VERSION ""

NS_ :

BS_:

BU_: L_DHRR_FD L_UWB_BLE_MST_FD L_UWB_RR_FD L_UWB_BLE_SLV_FD L_UWB_FR_FD L_ROA_FR_FD L_ROA_FD L_DHRL_FD L_UWB_TRNK_FD L_UWB_FRNK_FD L_EDT_FD L_UWB_FL_FD GW_BDC_FD L_UWB_RL_FD L_SAL_FD L_WPC_FD L_TPMS_FD L_DHL_FD L_DHR_FD

BO_ 849 IAU_FD_04_200ms: 32 GW_BDC_FD
 SG_ IAU_FD_Crc4Val : 0|16@1+ (1,0) [0|0] "0" Vector__XXX
 SG_ IAU_DISPWrng_Copy_0 : 104|4@1+ (1,0) [0|0] "" Vector__XXX
 SG_ IAU_DigitalKey2Opt_Copy_0 : 120|3@1+ (1,0) [0|0] "" Vector__XXX
 SG_ IAUwFRULearnState_Copy_0 : 124|2@1+ (1,0) [0|0] "" Vector__XXX
 SG_ IAUwFPMLearnState_Copy_0 : 126|2@1+ (1,0) [0|0] "" Vector__XXX
 SG_ IAU_ValetDigitalkey_Copy_0 : 128|2@1+ (1,0) [0|0] "" Vector__XXX
 SG_ IAU_DigitalKeyNumberOpt_Copy_0 : 130|3@1+ (1,0) [0|0] "" Vector__XXX
 SG_ IAU_eSEReprogramSta_Copy_0 : 133|2@1+ (1,0) [0|0] "" Vector__XXX
 SG_ IAU_DKOwnerSwapOption_Copy_0 : 136|2@1+ (1,0) [0|0] ""  L_UWB_BLE_MST_FD,L_UWB_BLE_SLV_FD,L_UWB_FL_FD,L_UWB_FRNK_FD,L_UWB_FR_FD,L_UWB_RL_FD,L_UWB_RR_FD,L_UWB_TRNK_FD,L_WPC_FD
 SG_ IAU_DgtKeyGrpPrflRval2_Copy_0 : 139|5@1+ (1,0) [0|0] "" Vector__XXX
 SG_ IAU_StartIdentifiedProfile_Copy_ : 144|3@1+ (1,0) [0|0] "" Vector__XXX
 SG_ IAU_DigitalKeyProfileRval2_Copy_ : 147|5@1+ (1,0) [0|0] "" Vector__XXX
 SG_ IAU_NFCCard1SN_Copy_0 : 152|32@1+ (1,0) [0|0] "" Vector__XXX
 SG_ IAU_FD_AlvCnt4Val : 16|8@1+ (1,0) [0|0] "0" Vector__XXX
 SG_ IAU_StartIdentifiedProfile_Ext : 24|4@1+ (1,0) [0|0] "" Vector__XXX
 SG_ RSPA_UWBRspaExtRngSta_Copy_0 : 246|2@1+ (1,0) [0|0] "" Vector__XXX
 SG_ RSPA_CanFltSta_Copy_0 : 250|2@1+ (1,0) [0|0] "" Vector__XXX
 SG_ RSPA_BLESigErrSta_Copy_0 : 252|2@1+ (1,0) [0|0] "" Vector__XXX
 SG_ RSPA_ConStat_Copy_0 : 254|2@1+ (1,0) [0|0] "" Vector__XXX
 SG_ IAU_ProfileIDRVal_Copy_0 : 74|4@1+ (1,0) [0|0] "" Vector__XXX
 SG_ IAU_DigitalKeyProcessingSta_Copy : 80|4@1+ (1,0) [0|0] "" Vector__XXX
 SG_ IAU_DigitalKeyExit_Copy_0 : 84|4@1+ (1,0) [0|0] "" Vector__XXX
 SG_ IAU_DigitalKeyEnblRVal_Copy_0 : 88|2@1+ (1,0) [0|0] ""  L_DHL_FD,L_DHRL_FD,L_DHRR_FD,L_DHR_FD,L_UWB_BLE_MST_FD,L_UWB_BLE_SLV_FD,L_UWB_FL_FD,L_UWB_FRNK_FD,L_UWB_FR_FD,L_UWB_RL_FD,L_UWB_RR_FD,L_UWB_TRNK_FD
 SG_ IAU_OwnerPhnRegRVal_Copy_0 : 90|2@1+ (1,0) [0|0] ""  L_DHL_FD,L_DHRL_FD,L_DHRR_FD,L_DHR_FD,L_UWB_BLE_MST_FD,L_UWB_BLE_SLV_FD,L_UWB_FL_FD,L_UWB_FRNK_FD,L_UWB_FR_FD,L_UWB_RL_FD,L_UWB_RR_FD,L_UWB_TRNK_FD,L_WPC_FD
 SG_ IAU_NFCCard1RegRVal_Copy_0 : 92|2@1+ (1,0) [0|0] "" Vector__XXX
 SG_ IAU_NFCCard2RegRVal_Copy_0 : 94|2@1+ (1,0) [0|0] "" Vector__XXX

BO_ 1338 UWB_TRNK_FD_30_500ms: 16 L_UWB_TRNK_FD
 SG_ UWB_TRNK_FD_Crc30Val : 0|16@1+ (1,0) [0|0] "" Vector__XXX
 SG_ UWB_TRNK_FD_AlvCnt30Val : 16|8@1+ (1,0) [0|0] "" Vector__XXX
 SG_ UWB_TRNK_ResetOpsta : 24|2@1+ (1,0) [0|0] ""  GW_BDC_FD

BO_ 2214592800 L_ROA_FD_02_00ms: 32 L_ROA_FD
 SG_ L_ROA_FD_Crc2Val : 0|16@1+ (1,0) [0|0] "0" Vector__XXX
 SG_ L_ROA_FD_AlvCnt2Val : 16|8@1+ (1,0) [0|0] "0" Vector__XXX
 SG_ ROABDC_DataByte0 : 24|8@1+ (1,0) [0|0] ""  GW_BDC_FD
 SG_ ROABDC_DataByte1 : 32|8@1+ (1,0) [0|0] ""  GW_BDC_FD
 SG_ ROABDC_DataByte2 : 40|8@1+ (1,0) [0|0] ""  GW_BDC_FD
 SG_ ROABDC_DataByte3 : 48|8@1+ (1,0) [0|0] ""  GW_BDC_FD
 SG_ ROABDC_DataByte4 : 56|8@1+ (1,0) [0|0] ""  GW_BDC_FD
 SG_ ROABDC_DataByte5 : 64|8@1+ (1,0) [0|0] ""  GW_BDC_FD
 SG_ ROABDC_DataByte6 : 72|8@1+ (1,0) [0|0] ""  GW_BDC_FD
 SG_ ROABDC_DataByte7 : 80|8@1+ (1,0) [0|0] ""  GW_BDC_FD

BO_ 1340 SAL_FD_01_500ms: 16 L_SAL_FD
 SG_ SAL_ResetOpsta : 24|2@1+ (1,0) [0|0] ""  GW_BDC_FD

BO_ 2214592802 L_ROA_FR_FD_02_00ms: 32 L_ROA_FR_FD
 SG_ L_ROA_FR_FD_Crc2Val : 0|16@1+ (1,0) [0|0] "0" Vector__XXX
 SG_ L_ROA_FR_FD_AlvCnt2Val : 16|8@1+ (1,0) [0|0] "0" Vector__XXX
 SG_ ROA_FRBDC_DataByte0 : 24|8@1+ (1,0) [0|0] ""  L_ROA_FD
 SG_ ROA_FRBDC_DataByte1 : 32|8@1+ (1,0) [0|0] ""  L_ROA_FD
 SG_ ROA_FRBDC_DataByte2 : 40|8@1+ (1,0) [0|0] ""  L_ROA_FD
 SG_ ROA_FRBDC_DataByte3 : 48|8@1+ (1,0) [0|0] ""  L_ROA_FD
 SG_ ROA_FRBDC_DataByte4 : 56|8@1+ (1,0) [0|0] ""  L_ROA_FD
 SG_ ROA_FRBDC_DataByte5 : 64|8@1+ (1,0) [0|0] ""  L_ROA_FD
 SG_ ROA_FRBDC_DataByte6 : 72|8@1+ (1,0) [0|0] ""  L_ROA_FD
 SG_ ROA_FRBDC_DataByte7 : 80|8@1+ (1,0) [0|0] ""  L_ROA_FD

BO_ 1329 ROA_FR_FD_03_500ms: 16 L_ROA_FR_FD
 SG_ ROA_FR_ResetOpSta_Copy_0 : 24|2@1+ (1,0) [0|0] ""  GW_BDC_FD

BO_ 1328 ROA_FD_03_500ms: 16 L_ROA_FD
 SG_ ROA_ResetOpSta_Copy_0 : 24|2@1+ (1,0) [0|0] ""  GW_BDC_FD

BO_ 1331 UWB_BLE_MST_FD_30_500ms: 16 L_UWB_BLE_MST_FD
 SG_ UWB_BLE_MST_FD_Crc30Val : 0|16@1+ (1,0) [0|0] "" Vector__XXX
 SG_ UWB_BLE_MST_FD_AlvCnt30Val : 16|8@1+ (1,0) [0|0] "" Vector__XXX
 SG_ UWB_BLE_MST_ResetOpsta : 24|2@1+ (1,0) [0|0] ""  GW_BDC_FD
 SG_ UWB_BLE_MST_DeviceConnectionChec : 26|2@1+ (1,0) [0|0] ""  GW_BDC_FD

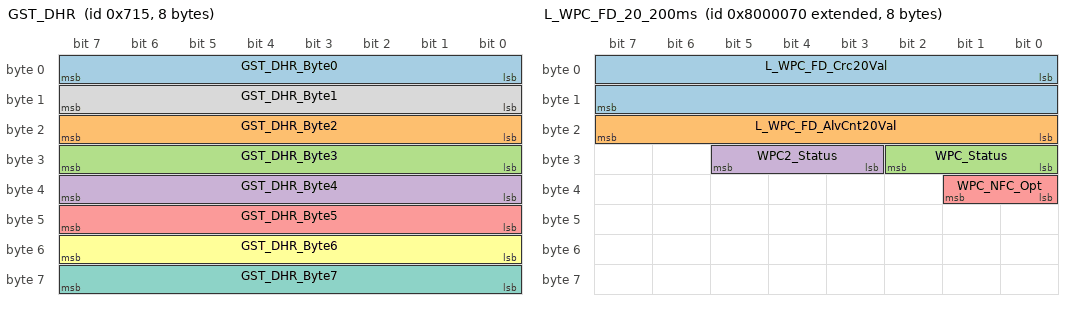
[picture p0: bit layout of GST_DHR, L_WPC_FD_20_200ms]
BO_ 1813 GST_DHR: 8 GW_BDC_FD
 SG_ GST_DHR_Byte0 : 0|8@1+ (1,0) [0|0] ""  L_DHR_FD
 SG_ GST_DHR_Byte2 : 16|8@1+ (1,0) [0|0] ""  L_DHR_FD
 SG_ GST_DHR_Byte3 : 24|8@1+ (1,0) [0|0] ""  L_DHR_FD
 SG_ GST_DHR_Byte4 : 32|8@1+ (1,0) [0|0] ""  L_DHR_FD
 SG_ GST_DHR_Byte5 : 40|8@1+ (1,0) [0|0] ""  L_DHR_FD
 SG_ GST_DHR_Byte6 : 48|8@1+ (1,0) [0|0] ""  L_DHR_FD
 SG_ GST_DHR_Byte7 : 56|8@1+ (1,0) [0|0] ""  L_DHR_FD
 SG_ GST_DHR_Byte1 : 8|8@1+ (1,0) [0|0] ""  L_DHR_FD

BO_ 1330 TPMS_FD_03_500ms: 16 L_TPMS_FD
 SG_ TPMS_FD_Crc3Val : 0|16@1+ (1,0) [0|0] "" Vector__XXX
 SG_ TPMS_FD_AlvCnt3Val : 16|8@1+ (1,0) [0|0] "" Vector__XXX
 SG_ TPMS_ResetOpsta : 24|2@1+ (1,0) [0|0] ""  GW_BDC_FD

BO_ 1333 UWB_FL_FD_30_500ms: 16 L_UWB_FL_FD
 SG_ UWB_FL_FD_Crc30Val : 0|16@1+ (1,0) [0|0] "" Vector__XXX
 SG_ UWB_FL_FD_AlvCnt30Val : 16|8@1+ (1,0) [0|0] "" Vector__XXX
 SG_ UWB_FL_ResetOpsta : 24|2@1+ (1,0) [0|0] ""  GW_BDC_FD

BO_ 1332 UWB_BLE_SLV_FD_30_500ms: 16 L_UWB_BLE_SLV_FD
 SG_ UWB_BLE_SLV_FD_Crc30Val : 0|16@1+ (1,0) [0|0] "" Vector__XXX
 SG_ UWB_BLE_SLV_FD_AlvCnt30Val : 16|8@1+ (1,0) [0|0] "" Vector__XXX
 SG_ UWB_BLE_SLV_ResetOpsta : 24|2@1+ (1,0) [0|0] ""  GW_BDC_FD
 SG_ UWB_BLE_SLV_DeviceConnectionChec : 26|2@1+ (1,0) [0|0] ""  GW_BDC_FD

BO_ 1335 UWB_FRNK_FD_30_500ms: 16 L_UWB_FRNK_FD
 SG_ UWB_FRNK_FD_Crc30Val : 0|16@1+ (1,0) [0|0] "" Vector__XXX
 SG_ UWB_FRNK_FD_AlvCnt30Val : 16|8@1+ (1,0) [0|0] "" Vector__XXX
 SG_ UWB_FRNK_ResetOpsta : 24|2@1+ (1,0) [0|0] ""  GW_BDC_FD

BO_ 2281701488 L_WPC_FD_20_200ms: 8 L_WPC_FD
 SG_ L_WPC_FD_Crc20Val : 0|16@1+ (1,0) [0|0] "0" Vector__XXX
 SG_ L_WPC_FD_AlvCnt20Val : 16|8@1+ (1,0) [0|0] "0" Vector__XXX
 SG_ WPC_Status : 24|3@1+ (1,0) [0|0] ""  GW_BDC_FD
 SG_ WPC2_Status : 27|3@1+ (1,0) [0|0] ""  GW_BDC_FD
 SG_ WPC_NFC_Opt : 32|2@1+ (1,0) [0|0] ""  GW_BDC_FD

BO_ 1334 UWB_FR_FD_30_500ms: 16 L_UWB_FR_FD
 SG_ UWB_FR_FD_Crc30Val : 0|16@1+ (1,0) [0|0] "" Vector__XXX
 SG_ UWB_FR_FD_AlvCnt30Val : 16|8@1+ (1,0) [0|0] "" Vector__XXX
 SG_ UWB_FR_ResetOpsta : 24|2@1+ (1,0) [0|0] ""  GW_BDC_FD

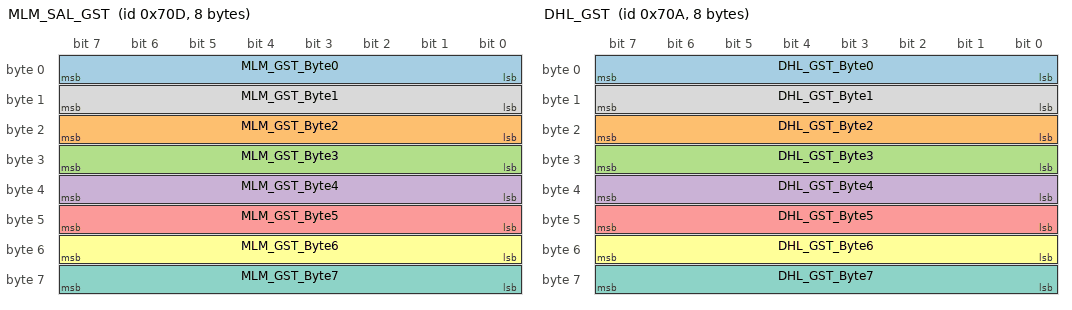
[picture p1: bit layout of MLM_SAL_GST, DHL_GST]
BO_ 1805 MLM_SAL_GST: 8 L_SAL_FD
 SG_ MLM_GST_Byte0 : 0|8@1+ (1,0) [0|0] ""  GW_BDC_FD
 SG_ MLM_GST_Byte2 : 16|8@1+ (1,0) [0|0] ""  GW_BDC_FD
 SG_ MLM_GST_Byte3 : 24|8@1+ (1,0) [0|0] ""  GW_BDC_FD
 SG_ MLM_GST_Byte4 : 32|8@1+ (1,0) [0|0] ""  GW_BDC_FD
 SG_ MLM_GST_Byte5 : 40|8@1+ (1,0) [0|0] ""  GW_BDC_FD
 SG_ MLM_GST_Byte6 : 48|8@1+ (1,0) [0|0] ""  GW_BDC_FD
 SG_ MLM_GST_Byte7 : 56|8@1+ (1,0) [0|0] ""  GW_BDC_FD
 SG_ MLM_GST_Byte1 : 8|8@1+ (1,0) [0|0] ""  GW_BDC_FD

BO_ 1802 DHL_GST: 8 L_DHL_FD
 SG_ DHL_GST_Byte0 : 0|8@1+ (1,0) [0|0] ""  GW_BDC_FD
 SG_ DHL_GST_Byte2 : 16|8@1+ (1,0) [0|0] ""  GW_BDC_FD
 SG_ DHL_GST_Byte3 : 24|8@1+ (1,0) [0|0] ""  GW_BDC_FD
 SG_ DHL_GST_Byte4 : 32|8@1+ (1,0) [0|0] ""  GW_BDC_FD
 SG_ DHL_GST_Byte5 : 40|8@1+ (1,0) [0|0] ""  GW_BDC_FD
 SG_ DHL_GST_Byte6 : 48|8@1+ (1,0) [0|0] ""  GW_BDC_FD
 SG_ DHL_GST_Byte7 : 56|8@1+ (1,0) [0|0] ""  GW_BDC_FD
 SG_ DHL_GST_Byte1 : 8|8@1+ (1,0) [0|0] ""  GW_BDC_FD

BO_ 2521142785 L_UWB_BLE_SLV_FD_10_00ms: 32 L_UWB_BLE_SLV_FD
 SG_ L_UWB_BLE_SLV_FD_Crc10Val : 0|16@1+ (1,0) [0|0] "" Vector__XXX
 SG_ L_UWB_BLE_SLV_FD_AlvCnt10Val : 16|8@1+ (1,0) [0|0] "" Vector__XXX
 SG_ SLV_SWID_2_IVD_2 : 24|24@1+ (1,0) [0|0] ""  L_UWB_BLE_MST_FD

BO_ 2533739009 L_UWB_FRNK_FD_06_00ms: 32 L_UWB_FRNK_FD
 SG_ L_UWB_FRNK_FD_Crc6Val : 0|16@1+ (1,0) [0|0] "" Vector__XXX
 SG_ L_UWB_FRNK_FD_AlvCnt6Val : 16|8@1+ (1,0) [0|0] "" Vector__XXX
 SG_ FRNK_SWID_4_IVD_1 : 24|232@1+ (1,0) [0|0] ""  L_UWB_BLE_MST_FD

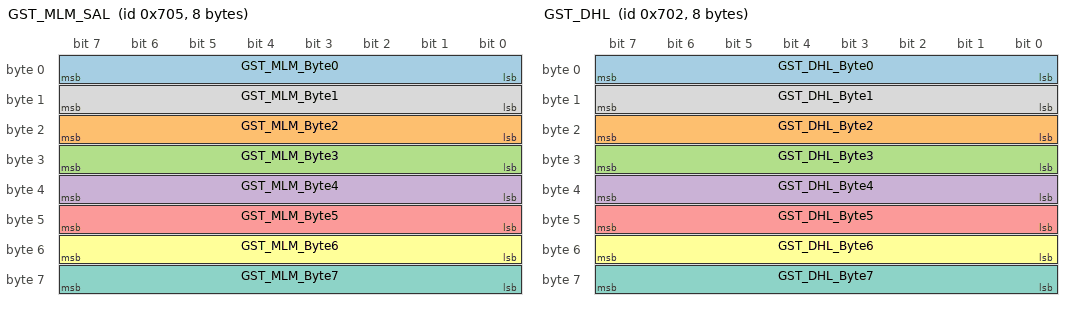
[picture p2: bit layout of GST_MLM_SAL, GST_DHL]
BO_ 1797 GST_MLM_SAL: 8 GW_BDC_FD
 SG_ GST_MLM_Byte0 : 0|8@1+ (1,0) [0|0] ""  L_SAL_FD
 SG_ GST_MLM_Byte2 : 16|8@1+ (1,0) [0|0] ""  L_SAL_FD
 SG_ GST_MLM_Byte3 : 24|8@1+ (1,0) [0|0] ""  L_SAL_FD
 SG_ GST_MLM_Byte4 : 32|8@1+ (1,0) [0|0] ""  L_SAL_FD
 SG_ GST_MLM_Byte5 : 40|8@1+ (1,0) [0|0] ""  L_SAL_FD
 SG_ GST_MLM_Byte6 : 48|8@1+ (1,0) [0|0] ""  L_SAL_FD
 SG_ GST_MLM_Byte7 : 56|8@1+ (1,0) [0|0] ""  L_SAL_FD
 SG_ GST_MLM_Byte1 : 8|8@1+ (1,0) [0|0] ""  L_SAL_FD

BO_ 2529540609 L_UWB_RR_FD_06_00ms: 32 L_UWB_RR_FD
 SG_ L_UWB_RR_FD_Crc6Val : 0|16@1+ (1,0) [0|0] "" Vector__XXX
 SG_ L_UWB_RR_FD_AlvCnt6Val : 16|8@1+ (1,0) [0|0] "" Vector__XXX
 SG_ RR_SWID_4_IVD_1 : 24|232@1+ (1,0) [0|0] ""  L_UWB_BLE_MST_FD

BO_ 1794 GST_DHL: 8 GW_BDC_FD
 SG_ GST_DHL_Byte0 : 0|8@1+ (1,0) [0|0] ""  L_DHL_FD
 SG_ GST_DHL_Byte2 : 16|8@1+ (1,0) [0|0] ""  L_DHL_FD
 SG_ GST_DHL_Byte3 : 24|8@1+ (1,0) [0|0] ""  L_DHL_FD
 SG_ GST_DHL_Byte4 : 32|8@1+ (1,0) [0|0] ""  L_DHL_FD
 SG_ GST_DHL_Byte5 : 40|8@1+ (1,0) [0|0] ""  L_DHL_FD
 SG_ GST_DHL_Byte6 : 48|8@1+ (1,0) [0|0] ""  L_DHL_FD
 SG_ GST_DHL_Byte7 : 56|8@1+ (1,0) [0|0] ""  L_DHL_FD
 SG_ GST_DHL_Byte1 : 8|8@1+ (1,0) [0|0] ""  L_DHL_FD

BO_ 362 ADAS_PRK_21_20ms: 32 GW_BDC_FD
 SG_ ADAS_PRK_Crc3Val : 0|16@1+ (1,0) [0|0] "" Vector__XXX
 SG_ RSPA_Var : 112|4@1+ (1,0) [0|0] "" Vector__XXX
 SG_ MRA_FuncEquipSta : 116|4@1+ (1,0) [0|0] "" Vector__XXX
 SG_ RSPA_Sta : 120|4@1+ (1,0) [0|0] "" Vector__XXX
 SG_ RSPA_Actv : 124|2@1+ (1,0) [0|0] "" Vector__XXX
 SG_ RSPA_EntryFuncBtnDispSta : 126|2@1+ (1,0) [0|0] "" Vector__XXX
 SG_ RSPA_TrgtGearSta : 128|3@1+ (1,0) [0|0] "" Vector__XXX
 SG_ RSPA_EpbReq : 131|2@1+ (1,0) [0|0] "" Vector__XXX
 SG_ RSPA_ExtLampReq : 133|3@1+ (1,0) [0|0] "" Vector__XXX
 SG_ RSPA_CrankingReq : 136|2@1+ (1,0) [0|0] "" Vector__XXX
 SG_ RSPA_IdOutWarnReq : 138|2@1+ (1,0) [0|0] "" Vector__XXX
 SG_ RSPA_IndBlnkReq : 140|3@1+ (1,0) [0|0] "" Vector__XXX
 SG_ RSPA_SysOff : 143|1@1+ (1,0) [0|0] "" Vector__XXX
 SG_ RSPA_DccCmd : 144|2@1+ (1,0) [0|0] "" Vector__XXX
 SG_ RSPA_StopReq : 146|2@1+ (1,0) [0|0] "" Vector__XXX
 SG_ RSPA_SelDevInfo : 148|2@1+ (1,0) [0|0] "" Vector__XXX
 SG_ RSPA_SelFuncSta : 150|2@1+ (1,0) [0|0] "" Vector__XXX
 SG_ RSPA_TrgtVehSpdVal : 152|10@1+ (0.01,0) [0|0] "km/h" Vector__XXX
 SG_ ADAS_PRK_AlvCnt3Val : 16|8@1+ (1,0) [0|0] "" Vector__XXX
 SG_ RSPA_AddtnlAccelActv : 162|2@1+ (1,0) [0|0] "" Vector__XXX
 SG_ RSPA_Opt : 164|2@1+ (1,0) [0|0] ""  L_UWB_BLE_MST_FD
 SG_ RSPA_TrgtTqVal : 168|12@1- (1,0) [0|0] "Nm" Vector__XXX
 SG_ RSPA_UppLtTypDis : 180|3@1+ (1,0) [0|0] "" Vector__XXX
 SG_ RSPA_LwrLtTypDis : 183|3@1+ (1,0) [0|0] "" Vector__XXX
 SG_ RSPA_UppRtTypDis : 186|3@1+ (1,0) [0|0] "" Vector__XXX
 SG_ RSPA_LwrRtTypDis : 189|3@1+ (1,0) [0|0] "" Vector__XXX
 SG_ RSPA_DCTTrgtTqVal : 192|12@1- (1,0) [0|0] "Nm" Vector__XXX
 SG_ MRA_BtnDispSta : 204|4@1+ (1,0) [0|0] "" Vector__XXX
 SG_ RSPA_AvnDis : 24|2@1+ (1,0) [0|0] "" Vector__XXX
 SG_ RSPA_HdLmpReq : 240|2@1+ (1,0) [0|0] "" Vector__XXX
 SG_ MRA_CamDispSta : 242|3@1+ (1,0) [0|0] "" Vector__XXX
 SG_ RSPA_BtnDispSta : 245|3@1+ (1,0) [0|0] "" Vector__XXX
 SG_ RSPA_OSMirFoldReq : 248|2@1+ (1,0) [0|0] "" Vector__XXX
 SG_ RSPA_AvnModDis : 26|2@1+ (1,0) [0|0] "" Vector__XXX
 SG_ RSPA_AvnSubViewDis : 32|2@1+ (1,0) [0|0] "" Vector__XXX
 SG_ MRA_AVNDispSta : 48|2@1+ (1,0) [0|0] "" Vector__XXX
 SG_ RSPA_DgtKeyVer : 53|3@1+ (1,0) [0|0] "" Vector__XXX
 SG_ RSPA_AvnHmiDis : 56|8@1+ (1,0) [0|0] "" Vector__XXX
 SG_ MRA_AVNHMIDispSta : 64|8@1+ (1,0) [0|0] "" Vector__XXX
 SG_ RSPA_RWS_AnglReq : 72|8@1+ (0.1,-12.7) [0|0] "Degree" Vector__XXX

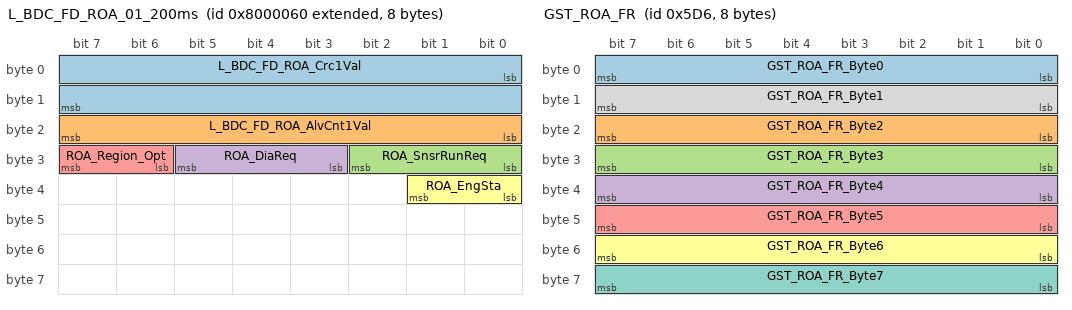
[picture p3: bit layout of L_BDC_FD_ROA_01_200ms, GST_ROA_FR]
BO_ 2281701472 L_BDC_FD_ROA_01_200ms: 8 GW_BDC_FD
 SG_ L_BDC_FD_ROA_Crc1Val : 0|16@1+ (1,0) [0|0] "0" Vector__XXX
 SG_ L_BDC_FD_ROA_AlvCnt1Val : 16|8@1+ (1,0) [0|0] "0" Vector__XXX
 SG_ ROA_SnsrRunReq : 24|3@1+ (1,0) [0|0] ""  L_ROA_FD,L_ROA_FR_FD
 SG_ ROA_DiaReq : 27|3@1+ (1,0) [0|0] ""  L_ROA_FD,L_ROA_FR_FD
 SG_ ROA_Region_Opt : 30|2@1+ (1,0) [0|0] ""  L_ROA_FD,L_ROA_FR_FD
 SG_ ROA_EngSta : 32|2@1+ (1,0) [0|0] ""  L_ROA_FD,L_ROA_FR_FD,L_UWB_BLE_MST_FD,L_UWB_BLE_SLV_FD

BO_ 2683310288 L_ROA_FR_FD_Debug_01: 32 L_ROA_FR_FD
 SG_ ROA_FR_Debug_00 : 0|64@1+ (1,0) [0|0] "" Vector__XXX
 SG_ ROA_FR_Debug_02 : 128|64@1+ (1,0) [0|0] "" Vector__XXX
 SG_ ROA_FR_Debug_03 : 192|64@1+ (1,0) [0|0] "" Vector__XXX
 SG_ ROA_FR_Debug_01 : 64|64@1+ (1,0) [0|0] "" Vector__XXX

BO_ 1494 GST_ROA_FR: 8 GW_BDC_FD
 SG_ GST_ROA_FR_Byte0 : 0|8@1+ (1,0) [0|0] ""  L_ROA_FR_FD
 SG_ GST_ROA_FR_Byte2 : 16|8@1+ (1,0) [0|0] ""  L_ROA_FR_FD
 SG_ GST_ROA_FR_Byte3 : 24|8@1+ (1,0) [0|0] ""  L_ROA_FR_FD
 SG_ GST_ROA_FR_Byte4 : 32|8@1+ (1,0) [0|0] ""  L_ROA_FR_FD
 SG_ GST_ROA_FR_Byte5 : 40|8@1+ (1,0) [0|0] ""  L_ROA_FR_FD
 SG_ GST_ROA_FR_Byte6 : 48|8@1+ (1,0) [0|0] ""  L_ROA_FR_FD
 SG_ GST_ROA_FR_Byte7 : 56|8@1+ (1,0) [0|0] ""  L_ROA_FR_FD
 SG_ GST_ROA_FR_Byte1 : 8|8@1+ (1,0) [0|0] ""  L_ROA_FR_FD

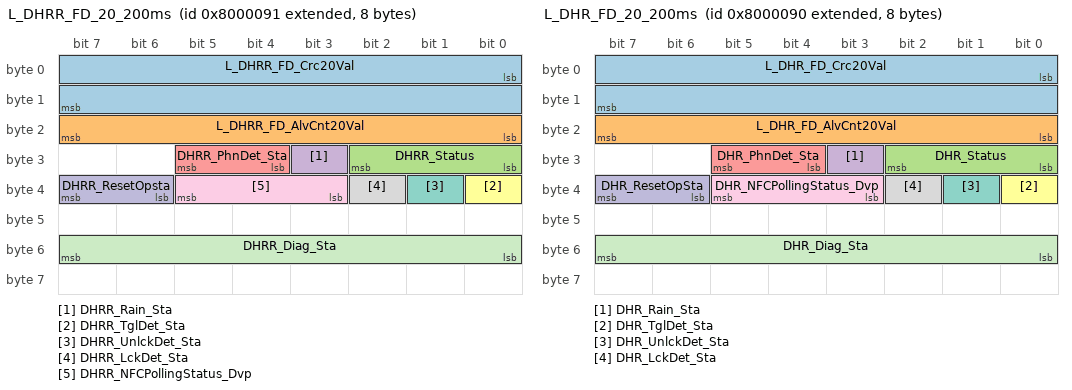
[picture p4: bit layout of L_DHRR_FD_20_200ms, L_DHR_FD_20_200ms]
BO_ 2281701521 L_DHRR_FD_20_200ms: 8 L_DHRR_FD
 SG_ L_DHRR_FD_Crc20Val : 0|16@1+ (1,0) [0|0] "0" Vector__XXX
 SG_ L_DHRR_FD_AlvCnt20Val : 16|8@1+ (1,0) [0|0] "0" Vector__XXX
 SG_ DHRR_Status : 24|3@1+ (1,0) [0|0] ""  GW_BDC_FD
 SG_ DHRR_Rain_Sta : 27|1@1+ (1,0) [0|0] ""  GW_BDC_FD
 SG_ DHRR_PhnDet_Sta : 28|2@1+ (1,0) [0|0] ""  GW_BDC_FD
 SG_ DHRR_TglDet_Sta : 32|1@1+ (1,0) [0|0] ""  GW_BDC_FD,L_UWB_BLE_MST_FD
 SG_ DHRR_UnlckDet_Sta : 33|1@1+ (1,0) [0|0] ""  GW_BDC_FD,L_UWB_BLE_MST_FD
 SG_ DHRR_LckDet_Sta : 34|1@1+ (1,0) [0|0] ""  GW_BDC_FD,L_UWB_BLE_MST_FD
 SG_ DHRR_NFCPollingStatus_Dvp : 35|3@1+ (1,0) [0|0] ""  GW_BDC_FD
 SG_ DHRR_ResetOpsta : 38|2@1+ (1,0) [0|0] ""  GW_BDC_FD
 SG_ DHRR_Diag_Sta : 48|8@1+ (1,0) [0|0] ""  GW_BDC_FD

BO_ 2683310289 L_ROA_FR_FD_Debug_02: 32 L_ROA_FR_FD
 SG_ ROA_FR_Debug_04 : 0|64@1+ (1,0) [0|0] "" Vector__XXX
 SG_ ROA_FR_Debug_06 : 128|64@1+ (1,0) [0|0] "" Vector__XXX
 SG_ ROA_FR_Debug_07 : 192|64@1+ (1,0) [0|0] "" Vector__XXX
 SG_ ROA_FR_Debug_05 : 64|64@1+ (1,0) [0|0] "" Vector__XXX

BO_ 2281701520 L_DHR_FD_20_200ms: 8 L_DHR_FD
 SG_ L_DHR_FD_Crc20Val : 0|16@1+ (1,0) [0|0] "0" Vector__XXX
 SG_ L_DHR_FD_AlvCnt20Val : 16|8@1+ (1,0) [0|0] "0" Vector__XXX
 SG_ DHR_Status : 24|3@1+ (1,0) [0|0] ""  GW_BDC_FD
 SG_ DHR_Rain_Sta : 27|1@1+ (1,0) [0|0] ""  GW_BDC_FD
 SG_ DHR_PhnDet_Sta : 28|2@1+ (1,0) [0|0] ""  GW_BDC_FD
 SG_ DHR_TglDet_Sta : 32|1@1+ (1,0) [0|0] ""  GW_BDC_FD,L_UWB_BLE_MST_FD
 SG_ DHR_UnlckDet_Sta : 33|1@1+ (1,0) [0|0] ""  GW_BDC_FD,L_UWB_BLE_MST_FD
 SG_ DHR_LckDet_Sta : 34|1@1+ (1,0) [0|0] ""  GW_BDC_FD,L_UWB_BLE_MST_FD
 SG_ DHR_NFCPollingStatus_Dvp : 35|3@1+ (1,0) [0|0] ""  GW_BDC_FD
 SG_ DHR_ResetOpSta : 38|2@1+ (1,0) [0|0] ""  GW_BDC_FD
 SG_ DHR_Diag_Sta : 48|8@1+ (1,0) [0|0] ""  GW_BDC_FD

BO_ 2683310290 L_ROA_FR_FD_Debug_03: 8 L_ROA_FR_FD
 SG_ ROA_FR_Debug_08 : 0|64@1+ (1,0) [0|0] "" Vector__XXX

BO_ 2521143297 L_UWB_BLE_SLV_FD_12_00ms: 32 L_UWB_BLE_SLV_FD
 SG_ L_UWB_BLE_SLV_FD_Crc12Val : 0|16@1+ (1,0) [0|0] "" Vector__XXX
 SG_ L_UWB_BLE_SLV_FD_AlvCnt12Val : 16|8@1+ (1,0) [0|0] "" Vector__XXX
 SG_ SLV_SWID_3_IVD_2 : 24|24@1+ (1,0) [0|0] ""  L_UWB_BLE_MST_FD

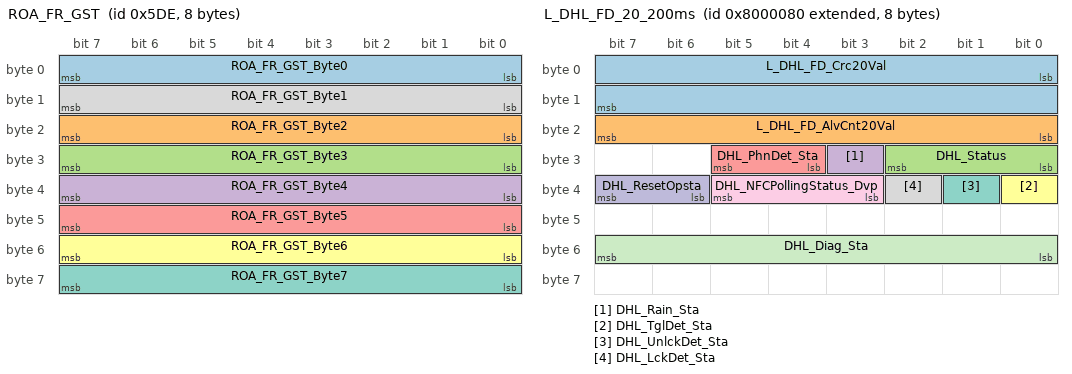
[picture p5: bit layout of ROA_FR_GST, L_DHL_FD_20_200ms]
BO_ 1502 ROA_FR_GST: 8 L_ROA_FR_FD
 SG_ ROA_FR_GST_Byte0 : 0|8@1+ (1,0) [0|0] ""  GW_BDC_FD
 SG_ ROA_FR_GST_Byte2 : 16|8@1+ (1,0) [0|0] ""  GW_BDC_FD
 SG_ ROA_FR_GST_Byte3 : 24|8@1+ (1,0) [0|0] ""  GW_BDC_FD
 SG_ ROA_FR_GST_Byte4 : 32|8@1+ (1,0) [0|0] ""  GW_BDC_FD
 SG_ ROA_FR_GST_Byte5 : 40|8@1+ (1,0) [0|0] ""  GW_BDC_FD
 SG_ ROA_FR_GST_Byte6 : 48|8@1+ (1,0) [0|0] ""  GW_BDC_FD
 SG_ ROA_FR_GST_Byte7 : 56|8@1+ (1,0) [0|0] ""  GW_BDC_FD
 SG_ ROA_FR_GST_Byte1 : 8|8@1+ (1,0) [0|0] ""  GW_BDC_FD

BO_ 2683310273 L_ROA_FR_FD_Dev_01: 8 L_ROA_FR_FD
 SG_ ROA_FR_Dev_01 : 0|64@1+ (1,0) [0|0] "" Vector__XXX

BO_ 2281701504 L_DHL_FD_20_200ms: 8 L_DHL_FD
 SG_ L_DHL_FD_Crc20Val : 0|16@1+ (1,0) [0|0] "0" Vector__XXX
 SG_ L_DHL_FD_AlvCnt20Val : 16|8@1+ (1,0) [0|0] "0" Vector__XXX
 SG_ DHL_Status : 24|3@1+ (1,0) [0|0] ""  GW_BDC_FD
 SG_ DHL_Rain_Sta : 27|1@1+ (1,0) [0|0] ""  GW_BDC_FD
 SG_ DHL_PhnDet_Sta : 28|2@1+ (1,0) [0|0] ""  GW_BDC_FD
 SG_ DHL_TglDet_Sta : 32|1@1+ (1,0) [0|0] ""  GW_BDC_FD,L_UWB_BLE_MST_FD
 SG_ DHL_UnlckDet_Sta : 33|1@1+ (1,0) [0|0] ""  GW_BDC_FD,L_UWB_BLE_MST_FD
 SG_ DHL_LckDet_Sta : 34|1@1+ (1,0) [0|0] ""  GW_BDC_FD,L_UWB_BLE_MST_FD
 SG_ DHL_NFCPollingStatus_Dvp : 35|3@1+ (1,0) [0|0] ""  GW_BDC_FD
 SG_ DHL_ResetOpsta : 38|2@1+ (1,0) [0|0] ""  GW_BDC_FD
 SG_ DHL_Diag_Sta : 48|8@1+ (1,0) [0|0] ""  GW_BDC_FD

BO_ 2683310272 L_ROA_FR_FD_Dev_00: 8 L_ROA_FR_FD
 SG_ ROA_FR_Dev_00 : 0|64@1+ (1,0) [0|0] "" Vector__XXX

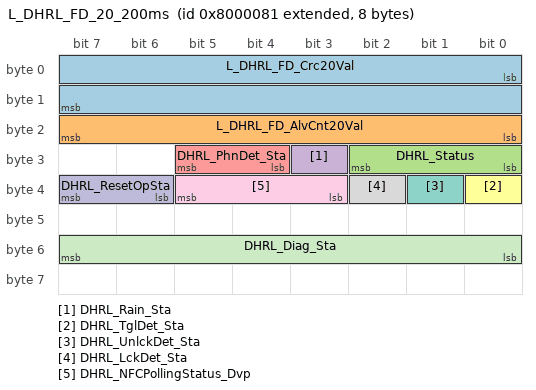
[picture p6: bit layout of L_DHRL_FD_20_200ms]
BO_ 2281701505 L_DHRL_FD_20_200ms: 8 L_DHRL_FD
 SG_ L_DHRL_FD_Crc20Val : 0|16@1+ (1,0) [0|0] "0" Vector__XXX
 SG_ L_DHRL_FD_AlvCnt20Val : 16|8@1+ (1,0) [0|0] "0" Vector__XXX
 SG_ DHRL_Status : 24|3@1+ (1,0) [0|0] ""  GW_BDC_FD
 SG_ DHRL_Rain_Sta : 27|1@1+ (1,0) [0|0] ""  GW_BDC_FD
 SG_ DHRL_PhnDet_Sta : 28|2@1+ (1,0) [0|0] ""  GW_BDC_FD
 SG_ DHRL_TglDet_Sta : 32|1@1+ (1,0) [0|0] ""  GW_BDC_FD,L_UWB_BLE_MST_FD
 SG_ DHRL_UnlckDet_Sta : 33|1@1+ (1,0) [0|0] ""  GW_BDC_FD,L_UWB_BLE_MST_FD
 SG_ DHRL_LckDet_Sta : 34|1@1+ (1,0) [0|0] ""  GW_BDC_FD,L_UWB_BLE_MST_FD
 SG_ DHRL_NFCPollingStatus_Dvp : 35|3@1+ (1,0) [0|0] ""  GW_BDC_FD
 SG_ DHRL_ResetOpSta : 38|2@1+ (1,0) [0|0] ""  GW_BDC_FD
 SG_ DHRL_Diag_Sta : 48|8@1+ (1,0) [0|0] ""  GW_BDC_FD

BO_ 2683310275 L_ROA_FR_FD_Dev_03: 8 L_ROA_FR_FD
 SG_ ROA_FR_Dev_03 : 0|64@1+ (1,0) [0|0] "" Vector__XXX

BO_ 2683310274 L_ROA_FR_FD_Dev_02: 8 L_ROA_FR_FD
 SG_ ROA_FR_Dev_02 : 0|64@1+ (1,0) [0|0] "" Vector__XXX

BO_ 2683310277 L_ROA_FR_FD_Dev_05: 8 L_ROA_FR_FD
 SG_ ROA_FR_Dev_05 : 0|64@1+ (1,0) [0|0] "" Vector__XXX

BO_ 2525340417 L_UWB_FL_FD_07_00ms: 32 L_UWB_FL_FD
 SG_ L_UWB_FL_FD_Crc7Val : 0|16@1+ (1,0) [0|0] "" Vector__XXX
 SG_ L_UWB_FL_FD_AlvCnt7Val : 16|8@1+ (1,0) [0|0] "" Vector__XXX
 SG_ FL_SWID_4_IVD_2 : 24|24@1+ (1,0) [0|0] ""  L_UWB_BLE_MST_FD

BO_ 2683310276 L_ROA_FR_FD_Dev_04: 8 L_ROA_FR_FD
 SG_ ROA_FR_Dev_04 : 0|64@1+ (1,0) [0|0] "" Vector__XXX

BO_ 2683310279 L_ROA_FR_FD_Dev_07: 8 L_ROA_FR_FD
 SG_ ROA_FR_Dev_07 : 0|64@1+ (1,0) [0|0] "" Vector__XXX

BO_ 2683310278 L_ROA_FR_FD_Dev_06: 8 L_ROA_FR_FD
 SG_ ROA_FR_Dev_06 : 0|64@1+ (1,0) [0|0] "" Vector__XXX

BO_ 2683310281 L_ROA_FR_FD_Dev_09: 8 L_ROA_FR_FD
 SG_ ROA_FR_Dev_09 : 0|64@1+ (1,0) [0|0] "" Vector__XXX

BO_ 2683310280 L_ROA_FR_FD_Dev_08: 8 L_ROA_FR_FD
 SG_ ROA_FR_Dev_08 : 0|64@1+ (1,0) [0|0] "" Vector__XXX

BO_ 2683310282 L_ROA_FR_FD_Dev_10: 8 L_ROA_FR_FD
 SG_ ROA_FR_Dev_10 : 0|64@1+ (1,0) [0|0] "" Vector__XXX

BO_ 2521143809 L_UWB_BLE_SLV_FD_14_00ms: 32 L_UWB_BLE_SLV_FD
 SG_ L_UWB_BLE_SLV_FD_Crc14Val : 0|16@1+ (1,0) [0|0] "" Vector__XXX
 SG_ L_UWB_BLE_SLV_FD_AlvCnt14Val : 16|8@1+ (1,0) [0|0] "" Vector__XXX
 SG_ SLV_SWID_4_IVD_2 : 24|24@1+ (1,0) [0|0] ""  L_UWB_BLE_MST_FD

BO_ 2281701553 L_UWB_BLE_SLV_FD_21_200ms: 24 L_UWB_BLE_SLV_FD
 SG_ L_UWB_BLE_SLV_FD_Crc21Val : 0|16@1+ (1,0) [0|0] "0" Vector__XXX
 SG_ SLV_SW_MCU_Ver_Major : 104|8@1+ (1,0) [0|0] ""  L_UWB_BLE_MST_FD
 SG_ SLV_SW_MCU_Ver_Minor : 112|8@1+ (1,0) [0|0] ""  L_UWB_BLE_MST_FD
 SG_ SLV_SW_UWB_Ver_Major : 120|8@1+ (1,0) [0|0] ""  L_UWB_BLE_MST_FD
 SG_ SLV_SW_UWB_Ver_Minor : 128|8@1+ (1,0) [0|0] ""  L_UWB_BLE_MST_FD
 SG_ SLV_SW_BLE_Ver_Major : 136|8@1+ (1,0) [0|0] ""  L_UWB_BLE_MST_FD
 SG_ SLV_SW_BLE_Ver_Minor : 144|8@1+ (1,0) [0|0] ""  L_UWB_BLE_MST_FD
 SG_ SLV_DTC : 152|8@1+ (1,0) [0|0] ""  L_UWB_BLE_MST_FD
 SG_ L_UWB_BLE_SLV_FD_AlvCnt21Val : 16|8@1+ (1,0) [0|0] "0" Vector__XXX
 SG_ SLV_DTC_BLE : 160|8@1+ (1,0) [0|0] ""  L_UWB_BLE_MST_FD
 SG_ SLV_UWB_Status1 : 24|4@1+ (1,0) [0|7] ""  GW_BDC_FD,L_UWB_BLE_MST_FD
 SG_ SLV_UWB_Status2 : 28|4@1+ (1,0) [0|0] ""  GW_BDC_FD,L_UWB_BLE_MST_FD
 SG_ SLV_UWB_Status3 : 32|4@1+ (1,0) [0|0] ""  GW_BDC_FD,L_UWB_BLE_MST_FD
 SG_ SLV_UWB_Status4 : 36|4@1+ (1,0) [0|0] ""  GW_BDC_FD,L_UWB_BLE_MST_FD
 SG_ SLV_UWB_Status5 : 40|4@1+ (1,0) [0|0] ""  GW_BDC_FD,L_UWB_BLE_MST_FD
 SG_ SLV_UWB_Status6 : 44|4@1+ (1,0) [0|0] ""  GW_BDC_FD,L_UWB_BLE_MST_FD
 SG_ SLV_UWB_Status7 : 48|4@1+ (1,0) [0|0] ""  GW_BDC_FD,L_UWB_BLE_MST_FD
 SG_ SLV_UWB_Status8 : 52|4@1+ (1,0) [0|0] ""  GW_BDC_FD,L_UWB_BLE_MST_FD
 SG_ SLV_UWB_Status9 : 56|4@1+ (1,0) [0|0] ""  GW_BDC_FD,L_UWB_BLE_MST_FD
 SG_ SLV_UWB_Status10 : 60|4@1+ (1,0) [0|0] ""  GW_BDC_FD,L_UWB_BLE_MST_FD
 SG_ SLV_UWB_Status11 : 64|4@1+ (1,0) [0|0] ""  GW_BDC_FD,L_UWB_BLE_MST_FD
 SG_ SLV_UWB_Status12 : 68|4@1+ (1,0) [0|0] ""  GW_BDC_FD,L_UWB_BLE_MST_FD
 SG_ SLV_UWB_Status13 : 72|4@1+ (1,0) [0|0] ""  GW_BDC_FD,L_UWB_BLE_MST_FD
 SG_ SLV_UWB_Status14 : 76|4@1+ (1,0) [0|0] ""  GW_BDC_FD,L_UWB_BLE_MST_FD
 SG_ SLV_UWB_Status15 : 80|4@1+ (1,0) [0|0] ""  GW_BDC_FD,L_UWB_BLE_MST_FD
 SG_ SLV_UWB_Status16 : 84|4@1+ (1,0) [0|0] ""  GW_BDC_FD,L_UWB_BLE_MST_FD
 SG_ SLV_HW_Ver_Major : 88|8@1+ (1,0) [0|0] ""  L_UWB_BLE_MST_FD
 SG_ SLV_HW_Ver_Minor : 96|8@1+ (1,0) [0|0] ""  L_UWB_BLE_MST_FD

CM_ BO_ 849 "[PE] Periodic and On Event";
CM_ SG_ 849 IAU_FD_Crc4Val "IAU_FD_CyclicRedundancyCheck4Value";
CM_ SG_ 849 IAU_DigitalKey2Opt_Copy_0 "Digital Key2 Option Signal";
CM_ SG_ 849 IAU_ValetDigitalkey_Copy_0 "Digital Key Valet Mode";
CM_ SG_ 849 IAU_DigitalKeyNumberOpt_Copy_0 "This signal is for the digital key number type.";
CM_ SG_ 849 IAU_eSEReprogramSta_Copy_0 "this signal is to mornitor the state of eSE reprograming.";
CM_ SG_ 849 IAU_DgtKeyGrpPrflRval2_Copy_0 "This signal indiactes digital key group number paired with selected profile";
CM_ SG_ 849 IAU_StartIdentifiedProfile_Copy_ "This signal Indicate Profile of vehicle start Identified";
CM_ SG_ 849 IAU_DigitalKeyProfileRval2_Copy_ "This signal indiactes digital key number paired with selected profile";
CM_ SG_ 849 IAU_FD_AlvCnt4Val "IAU_FD_AliveCounter4Value";
CM_ SG_ 849 IAU_StartIdentifiedProfile_Ext "This signal indicate Profile of vehicle start Identified";
CM_ SG_ 849 RSPA_UWBRspaExtRngSta_Copy_0 "RSPA remote control range of UWB";
CM_ SG_ 849 RSPA_CanFltSta_Copy_0 "RSPA_CANErrorState";
CM_ SG_ 849 RSPA_BLESigErrSta_Copy_0 "RSPA_RFSignalErrorState";
CM_ SG_ 849 IAU_ProfileIDRVal_Copy_0 "This signal Indicate the Current detected Profile ID by IAU.";
CM_ SG_ 849 IAU_DigitalKeyProcessingSta_Copy "Digital Key USM settitng Process State";
CM_ SG_ 849 IAU_DigitalKeyExit_Copy_0 "Digital Key USM setting Exit Condition";
CM_ SG_ 849 IAU_DigitalKeyEnblRVal_Copy_0 "Digital Key Function Enable / Disable flag (Fob is required for changing flag)";
CM_ SG_ 849 IAU_OwnerPhnRegRVal_Copy_0 "Vehicle Owner's Phone is Registered for Digital Key function";
CM_ SG_ 849 IAU_NFCCard1RegRVal_Copy_0 "NFC Card 1 is Registered for Digital Key function";
CM_ SG_ 849 IAU_NFCCard2RegRVal_Copy_0 "NFC Card 2 is Registered for Digital Key function";
CM_ BO_ 1338 "[PE] Periodic and On Event";
CM_ SG_ 1338 UWB_TRNK_FD_Crc30Val "UWB_TRNK_FD_CyclicRedundancyCheck30Value";
CM_ SG_ 1338 UWB_TRNK_FD_AlvCnt30Val "UWB_TRNK_FD_AliveCounter30Value";
CM_ SG_ 1338 UWB_TRNK_ResetOpsta "This signal indicates whether the reset operation has been completed or not";
CM_ BO_ 2214592800 "[EW] On Event and On Write";
CM_ SG_ 2214592800 L_ROA_FD_Crc2Val "L_ROA_FD_CyclicRedundancyCheck2Value";
CM_ SG_ 2214592800 L_ROA_FD_AlvCnt2Val "L_ROA_FD_AliveCounter2Value";
CM_ SG_ 2214592800 ROABDC_DataByte0 "Response of Parameter Update";
CM_ SG_ 2214592800 ROABDC_DataByte1 "Response of Parameter Update";
CM_ SG_ 2214592800 ROABDC_DataByte2 "Response of Parameter Update";
CM_ SG_ 2214592800 ROABDC_DataByte3 "Response of Parameter Update";
CM_ SG_ 2214592800 ROABDC_DataByte4 "Response of Parameter Update";
CM_ SG_ 2214592800 ROABDC_DataByte5 "Response of Parameter Update";
CM_ SG_ 2214592800 ROABDC_DataByte6 "Response of Parameter Update";
CM_ SG_ 2214592800 ROABDC_DataByte7 "Response of Parameter Update";
CM_ BO_ 1340 "[PE] Periodic and On Event";
CM_ SG_ 1340 SAL_ResetOpsta "This signal indicates whether the reset operation has been completed or not";
CM_ BO_ 2214592802 "[EW] On Event and On Write";
CM_ SG_ 2214592802 L_ROA_FR_FD_Crc2Val "L_ROA_FR_FD_CyclicRedundancyCheck2Value";
CM_ SG_ 2214592802 L_ROA_FR_FD_AlvCnt2Val "L_ROA_FR_FD_AliveCounter2Value";
CM_ SG_ 2214592802 ROA_FRBDC_DataByte0 "Response of Parameter Update";
CM_ SG_ 2214592802 ROA_FRBDC_DataByte1 "Response of Parameter Update";
CM_ SG_ 2214592802 ROA_FRBDC_DataByte2 "Response of Parameter Update";
CM_ SG_ 2214592802 ROA_FRBDC_DataByte3 "Response of Parameter Update";
CM_ SG_ 2214592802 ROA_FRBDC_DataByte4 "Response of Parameter Update";
CM_ SG_ 2214592802 ROA_FRBDC_DataByte5 "Response of Parameter Update";
CM_ SG_ 2214592802 ROA_FRBDC_DataByte6 "Response of Parameter Update";
CM_ SG_ 2214592802 ROA_FRBDC_DataByte7 "Response of Parameter Update";
CM_ BO_ 1329 "[PE] Periodic and On Event";
CM_ SG_ 1329 ROA_FR_ResetOpSta_Copy_0 "This signal indicates whether the reset operation has been completed or not";
CM_ BO_ 1328 "[PE] Periodic and On Event";
CM_ SG_ 1328 ROA_ResetOpSta_Copy_0 "This signal indicates whether the reset operation has been completed or not";
CM_ BO_ 1331 "[PE] Periodic and On Event";
CM_ SG_ 1331 UWB_BLE_MST_FD_Crc30Val "UWB_BLE_MST_FD_CyclicRedundancyCheck30Value";
CM_ SG_ 1331 UWB_BLE_MST_FD_AlvCnt30Val "UWB_BLE_MST_FD_AliveCounter30Value";
CM_ SG_ 1331 UWB_BLE_MST_ResetOpsta "This signal indicates whether the reset operation has been completed or not";
CM_ SG_ 1331 UWB_BLE_MST_DeviceConnectionChec "BLE connection status with mobile phone";
CM_ BO_ 1813 "[TP] Transport Protocol";
CM_ BO_ 1330 "[PE] Periodic and On Event";
CM_ SG_ 1330 TPMS_FD_Crc3Val "TPMS_FD_CyclicRedundancyCheck3Value";
CM_ SG_ 1330 TPMS_FD_AlvCnt3Val "TPMS_FD_AliveCounter3Value";
CM_ SG_ 1330 TPMS_ResetOpsta "This signal indicates whether the reset operation has been completed or not";
CM_ BO_ 1333 "[PE] Periodic and On Event";
CM_ SG_ 1333 UWB_FL_FD_Crc30Val "UWB_FL_FD_CyclicRedundancyCheck30Value";
CM_ SG_ 1333 UWB_FL_FD_AlvCnt30Val "UWB_FL_FD_AliveCounter30Value";
CM_ SG_ 1333 UWB_FL_ResetOpsta "This signal indicates whether the reset operation has been completed or not";
CM_ BO_ 1332 "[PE] Periodic and On Event";
CM_ SG_ 1332 UWB_BLE_SLV_FD_Crc30Val "UWB_BLE_SLV_FD_CyclicRedundancyCheck30Value";
CM_ SG_ 1332 UWB_BLE_SLV_FD_AlvCnt30Val "UWB_BLE_SLV_FD_AliveCounter30Value";
CM_ SG_ 1332 UWB_BLE_SLV_ResetOpsta "This signal indicates whether the reset operation has been completed or not";
CM_ SG_ 1332 UWB_BLE_SLV_DeviceConnectionChec "BLE connection status with mobile phone";
CM_ BO_ 1335 "[PE] Periodic and On Event";
CM_ SG_ 1335 UWB_FRNK_FD_Crc30Val "UWB_FRNK_FD_CyclicRedundancyCheck30Value";
CM_ SG_ 1335 UWB_FRNK_FD_AlvCnt30Val "UWB_FRNK_FD_AliveCounter30Value";
CM_ SG_ 1335 UWB_FRNK_ResetOpsta "This signal indicates whether the reset operation has been completed or not";
CM_ BO_ 2281701488 "[PE] Periodic and On Event";
CM_ SG_ 2281701488 L_WPC_FD_Crc20Val "L_WPC_FD_CyclicRedundancyCheck20Value";
CM_ SG_ 2281701488 L_WPC_FD_AlvCnt20Val "L_WPC_FD_AliveCounter20Value";
CM_ SG_ 2281701488 WPC_Status "WPC Processing Status";
CM_ SG_ 2281701488 WPC2_Status "WPC2 Processing Status";
CM_ SG_ 2281701488 WPC_NFC_Opt "WPC NFC Option Applied Signal";
CM_ BO_ 1334 "[PE] Periodic and On Event";
CM_ SG_ 1334 UWB_FR_FD_Crc30Val "UWB_FR_FD_CyclicRedundancyCheck30Value";
CM_ SG_ 1334 UWB_FR_FD_AlvCnt30Val "UWB_FR_FD_AliveCounter30Value";
CM_ SG_ 1334 UWB_FR_ResetOpsta "This signal indicates whether the reset operation has been completed or not";
CM_ BO_ 1805 "[TP] Transport Protocol";
CM_ BO_ 1802 "[TP] Transport Protocol";
CM_ BO_ 2521142785 "[EW] On Event and On Write";
CM_ SG_ 2521142785 L_UWB_BLE_SLV_FD_Crc10Val "L_UWB_BLE_SLV_FD_CyclicRedundancyCheck10Value";
CM_ SG_ 2521142785 L_UWB_BLE_SLV_FD_AlvCnt10Val "L_UWB_BLE_SLV_FD_AliveCounter10Value";
CM_ SG_ 2521142785 SLV_SWID_2_IVD_2 "Slave SW Unit 2 IVD2";
CM_ BO_ 2533739009 "[EW] On Event and On Write";
CM_ SG_ 2533739009 L_UWB_FRNK_FD_Crc6Val "L_UWB_FRNK_FD_CyclicRedundancyCheck6Value";
CM_ SG_ 2533739009 L_UWB_FRNK_FD_AlvCnt6Val "L_UWB_FRNK_FD_AliveCounter6Value";
CM_ SG_ 2533739009 FRNK_SWID_4_IVD_1 "UWB FRNK SW Unit 4 IVD1";
CM_ BO_ 1797 "[TP] Transport Protocol";
CM_ BO_ 2529540609 "[EW] On Event and On Write";
CM_ SG_ 2529540609 L_UWB_RR_FD_Crc6Val "L_UWB_RR_FD_CyclicRedundancyCheck6Value";
CM_ SG_ 2529540609 L_UWB_RR_FD_AlvCnt6Val "L_UWB_RR_FD_AliveCounter6Value";
CM_ SG_ 2529540609 RR_SWID_4_IVD_1 "UWB RR SW Unit 4 IVD1";
CM_ BO_ 1794 "[TP] Transport Protocol";
CM_ BO_ 362 "[P] Periodic";
CM_ SG_ 362 ADAS_PRK_Crc3Val "ADAS_PRK_CyclicRedundancyCheck3Value";
CM_ SG_ 362 RSPA_Var "RSPA_Variation";
CM_ SG_ 362 MRA_FuncEquipSta "MRA Function Equip State";
CM_ SG_ 362 RSPA_Sta "RSPA_Status";
CM_ SG_ 362 RSPA_Actv "RSPA_Actvation";
CM_ SG_ 362 RSPA_EntryFuncBtnDispSta "RSPA Entry Function Button Display State";
CM_ SG_ 362 RSPA_TrgtGearSta "RSPA_TargetGearStatus";
CM_ SG_ 362 RSPA_EpbReq "RSPA_EPBRequest";
CM_ SG_ 362 RSPA_ExtLampReq "RSPA_ExternalLampRequest";
CM_ SG_ 362 RSPA_CrankingReq "RSPA_CrankingRequest";
CM_ SG_ 362 RSPA_IdOutWarnReq "RSPA_IdOutWarningRequest";
CM_ SG_ 362 RSPA_IndBlnkReq "RSPA_IndicatorBlinkingRequest";
CM_ SG_ 362 RSPA_SysOff "RSPA System status flag";
CM_ SG_ 362 RSPA_DccCmd "RSPA_DccelerationCommand";
CM_ SG_ 362 RSPA_StopReq "RSPA_StopRequest";
CM_ SG_ 362 RSPA_SelDevInfo "Selected Remote Device Information";
CM_ SG_ 362 RSPA_SelFuncSta "RSPA Selected Function State";
CM_ SG_ 362 RSPA_TrgtVehSpdVal "RSPA_TargetVehicleSpeedValue";
CM_ SG_ 362 ADAS_PRK_AlvCnt3Val "ADAS_PRK_AliveCounter3Value";
CM_ SG_ 362 RSPA_AddtnlAccelActv "RSPA_AdditionalAccelarationActivation";
CM_ SG_ 362 RSPA_Opt "RSPA_Option";
CM_ SG_ 362 RSPA_TrgtTqVal "RSPA_TargetTorqueValue";
CM_ SG_ 362 RSPA_UppLtTypDis "RSPA_UpperLeftTypeDisplay";
CM_ SG_ 362 RSPA_LwrLtTypDis "RSPA_LowerLeftTypeDisplay";
CM_ SG_ 362 RSPA_UppRtTypDis "RSPA_UpperRightTypeDisplay";
CM_ SG_ 362 RSPA_LwrRtTypDis "RSPA_LowerRightTypeDisplay";
CM_ SG_ 362 RSPA_DCTTrgtTqVal "RSPA_DCTTargetTorqueValue";
CM_ SG_ 362 MRA_BtnDispSta "MRA Button Display State";
CM_ SG_ 362 RSPA_AvnDis "RSPA_AvnDisplay";
CM_ SG_ 362 RSPA_HdLmpReq "RSPA Head Lamp Request";
CM_ SG_ 362 MRA_CamDispSta "MRA Camera Display State";
CM_ SG_ 362 RSPA_BtnDispSta "RSPA Button Display State";
CM_ SG_ 362 RSPA_OSMirFoldReq "RSPA_OSMirrorFoldRequest";
CM_ SG_ 362 RSPA_AvnModDis "RSPA_AvnModeDisplay";
CM_ SG_ 362 RSPA_AvnSubViewDis "RSPA_AvnSubViewDisplay";
CM_ SG_ 362 MRA_AVNDispSta "MRA AVN Display State";
CM_ SG_ 362 RSPA_DgtKeyVer "RSPA Digital Key Version";
CM_ SG_ 362 RSPA_AvnHmiDis "RSPA_AvnHmiDisplay";
CM_ SG_ 362 MRA_AVNHMIDispSta "MRA AVN HMI Display State";
CM_ SG_ 362 RSPA_RWS_AnglReq "RSPA_RWS_AngleRequest";
CM_ BO_ 2281701472 "[PE] Periodic and On Event";
CM_ SG_ 2281701472 L_BDC_FD_ROA_Crc1Val "L_BDC_FD_ROA_CyclicRedundancyCheck1Value";
CM_ SG_ 2281701472 L_BDC_FD_ROA_AlvCnt1Val "L_BDC_FD_ROA_AliveCounter1Value";
CM_ SG_ 2281701472 ROA_SnsrRunReq "Sensor detection request";
CM_ SG_ 2281701472 ROA_DiaReq "Diagnosis/parameter request";
CM_ SG_ 2281701472 ROA_Region_Opt "ROA Euro NCAP Option signal";
CM_ SG_ 2281701472 ROA_EngSta "Engine Status";
CM_ BO_ 2683310288 "[EW] On Event and On Write";
CM_ SG_ 2683310288 ROA_FR_Debug_00 "Debug Monitoring Data";
CM_ SG_ 2683310288 ROA_FR_Debug_02 "Debug Monitoring Data";
CM_ SG_ 2683310288 ROA_FR_Debug_03 "Debug Monitoring Data";
CM_ SG_ 2683310288 ROA_FR_Debug_01 "Debug Monitoring Data";
CM_ BO_ 1494 "[TP] Transport Protocol";
CM_ BO_ 2281701521 "[PE] Periodic and On Event";
CM_ SG_ 2281701521 L_DHRR_FD_Crc20Val "L_DHRR_FD_CyclicRedundancyCheck20Value";
CM_ SG_ 2281701521 L_DHRR_FD_AlvCnt20Val "L_DHRR_FD_AliveCounter20Value";
CM_ SG_ 2281701521 DHRR_Status "Rear RH Door Processing Status";
CM_ SG_ 2281701521 DHRR_Rain_Sta "Rear RH Rain Detect Status";
CM_ SG_ 2281701521 DHRR_PhnDet_Sta "DHRR Phone Detected Signal";
CM_ SG_ 2281701521 DHRR_TglDet_Sta "Rear RH Door Toggle Sensor Input";
CM_ SG_ 2281701521 DHRR_UnlckDet_Sta "Rear RH Door Unlock Sensor Input";
CM_ SG_ 2281701521 DHRR_LckDet_Sta "Rear RH Door Lock Sensor Input";
CM_ SG_ 2281701521 DHRR_ResetOpsta "This signal indicates whether the reset operation has been completed or not";
CM_ SG_ 2281701521 DHRR_Diag_Sta "Rear RH Door NFC_Touch_Diag";
CM_ BO_ 2683310289 "[EW] On Event and On Write";
CM_ SG_ 2683310289 ROA_FR_Debug_04 "Debug Monitoring Data";
CM_ SG_ 2683310289 ROA_FR_Debug_06 "Debug Monitoring Data";
CM_ SG_ 2683310289 ROA_FR_Debug_07 "Debug Monitoring Data";
CM_ SG_ 2683310289 ROA_FR_Debug_05 "Debug Monitoring Data";
CM_ BO_ 2281701520 "[PE] Periodic and On Event";
CM_ SG_ 2281701520 L_DHR_FD_Crc20Val "L_DHR_FD_CyclicRedundancyCheck20Value";
CM_ SG_ 2281701520 L_DHR_FD_AlvCnt20Val "L_DHR_FD_AliveCounter20Value";
CM_ SG_ 2281701520 DHR_Status "RH Door Processing Status";
CM_ SG_ 2281701520 DHR_Rain_Sta "RH Rain Detect Status";
CM_ SG_ 2281701520 DHR_PhnDet_Sta "DHR Phone Detected Signal";
CM_ SG_ 2281701520 DHR_TglDet_Sta "RH Door Toggle Sensor Input";
CM_ SG_ 2281701520 DHR_UnlckDet_Sta "RH Door Unlock Sensor Input";
CM_ SG_ 2281701520 DHR_LckDet_Sta "RH Door Lock Sensor Input";
CM_ SG_ 2281701520 DHR_ResetOpSta "This signal indicates whether the reset operation has been completed or not";
CM_ SG_ 2281701520 DHR_Diag_Sta "RH Door NFC_Touch_Diag";
CM_ BO_ 2683310290 "[EW] On Event and On Write";
CM_ SG_ 2683310290 ROA_FR_Debug_08 "Debug Monitoring Data";
CM_ BO_ 2521143297 "[EW] On Event and On Write";
CM_ SG_ 2521143297 L_UWB_BLE_SLV_FD_Crc12Val "L_UWB_BLE_SLV_FD_CyclicRedundancyCheck12Value";
CM_ SG_ 2521143297 L_UWB_BLE_SLV_FD_AlvCnt12Val "L_UWB_BLE_SLV_FD_AliveCounter12Value";
CM_ SG_ 2521143297 SLV_SWID_3_IVD_2 "Slave SW Unit 3 IVD2";
CM_ BO_ 1502 "[TP] Transport Protocol";
CM_ BO_ 2683310273 "[EW] On Event and On Write";
CM_ SG_ 2683310273 ROA_FR_Dev_01 "Development Mode Data";
CM_ BO_ 2281701504 "[PE] Periodic and On Event";
CM_ SG_ 2281701504 L_DHL_FD_Crc20Val "L_DHL_FD_CyclicRedundancyCheck20Value";
CM_ SG_ 2281701504 L_DHL_FD_AlvCnt20Val "L_DHL_FD_AliveCounter20Value";
CM_ SG_ 2281701504 DHL_Status "LH Door Processing Status";
CM_ SG_ 2281701504 DHL_Rain_Sta "LH Rain Detect Status";
CM_ SG_ 2281701504 DHL_PhnDet_Sta "DHL Phone Detected Signal";
CM_ SG_ 2281701504 DHL_TglDet_Sta "LH Door Toggle Sensor Input";
CM_ SG_ 2281701504 DHL_UnlckDet_Sta "LH Door Unlock Sensor Input";
CM_ SG_ 2281701504 DHL_LckDet_Sta "LH Door Lock Sensor Input";
CM_ SG_ 2281701504 DHL_ResetOpsta "This signal indicates whether the reset operation has been completed or not";
CM_ SG_ 2281701504 DHL_Diag_Sta "LH Door NFC_Touch_Diag";
CM_ BO_ 2683310272 "[EW] On Event and On Write";
CM_ SG_ 2683310272 ROA_FR_Dev_00 "Development Mode Data";
CM_ BO_ 2281701505 "[PE] Periodic and On Event";
CM_ SG_ 2281701505 L_DHRL_FD_Crc20Val "L_DHRL_FD_CyclicRedundancyCheck20Value";
CM_ SG_ 2281701505 L_DHRL_FD_AlvCnt20Val "L_DHRL_FD_AliveCounter20Value";
CM_ SG_ 2281701505 DHRL_Status "Rear LH Door Processing Status";
CM_ SG_ 2281701505 DHRL_Rain_Sta "Rear LH Rain Detect Status";
CM_ SG_ 2281701505 DHRL_PhnDet_Sta "Rear DHL Phone Detected Signal";
CM_ SG_ 2281701505 DHRL_TglDet_Sta "Rear LH Door Toggle Sensor Input";
CM_ SG_ 2281701505 DHRL_UnlckDet_Sta "Rear LH Door Unlock Sensor Input";
CM_ SG_ 2281701505 DHRL_LckDet_Sta "Rear LH Door Lock Sensor Input";
CM_ SG_ 2281701505 DHRL_ResetOpSta "This signal indicates whether the reset operation has been completed or not";
CM_ SG_ 2281701505 DHRL_Diag_Sta "Rear LH Door NFC_Touch_Diag";
CM_ BO_ 2683310275 "[EW] On Event and On Write";
CM_ SG_ 2683310275 ROA_FR_Dev_03 "Development Mode Data";
CM_ BO_ 2683310274 "[EW] On Event and On Write";
CM_ SG_ 2683310274 ROA_FR_Dev_02 "Development Mode Data";
CM_ BO_ 2683310277 "[EW] On Event and On Write";
CM_ SG_ 2683310277 ROA_FR_Dev_05 "Development Mode Data";
CM_ BO_ 2525340417 "[EW] On Event and On Write";
CM_ SG_ 2525340417 L_UWB_FL_FD_Crc7Val "L_UWB_FL_FD_CyclicRedundancyCheck7Value";
CM_ SG_ 2525340417 L_UWB_FL_FD_AlvCnt7Val "L_UWB_FL_FD_AliveCounter7Value";
CM_ SG_ 2525340417 FL_SWID_4_IVD_2 "UWB FL SW Unit 4 IVD2";
CM_ BO_ 2683310276 "[EW] On Event and On Write";
CM_ SG_ 2683310276 ROA_FR_Dev_04 "Development Mode Data";
CM_ BO_ 2683310279 "[EW] On Event and On Write";
CM_ SG_ 2683310279 ROA_FR_Dev_07 "Development Mode Data";
CM_ BO_ 2683310278 "[EW] On Event and On Write";
CM_ SG_ 2683310278 ROA_FR_Dev_06 "Development Mode Data";
CM_ BO_ 2683310281 "[EW] On Event and On Write";
CM_ SG_ 2683310281 ROA_FR_Dev_09 "Development Mode Data";
CM_ BO_ 2683310280 "[EW] On Event and On Write";
CM_ SG_ 2683310280 ROA_FR_Dev_08 "Development Mode Data";
CM_ BO_ 2683310282 "[EW] On Event and On Write";
CM_ SG_ 2683310282 ROA_FR_Dev_10 "Development Mode Data";
CM_ BO_ 2521143809 "[EW] On Event and On Write";
CM_ SG_ 2521143809 L_UWB_BLE_SLV_FD_Crc14Val "L_UWB_BLE_SLV_FD_CyclicRedundancyCheck14Value";
CM_ SG_ 2521143809 L_UWB_BLE_SLV_FD_AlvCnt14Val "L_UWB_BLE_SLV_FD_AliveCounter14Value";
CM_ SG_ 2521143809 SLV_SWID_4_IVD_2 "Slave SW Unit 4 IVD2";
CM_ BO_ 2281701553 "[PE] Periodic and On Event";
CM_ SG_ 2281701553 L_UWB_BLE_SLV_FD_Crc21Val "L_UWB_BLE_SLV_FD_CyclicRedundancyCheck21Value";
CM_ SG_ 2281701553 SLV_SW_MCU_Ver_Major "Slave SW MCU Version Major";
CM_ SG_ 2281701553 SLV_SW_MCU_Ver_Minor "Slave SW MCU Version Minor";
CM_ SG_ 2281701553 SLV_SW_UWB_Ver_Major "Slave SW UWB Version Major";
CM_ SG_ 2281701553 SLV_SW_UWB_Ver_Minor "Slave SW UWB Version Minor";
CM_ SG_ 2281701553 SLV_SW_BLE_Ver_Major "Slave SW BLE Version Major";
CM_ SG_ 2281701553 SLV_SW_BLE_Ver_Minor "Slave SW BLE Version Minor";
CM_ SG_ 2281701553 SLV_DTC "Slave DTC Data";
CM_ SG_ 2281701553 L_UWB_BLE_SLV_FD_AlvCnt21Val "L_UWB_BLE_SLV_FD_AliveCounter21Value";
CM_ SG_ 2281701553 SLV_DTC_BLE "Slave DTC Data";
CM_ SG_ 2281701553 SLV_UWB_Status1 "UWB_SLAVE Processing Status 1";
CM_ SG_ 2281701553 SLV_UWB_Status2 "UWB_SLAVE Processing Status 2";
CM_ SG_ 2281701553 SLV_UWB_Status3 "UWB_SLAVE Processing Status 3";
CM_ SG_ 2281701553 SLV_UWB_Status4 "UWB_SLAVE Processing Status 4";
CM_ SG_ 2281701553 SLV_UWB_Status5 "UWB_SLAVE Processing Status 5";
CM_ SG_ 2281701553 SLV_UWB_Status6 "UWB_SLAVE Processing Status 6";
CM_ SG_ 2281701553 SLV_UWB_Status7 "UWB_SLAVE Processing Status 7";
CM_ SG_ 2281701553 SLV_UWB_Status8 "UWB_SLAVE Processing Status 8";
CM_ SG_ 2281701553 SLV_UWB_Status9 "UWB_SLAVE Processing Status 9";
CM_ SG_ 2281701553 SLV_UWB_Status10 "UWB_SLAVE Processing Status 10";
CM_ SG_ 2281701553 SLV_UWB_Status11 "UWB_SLAVE Processing Status 11";
CM_ SG_ 2281701553 SLV_UWB_Status12 "UWB_SLAVE Processing Status 12";
CM_ SG_ 2281701553 SLV_UWB_Status13 "UWB_SLAVE Processing Status 13";
CM_ SG_ 2281701553 SLV_UWB_Status14 "UWB_SLAVE Processing Status 14";
CM_ SG_ 2281701553 SLV_UWB_Status15 "UWB_SLAVE Processing Status 15";
CM_ SG_ 2281701553 SLV_UWB_Status16 "UWB_SLAVE Processing Status 16";
CM_ SG_ 2281701553 SLV_HW_Ver_Major "Slave HW Version Major";
CM_ SG_ 2281701553 SLV_HW_Ver_Minor "Slave HW Version Minor";
BA_DEF_ BO_  "CANFD_BRS" ENUM  "0","1";
BA_DEF_ BO_  "GenMsgEVName" STRING ;
BA_DEF_ BO_  "NmAsrMessage" ENUM  "No","Yes";
BA_DEF_ BO_  "DiagState" ENUM  "No","Yes";
BA_DEF_ BO_  "DiagResponse" ENUM  "No","Yes";
BA_DEF_ BO_  "DiagRequest" ENUM  "No","Yes";
BA_DEF_ BO_  "TpMessage" ENUM  "No","Yes";
BA_DEF_ BO_  "UsrMsgIDSforwardDeviation" INT 0 100;
BA_DEF_ BO_  "UsrMsgIDSbackwardDeviation" INT 50 1000;
BA_DEF_ BO_  "GenMsgCycleTime" INT 0 2000;
BA_DEF_ BO_  "GenMsgStartDelayTime" INT 0 2000;
BA_DEF_ BO_  "GenMsgSendType" ENUM  "Cyclic","NoMsgSendType";
BA_DEF_ BO_  "GenMsgCycleTimeFast" INT 0 500;
BA_DEF_ BO_  "GenMsgDelayTime" INT 0 20;
BA_DEF_ BO_  "GenMsgILSupport" ENUM  "No","Yes";
BA_DEF_ BO_  "GenMsgNrOfRepetition" INT 0 3;
BA_DEF_ BO_  "TpTxIndex" INT 0 65535;
BA_DEF_ BO_  "VFrameFormat" ENUM  "StandardCAN","ExtendedCAN","reserved","reserved","reserved","reserved","reserved","reserved","reserved","reserved","reserved","reserved","reserved","reserved","StandardCAN_FD","ExtendedCAN_FD";
BA_DEF_ SG_  "UserSigValidity" ENUM  "B+","ACC","IG","IG1","IG2","IG3","IG1 or IG2","IG1 or IG3","Undef";
BA_DEF_ SG_  "TimeoutValue" STRING ;
BA_DEF_ SG_  "UsrSigPurpose" ENUM  "Undef","FN","DIAG","DIAG(Req)","DIAG(Res)","DIAG(Func)","DEV","CCP","NM","TP";
BA_DEF_ SG_  "GenSigStartValue" INT 0 1215752192;
BA_DEF_ SG_  "NetworkRequest" ENUM  "Yes","No";
BA_DEF_ SG_  "NetworkRequestHoldingTime" INT 0 65535;
BA_DEF_ SG_  "Description" STRING ;
BA_DEF_ SG_  "Version" STRING ;
BA_DEF_ SG_  "GenSigEnvVarType" ENUM  "Int","Float","Undef";
BA_DEF_ SG_  "GenSigSendType" ENUM  "Cyclic","OnWrite","OnWriteWithRepetition","OnChange","OnChangeWithRepetition","IfActive","IfActiveWithRepetition","NoSigSendType","OnChangeAndIfActive","OnChangeAndIfActiveWithRepetition";
BA_DEF_ SG_  "GwSigLatencyTime" INT 0 65536;
BA_DEF_ SG_  "GwSigMissingSourceType" ENUM  "Undef","OldValue","DefaultValue","InitialValue";
BA_DEF_ SG_  "NWM-WakeupAllowed" ENUM  "<n.a.>";
BA_DEF_ SG_  "RoutingFactor" INT 1 1215752192;
BA_DEF_ SG_  "SystemSignalLongSymbol" STRING ;
BA_DEF_REL_ BU_SG_REL_  "GenSigTimeoutTime" INT 0 7000;
BA_DEF_DEF_  "CANFD_BRS" "1";
BA_DEF_DEF_  "GenMsgEVName" "@Signame";
BA_DEF_DEF_  "NmAsrMessage" "No";
BA_DEF_DEF_  "DiagState" "No";
BA_DEF_DEF_  "DiagResponse" "No";
BA_DEF_DEF_  "DiagRequest" "No";
BA_DEF_DEF_  "TpMessage" "No";
BA_DEF_DEF_  "UsrMsgIDSforwardDeviation" 10;
BA_DEF_DEF_  "UsrMsgIDSbackwardDeviation" 100;
BA_DEF_DEF_  "GenMsgCycleTime" 200;
BA_DEF_DEF_  "GenMsgStartDelayTime" 0;
BA_DEF_DEF_  "GenMsgSendType" "NoMsgSendType";
BA_DEF_DEF_  "GenMsgCycleTimeFast" 40;
BA_DEF_DEF_  "GenMsgDelayTime" 20;
BA_DEF_DEF_  "GenMsgILSupport" "Yes";
BA_DEF_DEF_  "GenMsgNrOfRepetition" 3;
BA_DEF_DEF_  "TpTxIndex" 0;
BA_DEF_DEF_  "VFrameFormat" "StandardCAN";
BA_DEF_DEF_  "UserSigValidity" "IG";
BA_DEF_DEF_  "TimeoutValue" "";
BA_DEF_DEF_  "UsrSigPurpose" "FN";
BA_DEF_DEF_  "GenSigStartValue" 0;
BA_DEF_DEF_  "NetworkRequest" "No";
BA_DEF_DEF_  "NetworkRequestHoldingTime" 0;
BA_DEF_DEF_  "Description" "";
BA_DEF_DEF_  "Version" "";
BA_DEF_DEF_  "GenSigEnvVarType" "Undef";
BA_DEF_DEF_  "GenSigSendType" "NoSigSendType";
BA_DEF_DEF_  "GwSigLatencyTime" 40;
BA_DEF_DEF_  "GwSigMissingSourceType" "Undef";
BA_DEF_DEF_  "NWM-WakeupAllowed" "<n.a.>";
BA_DEF_DEF_  "RoutingFactor" 1;
BA_DEF_DEF_REL_ "GenSigTimeoutTime" 500;
BA_DEF_DEF_  "SystemSignalLongSymbol" "";
BA_ "GenMsgStartDelayTime" BO_ 849 40;
BA_ "GenMsgSendType" BO_ 849 0;
BA_ "VFrameFormat" BO_ 849 14;
BA_ "GenMsgCycleTime" BO_ 1338 500;
BA_ "GenMsgSendType" BO_ 1338 0;
BA_ "VFrameFormat" BO_ 1338 14;
BA_ "GenMsgDelayTime" BO_ 2214592800 10;
BA_ "GenMsgCycleTime" BO_ 2214592800 0;
BA_ "VFrameFormat" BO_ 2214592800 15;
BA_ "GenMsgCycleTime" BO_ 1340 500;
BA_ "GenMsgSendType" BO_ 1340 0;
BA_ "VFrameFormat" BO_ 1340 14;
BA_ "GenMsgDelayTime" BO_ 2214592802 10;
BA_ "GenMsgCycleTime" BO_ 2214592802 0;
BA_ "VFrameFormat" BO_ 2214592802 15;
BA_ "GenMsgCycleTime" BO_ 1329 500;
BA_ "GenMsgSendType" BO_ 1329 0;
BA_ "VFrameFormat" BO_ 1329 14;
BA_ "GenMsgCycleTime" BO_ 1328 500;
BA_ "GenMsgSendType" BO_ 1328 0;
BA_ "VFrameFormat" BO_ 1328 14;
BA_ "GenMsgCycleTime" BO_ 1331 500;
BA_ "GenMsgSendType" BO_ 1331 0;
BA_ "VFrameFormat" BO_ 1331 14;
BA_ "TpTxIndex" BO_ 1813 183;
BA_ "TpMessage" BO_ 1813 1;
BA_ "GenMsgILSupport" BO_ 1813 0;
BA_ "DiagRequest" BO_ 1813 1;
BA_ "GenMsgNrOfRepetition" BO_ 1813 0;
BA_ "GenMsgCycleTimeFast" BO_ 1813 0;
BA_ "GenMsgCycleTime" BO_ 1813 0;
BA_ "VFrameFormat" BO_ 1813 14;
BA_ "GenMsgCycleTime" BO_ 1330 500;
BA_ "GenMsgSendType" BO_ 1330 0;
BA_ "VFrameFormat" BO_ 1330 14;
BA_ "GenMsgCycleTime" BO_ 1333 500;
BA_ "GenMsgSendType" BO_ 1333 0;
BA_ "VFrameFormat" BO_ 1333 14;
BA_ "GenMsgCycleTime" BO_ 1332 500;
BA_ "GenMsgSendType" BO_ 1332 0;
BA_ "VFrameFormat" BO_ 1332 14;
BA_ "GenMsgCycleTime" BO_ 1335 500;
BA_ "GenMsgSendType" BO_ 1335 0;
BA_ "VFrameFormat" BO_ 1335 14;
BA_ "GenMsgSendType" BO_ 2281701488 0;
BA_ "VFrameFormat" BO_ 2281701488 15;
BA_ "GenMsgCycleTime" BO_ 1334 500;
BA_ "GenMsgSendType" BO_ 1334 0;
BA_ "VFrameFormat" BO_ 1334 14;
BA_ "TpTxIndex" BO_ 1805 149;
BA_ "TpMessage" BO_ 1805 1;
BA_ "GenMsgILSupport" BO_ 1805 0;
BA_ "DiagResponse" BO_ 1805 1;
BA_ "GenMsgNrOfRepetition" BO_ 1805 0;
BA_ "GenMsgCycleTimeFast" BO_ 1805 0;
BA_ "GenMsgCycleTime" BO_ 1805 0;
BA_ "VFrameFormat" BO_ 1805 14;
BA_ "TpTxIndex" BO_ 1802 182;
BA_ "TpMessage" BO_ 1802 1;
BA_ "GenMsgILSupport" BO_ 1802 0;
BA_ "DiagResponse" BO_ 1802 1;
BA_ "GenMsgNrOfRepetition" BO_ 1802 0;
BA_ "GenMsgCycleTimeFast" BO_ 1802 0;
BA_ "GenMsgCycleTime" BO_ 1802 0;
BA_ "VFrameFormat" BO_ 1802 14;
BA_ "GenMsgDelayTime" BO_ 2521142785 10;
BA_ "GenMsgCycleTime" BO_ 2521142785 0;
BA_ "VFrameFormat" BO_ 2521142785 15;
BA_ "GenMsgDelayTime" BO_ 2533739009 10;
BA_ "GenMsgCycleTime" BO_ 2533739009 0;
BA_ "VFrameFormat" BO_ 2533739009 15;
BA_ "TpTxIndex" BO_ 1797 149;
BA_ "TpMessage" BO_ 1797 1;
BA_ "GenMsgILSupport" BO_ 1797 0;
BA_ "DiagRequest" BO_ 1797 1;
BA_ "GenMsgNrOfRepetition" BO_ 1797 0;
BA_ "GenMsgCycleTimeFast" BO_ 1797 0;
BA_ "GenMsgCycleTime" BO_ 1797 0;
BA_ "VFrameFormat" BO_ 1797 14;
BA_ "GenMsgDelayTime" BO_ 2529540609 10;
BA_ "GenMsgCycleTime" BO_ 2529540609 0;
BA_ "VFrameFormat" BO_ 2529540609 15;
BA_ "TpTxIndex" BO_ 1794 182;
BA_ "TpMessage" BO_ 1794 1;
BA_ "GenMsgILSupport" BO_ 1794 0;
BA_ "DiagRequest" BO_ 1794 1;
BA_ "GenMsgNrOfRepetition" BO_ 1794 0;
BA_ "GenMsgCycleTimeFast" BO_ 1794 0;
BA_ "GenMsgCycleTime" BO_ 1794 0;
BA_ "VFrameFormat" BO_ 1794 14;
BA_ "GenMsgDelayTime" BO_ 362 0;
BA_ "GenMsgNrOfRepetition" BO_ 362 0;
BA_ "GenMsgCycleTimeFast" BO_ 362 0;
BA_ "GenMsgCycleTime" BO_ 362 20;
BA_ "GenMsgSendType" BO_ 362 0;
BA_ "VFrameFormat" BO_ 362 14;
BA_ "GenMsgSendType" BO_ 2281701472 0;
BA_ "VFrameFormat" BO_ 2281701472 15;
BA_ "GenMsgDelayTime" BO_ 2683310288 10;
BA_ "GenMsgCycleTime" BO_ 2683310288 0;
BA_ "VFrameFormat" BO_ 2683310288 15;
BA_ "TpTxIndex" BO_ 1494 320;
BA_ "TpMessage" BO_ 1494 1;
BA_ "GenMsgILSupport" BO_ 1494 0;
BA_ "DiagRequest" BO_ 1494 1;
BA_ "GenMsgNrOfRepetition" BO_ 1494 0;
BA_ "GenMsgCycleTimeFast" BO_ 1494 0;
BA_ "GenMsgCycleTime" BO_ 1494 0;
BA_ "VFrameFormat" BO_ 1494 14;
BA_ "GenMsgSendType" BO_ 2281701521 0;
BA_ "VFrameFormat" BO_ 2281701521 15;
BA_ "GenMsgDelayTime" BO_ 2683310289 10;
BA_ "GenMsgCycleTime" BO_ 2683310289 0;
BA_ "VFrameFormat" BO_ 2683310289 15;
BA_ "GenMsgSendType" BO_ 2281701520 0;
BA_ "VFrameFormat" BO_ 2281701520 15;
BA_ "GenMsgDelayTime" BO_ 2683310290 10;
BA_ "GenMsgCycleTime" BO_ 2683310290 0;
BA_ "VFrameFormat" BO_ 2683310290 15;
BA_ "GenMsgDelayTime" BO_ 2521143297 10;
BA_ "GenMsgCycleTime" BO_ 2521143297 0;
BA_ "VFrameFormat" BO_ 2521143297 15;
BA_ "TpTxIndex" BO_ 1502 320;
BA_ "TpMessage" BO_ 1502 1;
BA_ "GenMsgILSupport" BO_ 1502 0;
BA_ "DiagResponse" BO_ 1502 1;
BA_ "GenMsgNrOfRepetition" BO_ 1502 0;
BA_ "GenMsgCycleTimeFast" BO_ 1502 0;
BA_ "GenMsgCycleTime" BO_ 1502 0;
BA_ "VFrameFormat" BO_ 1502 14;
BA_ "GenMsgDelayTime" BO_ 2683310273 10;
BA_ "GenMsgCycleTime" BO_ 2683310273 0;
BA_ "VFrameFormat" BO_ 2683310273 15;
BA_ "GenMsgSendType" BO_ 2281701504 0;
BA_ "VFrameFormat" BO_ 2281701504 15;
BA_ "GenMsgDelayTime" BO_ 2683310272 10;
BA_ "GenMsgCycleTime" BO_ 2683310272 0;
BA_ "VFrameFormat" BO_ 2683310272 15;
BA_ "GenMsgSendType" BO_ 2281701505 0;
BA_ "VFrameFormat" BO_ 2281701505 15;
BA_ "GenMsgDelayTime" BO_ 2683310275 10;
BA_ "GenMsgCycleTime" BO_ 2683310275 0;
BA_ "VFrameFormat" BO_ 2683310275 15;
BA_ "GenMsgDelayTime" BO_ 2683310274 10;
BA_ "GenMsgCycleTime" BO_ 2683310274 0;
BA_ "VFrameFormat" BO_ 2683310274 15;
BA_ "GenMsgDelayTime" BO_ 2683310277 10;
BA_ "GenMsgCycleTime" BO_ 2683310277 0;
BA_ "VFrameFormat" BO_ 2683310277 15;
BA_ "GenMsgDelayTime" BO_ 2525340417 10;
BA_ "GenMsgCycleTime" BO_ 2525340417 0;
BA_ "VFrameFormat" BO_ 2525340417 15;
BA_ "GenMsgDelayTime" BO_ 2683310276 10;
BA_ "GenMsgCycleTime" BO_ 2683310276 0;
BA_ "VFrameFormat" BO_ 2683310276 15;
BA_ "GenMsgDelayTime" BO_ 2683310279 10;
BA_ "GenMsgCycleTime" BO_ 2683310279 0;
BA_ "VFrameFormat" BO_ 2683310279 15;
BA_ "GenMsgDelayTime" BO_ 2683310278 10;
BA_ "GenMsgCycleTime" BO_ 2683310278 0;
BA_ "VFrameFormat" BO_ 2683310278 15;
BA_ "GenMsgDelayTime" BO_ 2683310281 10;
BA_ "GenMsgCycleTime" BO_ 2683310281 0;
BA_ "VFrameFormat" BO_ 2683310281 15;
BA_ "GenMsgDelayTime" BO_ 2683310280 10;
BA_ "GenMsgCycleTime" BO_ 2683310280 0;
BA_ "VFrameFormat" BO_ 2683310280 15;
BA_ "GenMsgDelayTime" BO_ 2683310282 10;
BA_ "GenMsgCycleTime" BO_ 2683310282 0;
BA_ "VFrameFormat" BO_ 2683310282 15;
BA_ "GenMsgDelayTime" BO_ 2521143809 10;
BA_ "GenMsgCycleTime" BO_ 2521143809 0;
BA_ "VFrameFormat" BO_ 2521143809 15;
BA_ "GenMsgSendType" BO_ 2281701553 0;
BA_ "VFrameFormat" BO_ 2281701553 15;
BA_ "Version" SG_ 849 IAU_FD_Crc4Val "22.11.04";
BA_ "UserSigValidity" SG_ 849 IAU_FD_Crc4Val 0;
BA_ "GenSigStartValue" SG_ 849 IAU_FD_Crc4Val 65535;
BA_ "GenSigSendType" SG_ 849 IAU_FD_Crc4Val 4;
BA_ "Description" SG_ 849 IAU_FD_Crc4Val "The data area for CRC calculation is based on the data length (DLC) of the message DB.

The CRC shall be calculated over the entire data block (excluding the CRC bytes) including the user data, alive counter and Data ID



- CRC Polynomial (0x1021) , Ini";
BA_ "Version" SG_ 849 IAU_DISPWrng_Copy_0 "22.06.04";
BA_ "NetworkRequestHoldingTime" SG_ 849 IAU_DISPWrng_Copy_0 5000;
BA_ "NetworkRequest" SG_ 849 IAU_DISPWrng_Copy_0 0;
BA_ "UserSigValidity" SG_ 849 IAU_DISPWrng_Copy_0 0;
BA_ "GenSigSendType" SG_ 849 IAU_DISPWrng_Copy_0 4;
BA_ "Description" SG_ 849 IAU_DISPWrng_Copy_0 "This siganl warning from IAU

- 0x9 (WPCNFC_PreStartAuth_Success) : CLU display when workaround or LPCD Start Auth succeeded (before SSB pressed).";
BA_ "Version" SG_ 849 IAU_DigitalKey2Opt_Copy_0 "20.08.00";
BA_ "NetworkRequestHoldingTime" SG_ 849 IAU_DigitalKey2Opt_Copy_0 5000;
BA_ "NetworkRequest" SG_ 849 IAU_DigitalKey2Opt_Copy_0 0;
BA_ "UserSigValidity" SG_ 849 IAU_DigitalKey2Opt_Copy_0 0;
BA_ "GenSigSendType" SG_ 849 IAU_DigitalKey2Opt_Copy_0 4;
BA_ "Description" SG_ 849 IAU_DigitalKey2Opt_Copy_0 "This signal describe Digital Key capability";
BA_ "Version" SG_ 849 IAUwFRULearnState_Copy_0 "20.04.05";
BA_ "NetworkRequestHoldingTime" SG_ 849 IAUwFRULearnState_Copy_0 5000;
BA_ "NetworkRequest" SG_ 849 IAUwFRULearnState_Copy_0 0;
BA_ "UserSigValidity" SG_ 849 IAUwFRULearnState_Copy_0 0;
BA_ "GenSigSendType" SG_ 849 IAUwFRULearnState_Copy_0 4;
BA_ "Description" SG_ 849 IAUwFRULearnState_Copy_0 "This signal indicates learning process stste between IAU and FRU";
BA_ "Version" SG_ 849 IAUwFPMLearnState_Copy_0 "20.04.05";
BA_ "NetworkRequestHoldingTime" SG_ 849 IAUwFPMLearnState_Copy_0 5000;
BA_ "NetworkRequest" SG_ 849 IAUwFPMLearnState_Copy_0 0;
BA_ "UserSigValidity" SG_ 849 IAUwFPMLearnState_Copy_0 0;
BA_ "GenSigSendType" SG_ 849 IAUwFPMLearnState_Copy_0 4;
BA_ "Description" SG_ 849 IAUwFPMLearnState_Copy_0 "This signal indicates learning process stste between IAU and FPM";
BA_ "Version" SG_ 849 IAU_ValetDigitalkey_Copy_0 "20.08.05";
BA_ "NetworkRequestHoldingTime" SG_ 849 IAU_ValetDigitalkey_Copy_0 5000;
BA_ "NetworkRequest" SG_ 849 IAU_ValetDigitalkey_Copy_0 0;
BA_ "UserSigValidity" SG_ 849 IAU_ValetDigitalkey_Copy_0 0;
BA_ "GenSigSendType" SG_ 849 IAU_ValetDigitalkey_Copy_0 4;
BA_ "Version" SG_ 849 IAU_DigitalKeyNumberOpt_Copy_0 "23.04.04";
BA_ "NetworkRequestHoldingTime" SG_ 849 IAU_DigitalKeyNumberOpt_Copy_0 5000;
BA_ "NetworkRequest" SG_ 849 IAU_DigitalKeyNumberOpt_Copy_0 0;
BA_ "UserSigValidity" SG_ 849 IAU_DigitalKeyNumberOpt_Copy_0 0;
BA_ "GenSigSendType" SG_ 849 IAU_DigitalKeyNumberOpt_Copy_0 4;
BA_ "Description" SG_ 849 IAU_DigitalKeyNumberOpt_Copy_0 "This signal is for the digital key number type. 

(Ex. Max 16 of digital keys in total can be saved and shared)";
BA_ "Version" SG_ 849 IAU_eSEReprogramSta_Copy_0 "22.07.04";
BA_ "NetworkRequestHoldingTime" SG_ 849 IAU_eSEReprogramSta_Copy_0 5000;
BA_ "NetworkRequest" SG_ 849 IAU_eSEReprogramSta_Copy_0 0;
BA_ "UserSigValidity" SG_ 849 IAU_eSEReprogramSta_Copy_0 0;
BA_ "TimeoutValue" SG_ 849 IAU_eSEReprogramSta_Copy_0 "0";
BA_ "GenSigSendType" SG_ 849 IAU_eSEReprogramSta_Copy_0 4;
BA_ "Description" SG_ 849 IAU_eSEReprogramSta_Copy_0 "eSE Reprograming Status";
BA_ "Version" SG_ 849 IAU_DKOwnerSwapOption_Copy_0 "24.01.04";
BA_ "UserSigValidity" SG_ 849 IAU_DKOwnerSwapOption_Copy_0 0;
BA_ "GenSigSendType" SG_ 849 IAU_DKOwnerSwapOption_Copy_0 4;
BA_ "Description" SG_ 849 IAU_DKOwnerSwapOption_Copy_0 "Digital key owner swap option signal";
BA_ "Version" SG_ 849 IAU_DgtKeyGrpPrflRval2_Copy_0 "23.02.13";
BA_ "NetworkRequestHoldingTime" SG_ 849 IAU_DgtKeyGrpPrflRval2_Copy_0 5000;
BA_ "NetworkRequest" SG_ 849 IAU_DgtKeyGrpPrflRval2_Copy_0 0;
BA_ "UserSigValidity" SG_ 849 IAU_DgtKeyGrpPrflRval2_Copy_0 0;
BA_ "GenSigSendType" SG_ 849 IAU_DgtKeyGrpPrflRval2_Copy_0 4;
BA_ "Description" SG_ 849 IAU_DgtKeyGrpPrflRval2_Copy_0 "Digital Key Group number(max : 16 )";
BA_ "Version" SG_ 849 IAU_StartIdentifiedProfile_Copy_ "20.05.02";
BA_ "NetworkRequestHoldingTime" SG_ 849 IAU_StartIdentifiedProfile_Copy_ 5000;
BA_ "NetworkRequest" SG_ 849 IAU_StartIdentifiedProfile_Copy_ 0;
BA_ "UserSigValidity" SG_ 849 IAU_StartIdentifiedProfile_Copy_ 0;
BA_ "TimeoutValue" SG_ 849 IAU_StartIdentifiedProfile_Copy_ "0x0";
BA_ "GenSigSendType" SG_ 849 IAU_StartIdentifiedProfile_Copy_ 4;
BA_ "SystemSignalLongSymbol" SG_ 849 IAU_StartIdentifiedProfile_Copy_ "IAU_StartIdentifiedProfile_Copy_0";
BA_ "Version" SG_ 849 IAU_DigitalKeyProfileRval2_Copy_ "22.05.04";
BA_ "NetworkRequestHoldingTime" SG_ 849 IAU_DigitalKeyProfileRval2_Copy_ 5000;
BA_ "NetworkRequest" SG_ 849 IAU_DigitalKeyProfileRval2_Copy_ 0;
BA_ "UserSigValidity" SG_ 849 IAU_DigitalKeyProfileRval2_Copy_ 0;
BA_ "GenSigSendType" SG_ 849 IAU_DigitalKeyProfileRval2_Copy_ 4;
BA_ "Description" SG_ 849 IAU_DigitalKeyProfileRval2_Copy_ "digital key number : max. 16";
BA_ "SystemSignalLongSymbol" SG_ 849 IAU_DigitalKeyProfileRval2_Copy_ "IAU_DigitalKeyProfileRval2_Copy_0";
BA_ "Version" SG_ 849 IAU_NFCCard1SN_Copy_0 "21.07.05";
BA_ "NetworkRequestHoldingTime" SG_ 849 IAU_NFCCard1SN_Copy_0 5000;
BA_ "NetworkRequest" SG_ 849 IAU_NFCCard1SN_Copy_0 0;
BA_ "UserSigValidity" SG_ 849 IAU_NFCCard1SN_Copy_0 0;
BA_ "GenSigSendType" SG_ 849 IAU_NFCCard1SN_Copy_0 4;
BA_ "Version" SG_ 849 IAU_FD_AlvCnt4Val "22.11.04";
BA_ "UserSigValidity" SG_ 849 IAU_FD_AlvCnt4Val 0;
BA_ "GenSigSendType" SG_ 849 IAU_FD_AlvCnt4Val 4;
BA_ "Description" SG_ 849 IAU_FD_AlvCnt4Val "For the first transmission request for a data element the counter shall be initialized with 0 and shall be incremented by 1 for every subsequent send request. 

When the counter reaches the maximum value(0xFF), then it shall restart with 0 for the next s";
BA_ "Version" SG_ 849 IAU_StartIdentifiedProfile_Ext "23.04.04";
BA_ "NetworkRequestHoldingTime" SG_ 849 IAU_StartIdentifiedProfile_Ext 5000;
BA_ "NetworkRequest" SG_ 849 IAU_StartIdentifiedProfile_Ext 0;
BA_ "UserSigValidity" SG_ 849 IAU_StartIdentifiedProfile_Ext 0;
BA_ "GenSigSendType" SG_ 849 IAU_StartIdentifiedProfile_Ext 4;
BA_ "Version" SG_ 849 RSPA_UWBRspaExtRngSta_Copy_0 "20.03.05";
BA_ "NetworkRequestHoldingTime" SG_ 849 RSPA_UWBRspaExtRngSta_Copy_0 5000;
BA_ "NetworkRequest" SG_ 849 RSPA_UWBRspaExtRngSta_Copy_0 0;
BA_ "UserSigValidity" SG_ 849 RSPA_UWBRspaExtRngSta_Copy_0 0;
BA_ "GenSigSendType" SG_ 849 RSPA_UWBRspaExtRngSta_Copy_0 4;
BA_ "Version" SG_ 849 RSPA_CanFltSta_Copy_0 "20.02.00";
BA_ "UserSigValidity" SG_ 849 RSPA_CanFltSta_Copy_0 0;
BA_ "GenSigSendType" SG_ 849 RSPA_CanFltSta_Copy_0 4;
BA_ "Description" SG_ 849 RSPA_CanFltSta_Copy_0 "Error status of RSPA control signals.";
BA_ "Version" SG_ 849 RSPA_BLESigErrSta_Copy_0 "20.02.00";
BA_ "NetworkRequestHoldingTime" SG_ 849 RSPA_BLESigErrSta_Copy_0 5000;
BA_ "NetworkRequest" SG_ 849 RSPA_BLESigErrSta_Copy_0 0;
BA_ "UserSigValidity" SG_ 849 RSPA_BLESigErrSta_Copy_0 0;
BA_ "GenSigSendType" SG_ 849 RSPA_BLESigErrSta_Copy_0 4;
BA_ "Description" SG_ 849 RSPA_BLESigErrSta_Copy_0 "Error status of Digital Key BLE_BtnReq signal.



If BLE frame data from Digital Key defferent with CAN signal data, 

RSPA_BLESigErrSta signal send 0x1 Signal Invalid.";
BA_ "Version" SG_ 849 RSPA_ConStat_Copy_0 "20.02.00";
BA_ "NetworkRequestHoldingTime" SG_ 849 RSPA_ConStat_Copy_0 5000;
BA_ "NetworkRequest" SG_ 849 RSPA_ConStat_Copy_0 0;
BA_ "UserSigValidity" SG_ 849 RSPA_ConStat_Copy_0 0;
BA_ "GenSigSendType" SG_ 849 RSPA_ConStat_Copy_0 4;
BA_ "Description" SG_ 849 RSPA_ConStat_Copy_0 "Connection Status among RSPA, IAU, BLE and SmartPhone";
BA_ "Version" SG_ 849 IAU_ProfileIDRVal_Copy_0 "23.02.02";
BA_ "NetworkRequestHoldingTime" SG_ 849 IAU_ProfileIDRVal_Copy_0 5000;
BA_ "NetworkRequest" SG_ 849 IAU_ProfileIDRVal_Copy_0 0;
BA_ "UserSigValidity" SG_ 849 IAU_ProfileIDRVal_Copy_0 0;
BA_ "GenSigSendType" SG_ 849 IAU_ProfileIDRVal_Copy_0 4;
BA_ "Version" SG_ 849 IAU_DigitalKeyProcessingSta_Copy "23.02.13";
BA_ "NetworkRequestHoldingTime" SG_ 849 IAU_DigitalKeyProcessingSta_Copy 5000;
BA_ "NetworkRequest" SG_ 849 IAU_DigitalKeyProcessingSta_Copy 0;
BA_ "UserSigValidity" SG_ 849 IAU_DigitalKeyProcessingSta_Copy 3;
BA_ "GenSigSendType" SG_ 849 IAU_DigitalKeyProcessingSta_Copy 4;
BA_ "SystemSignalLongSymbol" SG_ 849 IAU_DigitalKeyProcessingSta_Copy "IAU_DigitalKeyProcessingSta_Copy_0";
BA_ "Version" SG_ 849 IAU_DigitalKeyExit_Copy_0 "23.07.03";
BA_ "NetworkRequestHoldingTime" SG_ 849 IAU_DigitalKeyExit_Copy_0 5000;
BA_ "NetworkRequest" SG_ 849 IAU_DigitalKeyExit_Copy_0 0;
BA_ "UserSigValidity" SG_ 849 IAU_DigitalKeyExit_Copy_0 3;
BA_ "GenSigSendType" SG_ 849 IAU_DigitalKeyExit_Copy_0 4;
BA_ "Description" SG_ 849 IAU_DigitalKeyExit_Copy_0 "Digital Key USM setting Exit Condition";
BA_ "Version" SG_ 849 IAU_DigitalKeyEnblRVal_Copy_0 "20.05.02";
BA_ "NetworkRequestHoldingTime" SG_ 849 IAU_DigitalKeyEnblRVal_Copy_0 5000;
BA_ "NetworkRequest" SG_ 849 IAU_DigitalKeyEnblRVal_Copy_0 0;
BA_ "UserSigValidity" SG_ 849 IAU_DigitalKeyEnblRVal_Copy_0 0;
BA_ "GenSigSendType" SG_ 849 IAU_DigitalKeyEnblRVal_Copy_0 4;
BA_ "Version" SG_ 849 IAU_OwnerPhnRegRVal_Copy_0 "20.05.02";
BA_ "NetworkRequestHoldingTime" SG_ 849 IAU_OwnerPhnRegRVal_Copy_0 5000;
BA_ "NetworkRequest" SG_ 849 IAU_OwnerPhnRegRVal_Copy_0 0;
BA_ "UserSigValidity" SG_ 849 IAU_OwnerPhnRegRVal_Copy_0 0;
BA_ "GenSigSendType" SG_ 849 IAU_OwnerPhnRegRVal_Copy_0 4;
BA_ "Version" SG_ 849 IAU_NFCCard1RegRVal_Copy_0 "17.12.08";
BA_ "NetworkRequestHoldingTime" SG_ 849 IAU_NFCCard1RegRVal_Copy_0 5000;
BA_ "NetworkRequest" SG_ 849 IAU_NFCCard1RegRVal_Copy_0 0;
BA_ "UserSigValidity" SG_ 849 IAU_NFCCard1RegRVal_Copy_0 0;
BA_ "GenSigSendType" SG_ 849 IAU_NFCCard1RegRVal_Copy_0 4;
BA_ "Version" SG_ 849 IAU_NFCCard2RegRVal_Copy_0 "17.12.08";
BA_ "NetworkRequestHoldingTime" SG_ 849 IAU_NFCCard2RegRVal_Copy_0 5000;
BA_ "NetworkRequest" SG_ 849 IAU_NFCCard2RegRVal_Copy_0 0;
BA_ "UserSigValidity" SG_ 849 IAU_NFCCard2RegRVal_Copy_0 0;
BA_ "GenSigSendType" SG_ 849 IAU_NFCCard2RegRVal_Copy_0 4;
BA_ "Version" SG_ 1338 UWB_TRNK_FD_Crc30Val "24.05.05";
BA_ "UserSigValidity" SG_ 1338 UWB_TRNK_FD_Crc30Val 3;
BA_ "GenSigStartValue" SG_ 1338 UWB_TRNK_FD_Crc30Val 65535;
BA_ "GenSigSendType" SG_ 1338 UWB_TRNK_FD_Crc30Val 4;
BA_ "Description" SG_ 1338 UWB_TRNK_FD_Crc30Val "The data area for CRC calculation is based on the data length (DLC) of the message DB.

The CRC shall be calculated over the entire data block (excluding the CRC bytes) including the user data, alive counter and Data ID



- CRC Polynomial (0x1021) , Ini";
BA_ "Version" SG_ 1338 UWB_TRNK_FD_AlvCnt30Val "24.05.05";
BA_ "UserSigValidity" SG_ 1338 UWB_TRNK_FD_AlvCnt30Val 3;
BA_ "GenSigSendType" SG_ 1338 UWB_TRNK_FD_AlvCnt30Val 4;
BA_ "Description" SG_ 1338 UWB_TRNK_FD_AlvCnt30Val "For the first transmission request for a data element the counter shall be initialized with 0 and shall be incremented by 1 for every subsequent send request. 

When the counter reaches the maximum value(0xFF), then it shall restart with 0 for the next s";
BA_ "Version" SG_ 1338 UWB_TRNK_ResetOpsta "24.05.05";
BA_ "UserSigValidity" SG_ 1338 UWB_TRNK_ResetOpsta 0;
BA_ "GenSigSendType" SG_ 1338 UWB_TRNK_ResetOpsta 4;
BA_ "Description" SG_ 1338 UWB_TRNK_ResetOpsta "This signal indicates whether the reset operation has been completed or not";
BA_ "Version" SG_ 2214592800 L_ROA_FD_Crc2Val "23.01.02";
BA_ "UserSigValidity" SG_ 2214592800 L_ROA_FD_Crc2Val 3;
BA_ "GenSigStartValue" SG_ 2214592800 L_ROA_FD_Crc2Val 65535;
BA_ "GenSigSendType" SG_ 2214592800 L_ROA_FD_Crc2Val 2;
BA_ "Description" SG_ 2214592800 L_ROA_FD_Crc2Val "The data area for CRC calculation is based on the data length (DLC) of the message DB.

The CRC shall be calculated over the entire data block (excluding the CRC bytes) including the user data, alive counter and Data ID



- CRC Polynomial (0x1021) , Ini";
BA_ "Version" SG_ 2214592800 L_ROA_FD_AlvCnt2Val "23.01.02";
BA_ "UserSigValidity" SG_ 2214592800 L_ROA_FD_AlvCnt2Val 3;
BA_ "GenSigSendType" SG_ 2214592800 L_ROA_FD_AlvCnt2Val 2;
BA_ "Description" SG_ 2214592800 L_ROA_FD_AlvCnt2Val "For the first transmission request for a data element the counter shall be initialized with 0 and shall be incremented by 1 for every subsequent send request. 

When the counter reaches the maximum value(0xFF), then it shall restart with 0 for the next s";
BA_ "Version" SG_ 2214592800 ROABDC_DataByte0 "23.01.02";
BA_ "UserSigValidity" SG_ 2214592800 ROABDC_DataByte0 0;
BA_ "GenSigSendType" SG_ 2214592800 ROABDC_DataByte0 2;
BA_ "Version" SG_ 2214592800 ROABDC_DataByte1 "23.01.02";
BA_ "UserSigValidity" SG_ 2214592800 ROABDC_DataByte1 0;
BA_ "GenSigSendType" SG_ 2214592800 ROABDC_DataByte1 2;
BA_ "Version" SG_ 2214592800 ROABDC_DataByte2 "23.01.02";
BA_ "UserSigValidity" SG_ 2214592800 ROABDC_DataByte2 0;
BA_ "GenSigSendType" SG_ 2214592800 ROABDC_DataByte2 2;
BA_ "Version" SG_ 2214592800 ROABDC_DataByte3 "23.01.02";
BA_ "UserSigValidity" SG_ 2214592800 ROABDC_DataByte3 0;
BA_ "GenSigSendType" SG_ 2214592800 ROABDC_DataByte3 2;
BA_ "Version" SG_ 2214592800 ROABDC_DataByte4 "23.01.02";
BA_ "UserSigValidity" SG_ 2214592800 ROABDC_DataByte4 0;
BA_ "GenSigSendType" SG_ 2214592800 ROABDC_DataByte4 2;
BA_ "Version" SG_ 2214592800 ROABDC_DataByte5 "23.01.02";
BA_ "UserSigValidity" SG_ 2214592800 ROABDC_DataByte5 0;
BA_ "GenSigSendType" SG_ 2214592800 ROABDC_DataByte5 2;
BA_ "Version" SG_ 2214592800 ROABDC_DataByte6 "23.01.02";
BA_ "UserSigValidity" SG_ 2214592800 ROABDC_DataByte6 0;
BA_ "GenSigSendType" SG_ 2214592800 ROABDC_DataByte6 2;
BA_ "Version" SG_ 2214592800 ROABDC_DataByte7 "23.01.02";
BA_ "UserSigValidity" SG_ 2214592800 ROABDC_DataByte7 0;
BA_ "GenSigSendType" SG_ 2214592800 ROABDC_DataByte7 2;
BA_ "Version" SG_ 1340 SAL_ResetOpsta "24.05.05";
BA_ "UserSigValidity" SG_ 1340 SAL_ResetOpsta 0;
BA_ "GenSigSendType" SG_ 1340 SAL_ResetOpsta 4;
BA_ "Description" SG_ 1340 SAL_ResetOpsta "This signal indicates whether the reset operation has been completed or not";
BA_ "Version" SG_ 2214592802 L_ROA_FR_FD_Crc2Val "23.01.02";
BA_ "UserSigValidity" SG_ 2214592802 L_ROA_FR_FD_Crc2Val 3;
BA_ "GenSigStartValue" SG_ 2214592802 L_ROA_FR_FD_Crc2Val 65535;
BA_ "GenSigSendType" SG_ 2214592802 L_ROA_FR_FD_Crc2Val 2;
BA_ "Description" SG_ 2214592802 L_ROA_FR_FD_Crc2Val "The data area for CRC calculation is based on the data length (DLC) of the message DB.

The CRC shall be calculated over the entire data block (excluding the CRC bytes) including the user data, alive counter and Data ID



- CRC Polynomial (0x1021) , Ini";
BA_ "Version" SG_ 2214592802 L_ROA_FR_FD_AlvCnt2Val "23.01.02";
BA_ "UserSigValidity" SG_ 2214592802 L_ROA_FR_FD_AlvCnt2Val 3;
BA_ "GenSigSendType" SG_ 2214592802 L_ROA_FR_FD_AlvCnt2Val 2;
BA_ "Description" SG_ 2214592802 L_ROA_FR_FD_AlvCnt2Val "For the first transmission request for a data element the counter shall be initialized with 0 and shall be incremented by 1 for every subsequent send request. 

When the counter reaches the maximum value(0xFF), then it shall restart with 0 for the next s";
BA_ "Version" SG_ 2214592802 ROA_FRBDC_DataByte0 "23.01.02";
BA_ "UserSigValidity" SG_ 2214592802 ROA_FRBDC_DataByte0 0;
BA_ "GenSigSendType" SG_ 2214592802 ROA_FRBDC_DataByte0 2;
BA_ "Version" SG_ 2214592802 ROA_FRBDC_DataByte1 "23.01.02";
BA_ "UserSigValidity" SG_ 2214592802 ROA_FRBDC_DataByte1 0;
BA_ "GenSigSendType" SG_ 2214592802 ROA_FRBDC_DataByte1 2;
BA_ "Version" SG_ 2214592802 ROA_FRBDC_DataByte2 "23.01.02";
BA_ "UserSigValidity" SG_ 2214592802 ROA_FRBDC_DataByte2 0;
BA_ "GenSigSendType" SG_ 2214592802 ROA_FRBDC_DataByte2 2;
BA_ "Version" SG_ 2214592802 ROA_FRBDC_DataByte3 "23.01.02";
BA_ "UserSigValidity" SG_ 2214592802 ROA_FRBDC_DataByte3 0;
BA_ "GenSigSendType" SG_ 2214592802 ROA_FRBDC_DataByte3 2;
BA_ "Version" SG_ 2214592802 ROA_FRBDC_DataByte4 "23.01.02";
BA_ "UserSigValidity" SG_ 2214592802 ROA_FRBDC_DataByte4 0;
BA_ "GenSigSendType" SG_ 2214592802 ROA_FRBDC_DataByte4 2;
BA_ "Version" SG_ 2214592802 ROA_FRBDC_DataByte5 "23.01.02";
BA_ "UserSigValidity" SG_ 2214592802 ROA_FRBDC_DataByte5 0;
BA_ "GenSigSendType" SG_ 2214592802 ROA_FRBDC_DataByte5 2;
BA_ "Version" SG_ 2214592802 ROA_FRBDC_DataByte6 "23.01.02";
BA_ "UserSigValidity" SG_ 2214592802 ROA_FRBDC_DataByte6 0;
BA_ "GenSigSendType" SG_ 2214592802 ROA_FRBDC_DataByte6 2;
BA_ "Version" SG_ 2214592802 ROA_FRBDC_DataByte7 "23.01.02";
BA_ "UserSigValidity" SG_ 2214592802 ROA_FRBDC_DataByte7 0;
BA_ "GenSigSendType" SG_ 2214592802 ROA_FRBDC_DataByte7 2;
BA_ "Version" SG_ 1329 ROA_FR_ResetOpSta_Copy_0 "24.05.05";
BA_ "UserSigValidity" SG_ 1329 ROA_FR_ResetOpSta_Copy_0 0;
BA_ "GenSigSendType" SG_ 1329 ROA_FR_ResetOpSta_Copy_0 4;
BA_ "Description" SG_ 1329 ROA_FR_ResetOpSta_Copy_0 "This signal indicates whether the reset operation has been completed or not";
BA_ "Version" SG_ 1328 ROA_ResetOpSta_Copy_0 "24.05.05";
BA_ "UserSigValidity" SG_ 1328 ROA_ResetOpSta_Copy_0 0;
BA_ "GenSigSendType" SG_ 1328 ROA_ResetOpSta_Copy_0 4;
BA_ "Description" SG_ 1328 ROA_ResetOpSta_Copy_0 "This signal indicates whether the reset operation has been completed or not";
BA_ "Version" SG_ 1331 UWB_BLE_MST_FD_Crc30Val "24.05.05";
BA_ "UserSigValidity" SG_ 1331 UWB_BLE_MST_FD_Crc30Val 3;
BA_ "GenSigStartValue" SG_ 1331 UWB_BLE_MST_FD_Crc30Val 65535;
BA_ "GenSigSendType" SG_ 1331 UWB_BLE_MST_FD_Crc30Val 4;
BA_ "Description" SG_ 1331 UWB_BLE_MST_FD_Crc30Val "The data area for CRC calculation is based on the data length (DLC) of the message DB.

The CRC shall be calculated over the entire data block (excluding the CRC bytes) including the user data, alive counter and Data ID



- CRC Polynomial (0x1021) , Ini";
BA_ "Version" SG_ 1331 UWB_BLE_MST_FD_AlvCnt30Val "24.05.05";
BA_ "UserSigValidity" SG_ 1331 UWB_BLE_MST_FD_AlvCnt30Val 3;
BA_ "GenSigSendType" SG_ 1331 UWB_BLE_MST_FD_AlvCnt30Val 4;
BA_ "Description" SG_ 1331 UWB_BLE_MST_FD_AlvCnt30Val "For the first transmission request for a data element the counter shall be initialized with 0 and shall be incremented by 1 for every subsequent send request. 

When the counter reaches the maximum value(0xFF), then it shall restart with 0 for the next s";
BA_ "Version" SG_ 1331 UWB_BLE_MST_ResetOpsta "24.05.05";
BA_ "UserSigValidity" SG_ 1331 UWB_BLE_MST_ResetOpsta 0;
BA_ "GenSigSendType" SG_ 1331 UWB_BLE_MST_ResetOpsta 4;
BA_ "Description" SG_ 1331 UWB_BLE_MST_ResetOpsta "This signal indicates whether the reset operation has been completed or not";
BA_ "Version" SG_ 1331 UWB_BLE_MST_DeviceConnectionChec "24.07.01";
BA_ "UserSigValidity" SG_ 1331 UWB_BLE_MST_DeviceConnectionChec 0;
BA_ "GenSigSendType" SG_ 1331 UWB_BLE_MST_DeviceConnectionChec 4;
BA_ "Description" SG_ 1331 UWB_BLE_MST_DeviceConnectionChec "This signal indicates whether mobile phone has been connected or not";
BA_ "SystemSignalLongSymbol" SG_ 1331 UWB_BLE_MST_DeviceConnectionChec "UWB_BLE_MST_DeviceConnectionCheck";
BA_ "Version" SG_ 1813 GST_DHR_Byte0 "21.02.04";
BA_ "NetworkRequestHoldingTime" SG_ 1813 GST_DHR_Byte0 5000;
BA_ "NetworkRequest" SG_ 1813 GST_DHR_Byte0 0;
BA_ "UserSigValidity" SG_ 1813 GST_DHR_Byte0 0;
BA_ "UsrSigPurpose" SG_ 1813 GST_DHR_Byte0 3;
BA_ "Description" SG_ 1813 GST_DHR_Byte0 "TP Index : 183";
BA_ "Version" SG_ 1813 GST_DHR_Byte2 "21.02.04";
BA_ "NetworkRequestHoldingTime" SG_ 1813 GST_DHR_Byte2 5000;
BA_ "NetworkRequest" SG_ 1813 GST_DHR_Byte2 0;
BA_ "UserSigValidity" SG_ 1813 GST_DHR_Byte2 0;
BA_ "UsrSigPurpose" SG_ 1813 GST_DHR_Byte2 3;
BA_ "Description" SG_ 1813 GST_DHR_Byte2 "TP Index : 183";
BA_ "Version" SG_ 1813 GST_DHR_Byte3 "21.02.04";
BA_ "NetworkRequestHoldingTime" SG_ 1813 GST_DHR_Byte3 5000;
BA_ "NetworkRequest" SG_ 1813 GST_DHR_Byte3 0;
BA_ "UserSigValidity" SG_ 1813 GST_DHR_Byte3 0;
BA_ "UsrSigPurpose" SG_ 1813 GST_DHR_Byte3 3;
BA_ "Description" SG_ 1813 GST_DHR_Byte3 "TP Index : 183";
BA_ "Version" SG_ 1813 GST_DHR_Byte4 "21.02.04";
BA_ "NetworkRequestHoldingTime" SG_ 1813 GST_DHR_Byte4 5000;
BA_ "NetworkRequest" SG_ 1813 GST_DHR_Byte4 0;
BA_ "UserSigValidity" SG_ 1813 GST_DHR_Byte4 0;
BA_ "UsrSigPurpose" SG_ 1813 GST_DHR_Byte4 3;
BA_ "Description" SG_ 1813 GST_DHR_Byte4 "TP Index : 183";
BA_ "Version" SG_ 1813 GST_DHR_Byte5 "21.02.04";
BA_ "NetworkRequestHoldingTime" SG_ 1813 GST_DHR_Byte5 5000;
BA_ "NetworkRequest" SG_ 1813 GST_DHR_Byte5 0;
BA_ "UserSigValidity" SG_ 1813 GST_DHR_Byte5 0;
BA_ "UsrSigPurpose" SG_ 1813 GST_DHR_Byte5 3;
BA_ "Description" SG_ 1813 GST_DHR_Byte5 "TP Index : 183";
BA_ "Version" SG_ 1813 GST_DHR_Byte6 "21.02.04";
BA_ "NetworkRequestHoldingTime" SG_ 1813 GST_DHR_Byte6 5000;
BA_ "NetworkRequest" SG_ 1813 GST_DHR_Byte6 0;
BA_ "UserSigValidity" SG_ 1813 GST_DHR_Byte6 0;
BA_ "UsrSigPurpose" SG_ 1813 GST_DHR_Byte6 3;
BA_ "Description" SG_ 1813 GST_DHR_Byte6 "TP Index : 183";
BA_ "Version" SG_ 1813 GST_DHR_Byte7 "21.02.04";
BA_ "NetworkRequestHoldingTime" SG_ 1813 GST_DHR_Byte7 5000;
BA_ "NetworkRequest" SG_ 1813 GST_DHR_Byte7 0;
BA_ "UserSigValidity" SG_ 1813 GST_DHR_Byte7 0;
BA_ "UsrSigPurpose" SG_ 1813 GST_DHR_Byte7 3;
BA_ "Description" SG_ 1813 GST_DHR_Byte7 "TP Index : 183";
BA_ "Version" SG_ 1813 GST_DHR_Byte1 "21.02.04";
BA_ "NetworkRequestHoldingTime" SG_ 1813 GST_DHR_Byte1 5000;
BA_ "NetworkRequest" SG_ 1813 GST_DHR_Byte1 0;
BA_ "UserSigValidity" SG_ 1813 GST_DHR_Byte1 0;
BA_ "UsrSigPurpose" SG_ 1813 GST_DHR_Byte1 3;
BA_ "Description" SG_ 1813 GST_DHR_Byte1 "TP Index : 183";
BA_ "Version" SG_ 1330 TPMS_FD_Crc3Val "24.05.05";
BA_ "UserSigValidity" SG_ 1330 TPMS_FD_Crc3Val 3;
BA_ "GenSigStartValue" SG_ 1330 TPMS_FD_Crc3Val 65535;
BA_ "GenSigSendType" SG_ 1330 TPMS_FD_Crc3Val 4;
BA_ "Description" SG_ 1330 TPMS_FD_Crc3Val "The data area for CRC calculation is based on the data length (DLC) of the message DB.

The CRC shall be calculated over the entire data block (excluding the CRC bytes) including the user data, alive counter and Data ID



- CRC Polynomial (0x1021) , Ini";
BA_ "Version" SG_ 1330 TPMS_FD_AlvCnt3Val "24.05.05";
BA_ "UserSigValidity" SG_ 1330 TPMS_FD_AlvCnt3Val 3;
BA_ "GenSigSendType" SG_ 1330 TPMS_FD_AlvCnt3Val 4;
BA_ "Description" SG_ 1330 TPMS_FD_AlvCnt3Val "For the first transmission request for a data element the counter shall be initialized with 0 and shall be incremented by 1 for every subsequent send request. 

When the counter reaches the maximum value(0xFF), then it shall restart with 0 for the next s";
BA_ "Version" SG_ 1330 TPMS_ResetOpsta "24.05.05";
BA_ "UserSigValidity" SG_ 1330 TPMS_ResetOpsta 0;
BA_ "GenSigSendType" SG_ 1330 TPMS_ResetOpsta 4;
BA_ "Description" SG_ 1330 TPMS_ResetOpsta "This signal indicates whether the reset operation has been completed or not";
BA_ "Version" SG_ 1333 UWB_FL_FD_Crc30Val "24.05.07";
BA_ "UserSigValidity" SG_ 1333 UWB_FL_FD_Crc30Val 3;
BA_ "GenSigStartValue" SG_ 1333 UWB_FL_FD_Crc30Val 65535;
BA_ "GenSigSendType" SG_ 1333 UWB_FL_FD_Crc30Val 4;
BA_ "Description" SG_ 1333 UWB_FL_FD_Crc30Val "The data area for CRC calculation is based on the data length (DLC) of the message DB.

The CRC shall be calculated over the entire data block (excluding the CRC bytes) including the user data, alive counter and Data ID



- CRC Polynomial (0x1021) , Ini";
BA_ "Version" SG_ 1333 UWB_FL_FD_AlvCnt30Val "24.05.07";
BA_ "UserSigValidity" SG_ 1333 UWB_FL_FD_AlvCnt30Val 3;
BA_ "GenSigSendType" SG_ 1333 UWB_FL_FD_AlvCnt30Val 4;
BA_ "Description" SG_ 1333 UWB_FL_FD_AlvCnt30Val "For the first transmission request for a data element the counter shall be initialized with 0 and shall be incremented by 1 for every subsequent send request. 

When the counter reaches the maximum value(0xFF), then it shall restart with 0 for the next s";
BA_ "Version" SG_ 1333 UWB_FL_ResetOpsta "24.05.07";
BA_ "UserSigValidity" SG_ 1333 UWB_FL_ResetOpsta 0;
BA_ "GenSigSendType" SG_ 1333 UWB_FL_ResetOpsta 4;
BA_ "Description" SG_ 1333 UWB_FL_ResetOpsta "This signal indicates whether the reset operation has been completed or not";
BA_ "Version" SG_ 1332 UWB_BLE_SLV_FD_Crc30Val "24.05.05";
BA_ "UserSigValidity" SG_ 1332 UWB_BLE_SLV_FD_Crc30Val 3;
BA_ "GenSigStartValue" SG_ 1332 UWB_BLE_SLV_FD_Crc30Val 65535;
BA_ "GenSigSendType" SG_ 1332 UWB_BLE_SLV_FD_Crc30Val 4;
BA_ "Description" SG_ 1332 UWB_BLE_SLV_FD_Crc30Val "The data area for CRC calculation is based on the data length (DLC) of the message DB.

The CRC shall be calculated over the entire data block (excluding the CRC bytes) including the user data, alive counter and Data ID



- CRC Polynomial (0x1021) , Ini";
BA_ "Version" SG_ 1332 UWB_BLE_SLV_FD_AlvCnt30Val "24.05.05";
BA_ "UserSigValidity" SG_ 1332 UWB_BLE_SLV_FD_AlvCnt30Val 3;
BA_ "GenSigSendType" SG_ 1332 UWB_BLE_SLV_FD_AlvCnt30Val 4;
BA_ "Description" SG_ 1332 UWB_BLE_SLV_FD_AlvCnt30Val "For the first transmission request for a data element the counter shall be initialized with 0 and shall be incremented by 1 for every subsequent send request. 

When the counter reaches the maximum value(0xFF), then it shall restart with 0 for the next s";
BA_ "Version" SG_ 1332 UWB_BLE_SLV_ResetOpsta "24.05.05";
BA_ "UserSigValidity" SG_ 1332 UWB_BLE_SLV_ResetOpsta 0;
BA_ "GenSigSendType" SG_ 1332 UWB_BLE_SLV_ResetOpsta 4;
BA_ "Description" SG_ 1332 UWB_BLE_SLV_ResetOpsta "This signal indicates whether the reset operation has been completed or not";
BA_ "Version" SG_ 1332 UWB_BLE_SLV_DeviceConnectionChec "24.07.01";
BA_ "UserSigValidity" SG_ 1332 UWB_BLE_SLV_DeviceConnectionChec 0;
BA_ "GenSigSendType" SG_ 1332 UWB_BLE_SLV_DeviceConnectionChec 4;
BA_ "Description" SG_ 1332 UWB_BLE_SLV_DeviceConnectionChec "This signal indicates whether mobile phone has been connected or not";
BA_ "SystemSignalLongSymbol" SG_ 1332 UWB_BLE_SLV_DeviceConnectionChec "UWB_BLE_SLV_DeviceConnectionCheck";
BA_ "Version" SG_ 1335 UWB_FRNK_FD_Crc30Val "24.05.05";
BA_ "UserSigValidity" SG_ 1335 UWB_FRNK_FD_Crc30Val 3;
BA_ "GenSigStartValue" SG_ 1335 UWB_FRNK_FD_Crc30Val 65535;
BA_ "GenSigSendType" SG_ 1335 UWB_FRNK_FD_Crc30Val 4;
BA_ "Description" SG_ 1335 UWB_FRNK_FD_Crc30Val "The data area for CRC calculation is based on the data length (DLC) of the message DB.

The CRC shall be calculated over the entire data block (excluding the CRC bytes) including the user data, alive counter and Data ID



- CRC Polynomial (0x1021) , Ini";
BA_ "Version" SG_ 1335 UWB_FRNK_FD_AlvCnt30Val "24.05.05";
BA_ "UserSigValidity" SG_ 1335 UWB_FRNK_FD_AlvCnt30Val 3;
BA_ "GenSigSendType" SG_ 1335 UWB_FRNK_FD_AlvCnt30Val 4;
BA_ "Description" SG_ 1335 UWB_FRNK_FD_AlvCnt30Val "For the first transmission request for a data element the counter shall be initialized with 0 and shall be incremented by 1 for every subsequent send request. 

When the counter reaches the maximum value(0xFF), then it shall restart with 0 for the next s";
BA_ "Version" SG_ 1335 UWB_FRNK_ResetOpsta "24.05.05";
BA_ "UserSigValidity" SG_ 1335 UWB_FRNK_ResetOpsta 0;
BA_ "GenSigSendType" SG_ 1335 UWB_FRNK_ResetOpsta 4;
BA_ "Description" SG_ 1335 UWB_FRNK_ResetOpsta "This signal indicates whether the reset operation has been completed or not";
BA_ "Version" SG_ 2281701488 L_WPC_FD_Crc20Val "23.01.02";
BA_ "UserSigValidity" SG_ 2281701488 L_WPC_FD_Crc20Val 3;
BA_ "GenSigStartValue" SG_ 2281701488 L_WPC_FD_Crc20Val 65535;
BA_ "GenSigSendType" SG_ 2281701488 L_WPC_FD_Crc20Val 4;
BA_ "Description" SG_ 2281701488 L_WPC_FD_Crc20Val "The data area for CRC calculation is based on the data length (DLC) of the message DB.

The CRC shall be calculated over the entire data block (excluding the CRC bytes) including the user data, alive counter and Data ID



- CRC Polynomial (0x1021) , Ini";
BA_ "Version" SG_ 2281701488 L_WPC_FD_AlvCnt20Val "23.01.02";
BA_ "UserSigValidity" SG_ 2281701488 L_WPC_FD_AlvCnt20Val 3;
BA_ "GenSigSendType" SG_ 2281701488 L_WPC_FD_AlvCnt20Val 4;
BA_ "Description" SG_ 2281701488 L_WPC_FD_AlvCnt20Val "For the first transmission request for a data element the counter shall be initialized with 0 and shall be incremented by 1 for every subsequent send request. 

When the counter reaches the maximum value(0xFF), then it shall restart with 0 for the next s";
BA_ "Version" SG_ 2281701488 WPC_Status "23.01.02";
BA_ "UserSigValidity" SG_ 2281701488 WPC_Status 0;
BA_ "GenSigSendType" SG_ 2281701488 WPC_Status 4;
BA_ "Version" SG_ 2281701488 WPC2_Status "24.06.00";
BA_ "UserSigValidity" SG_ 2281701488 WPC2_Status 0;
BA_ "GenSigSendType" SG_ 2281701488 WPC2_Status 4;
BA_ "Description" SG_ 2281701488 WPC2_Status "WPC2 Processing Status";
BA_ "Version" SG_ 2281701488 WPC_NFC_Opt "23.01.02";
BA_ "UserSigValidity" SG_ 2281701488 WPC_NFC_Opt 0;
BA_ "GenSigSendType" SG_ 2281701488 WPC_NFC_Opt 4;
BA_ "Version" SG_ 1334 UWB_FR_FD_Crc30Val "24.05.05";
BA_ "UserSigValidity" SG_ 1334 UWB_FR_FD_Crc30Val 3;
BA_ "GenSigStartValue" SG_ 1334 UWB_FR_FD_Crc30Val 65535;
BA_ "GenSigSendType" SG_ 1334 UWB_FR_FD_Crc30Val 4;
BA_ "Description" SG_ 1334 UWB_FR_FD_Crc30Val "The data area for CRC calculation is based on the data length (DLC) of the message DB.

The CRC shall be calculated over the entire data block (excluding the CRC bytes) including the user data, alive counter and Data ID



- CRC Polynomial (0x1021) , Ini";
BA_ "Version" SG_ 1334 UWB_FR_FD_AlvCnt30Val "24.05.05";
BA_ "UserSigValidity" SG_ 1334 UWB_FR_FD_AlvCnt30Val 3;
BA_ "GenSigSendType" SG_ 1334 UWB_FR_FD_AlvCnt30Val 4;
BA_ "Description" SG_ 1334 UWB_FR_FD_AlvCnt30Val "For the first transmission request for a data element the counter shall be initialized with 0 and shall be incremented by 1 for every subsequent send request. 

When the counter reaches the maximum value(0xFF), then it shall restart with 0 for the next s";
BA_ "Version" SG_ 1334 UWB_FR_ResetOpsta "24.05.05";
BA_ "UserSigValidity" SG_ 1334 UWB_FR_ResetOpsta 0;
BA_ "GenSigSendType" SG_ 1334 UWB_FR_ResetOpsta 4;
BA_ "Description" SG_ 1334 UWB_FR_ResetOpsta "This signal indicates whether the reset operation has been completed or not";
BA_ "Version" SG_ 1805 MLM_GST_Byte0 "22.12.00";
BA_ "NetworkRequestHoldingTime" SG_ 1805 MLM_GST_Byte0 5000;
BA_ "NetworkRequest" SG_ 1805 MLM_GST_Byte0 0;
BA_ "UserSigValidity" SG_ 1805 MLM_GST_Byte0 0;
BA_ "UsrSigPurpose" SG_ 1805 MLM_GST_Byte0 4;
BA_ "Description" SG_ 1805 MLM_GST_Byte0 "TP Index : 149";
BA_ "Version" SG_ 1805 MLM_GST_Byte2 "22.12.00";
BA_ "NetworkRequestHoldingTime" SG_ 1805 MLM_GST_Byte2 5000;
BA_ "NetworkRequest" SG_ 1805 MLM_GST_Byte2 0;
BA_ "UserSigValidity" SG_ 1805 MLM_GST_Byte2 0;
BA_ "UsrSigPurpose" SG_ 1805 MLM_GST_Byte2 4;
BA_ "Description" SG_ 1805 MLM_GST_Byte2 "TP Index : 149";
BA_ "Version" SG_ 1805 MLM_GST_Byte3 "22.12.00";
BA_ "NetworkRequestHoldingTime" SG_ 1805 MLM_GST_Byte3 5000;
BA_ "NetworkRequest" SG_ 1805 MLM_GST_Byte3 0;
BA_ "UserSigValidity" SG_ 1805 MLM_GST_Byte3 0;
BA_ "UsrSigPurpose" SG_ 1805 MLM_GST_Byte3 4;
BA_ "Description" SG_ 1805 MLM_GST_Byte3 "TP Index : 149";
BA_ "Version" SG_ 1805 MLM_GST_Byte4 "22.12.00";
BA_ "NetworkRequestHoldingTime" SG_ 1805 MLM_GST_Byte4 5000;
BA_ "NetworkRequest" SG_ 1805 MLM_GST_Byte4 0;
BA_ "UserSigValidity" SG_ 1805 MLM_GST_Byte4 0;
BA_ "UsrSigPurpose" SG_ 1805 MLM_GST_Byte4 4;
BA_ "Description" SG_ 1805 MLM_GST_Byte4 "TP Index : 149";
BA_ "Version" SG_ 1805 MLM_GST_Byte5 "22.12.00";
BA_ "NetworkRequestHoldingTime" SG_ 1805 MLM_GST_Byte5 5000;
BA_ "NetworkRequest" SG_ 1805 MLM_GST_Byte5 0;
BA_ "UserSigValidity" SG_ 1805 MLM_GST_Byte5 0;
BA_ "UsrSigPurpose" SG_ 1805 MLM_GST_Byte5 4;
BA_ "Description" SG_ 1805 MLM_GST_Byte5 "TP Index : 149";
BA_ "Version" SG_ 1805 MLM_GST_Byte6 "22.12.00";
BA_ "NetworkRequestHoldingTime" SG_ 1805 MLM_GST_Byte6 5000;
BA_ "NetworkRequest" SG_ 1805 MLM_GST_Byte6 0;
BA_ "UserSigValidity" SG_ 1805 MLM_GST_Byte6 0;
BA_ "UsrSigPurpose" SG_ 1805 MLM_GST_Byte6 4;
BA_ "Description" SG_ 1805 MLM_GST_Byte6 "TP Index : 149";
BA_ "Version" SG_ 1805 MLM_GST_Byte7 "22.12.00";
BA_ "NetworkRequestHoldingTime" SG_ 1805 MLM_GST_Byte7 5000;
BA_ "NetworkRequest" SG_ 1805 MLM_GST_Byte7 0;
BA_ "UserSigValidity" SG_ 1805 MLM_GST_Byte7 0;
BA_ "UsrSigPurpose" SG_ 1805 MLM_GST_Byte7 4;
BA_ "Description" SG_ 1805 MLM_GST_Byte7 "TP Index : 149";
BA_ "Version" SG_ 1805 MLM_GST_Byte1 "22.12.00";
BA_ "NetworkRequestHoldingTime" SG_ 1805 MLM_GST_Byte1 5000;
BA_ "NetworkRequest" SG_ 1805 MLM_GST_Byte1 0;
BA_ "UserSigValidity" SG_ 1805 MLM_GST_Byte1 0;
BA_ "UsrSigPurpose" SG_ 1805 MLM_GST_Byte1 4;
BA_ "Description" SG_ 1805 MLM_GST_Byte1 "TP Index : 149";
BA_ "Version" SG_ 1802 DHL_GST_Byte0 "22.07.01";
BA_ "NetworkRequestHoldingTime" SG_ 1802 DHL_GST_Byte0 5000;
BA_ "NetworkRequest" SG_ 1802 DHL_GST_Byte0 0;
BA_ "UserSigValidity" SG_ 1802 DHL_GST_Byte0 0;
BA_ "UsrSigPurpose" SG_ 1802 DHL_GST_Byte0 4;
BA_ "Description" SG_ 1802 DHL_GST_Byte0 "TP Index : 182";
BA_ "Version" SG_ 1802 DHL_GST_Byte2 "22.07.01";
BA_ "NetworkRequestHoldingTime" SG_ 1802 DHL_GST_Byte2 5000;
BA_ "NetworkRequest" SG_ 1802 DHL_GST_Byte2 0;
BA_ "UserSigValidity" SG_ 1802 DHL_GST_Byte2 0;
BA_ "UsrSigPurpose" SG_ 1802 DHL_GST_Byte2 4;
BA_ "Description" SG_ 1802 DHL_GST_Byte2 "TP Index : 182";
BA_ "Version" SG_ 1802 DHL_GST_Byte3 "22.07.01";
BA_ "NetworkRequestHoldingTime" SG_ 1802 DHL_GST_Byte3 5000;
BA_ "NetworkRequest" SG_ 1802 DHL_GST_Byte3 0;
BA_ "UserSigValidity" SG_ 1802 DHL_GST_Byte3 0;
BA_ "UsrSigPurpose" SG_ 1802 DHL_GST_Byte3 4;
BA_ "Description" SG_ 1802 DHL_GST_Byte3 "TP Index : 182";
BA_ "Version" SG_ 1802 DHL_GST_Byte4 "22.07.01";
BA_ "NetworkRequestHoldingTime" SG_ 1802 DHL_GST_Byte4 5000;
BA_ "NetworkRequest" SG_ 1802 DHL_GST_Byte4 0;
BA_ "UserSigValidity" SG_ 1802 DHL_GST_Byte4 0;
BA_ "UsrSigPurpose" SG_ 1802 DHL_GST_Byte4 4;
BA_ "Description" SG_ 1802 DHL_GST_Byte4 "TP Index : 182";
BA_ "Version" SG_ 1802 DHL_GST_Byte5 "22.07.01";
BA_ "NetworkRequestHoldingTime" SG_ 1802 DHL_GST_Byte5 5000;
BA_ "NetworkRequest" SG_ 1802 DHL_GST_Byte5 0;
BA_ "UserSigValidity" SG_ 1802 DHL_GST_Byte5 0;
BA_ "UsrSigPurpose" SG_ 1802 DHL_GST_Byte5 4;
BA_ "Description" SG_ 1802 DHL_GST_Byte5 "TP Index : 182";
BA_ "Version" SG_ 1802 DHL_GST_Byte6 "22.07.01";
BA_ "NetworkRequestHoldingTime" SG_ 1802 DHL_GST_Byte6 5000;
BA_ "NetworkRequest" SG_ 1802 DHL_GST_Byte6 0;
BA_ "UserSigValidity" SG_ 1802 DHL_GST_Byte6 0;
BA_ "UsrSigPurpose" SG_ 1802 DHL_GST_Byte6 4;
BA_ "Description" SG_ 1802 DHL_GST_Byte6 "TP Index : 182";
BA_ "Version" SG_ 1802 DHL_GST_Byte7 "22.07.01";
BA_ "NetworkRequestHoldingTime" SG_ 1802 DHL_GST_Byte7 5000;
BA_ "NetworkRequest" SG_ 1802 DHL_GST_Byte7 0;
BA_ "UserSigValidity" SG_ 1802 DHL_GST_Byte7 0;
BA_ "UsrSigPurpose" SG_ 1802 DHL_GST_Byte7 4;
BA_ "Description" SG_ 1802 DHL_GST_Byte7 "TP Index : 182";
BA_ "Version" SG_ 1802 DHL_GST_Byte1 "22.07.01";
BA_ "NetworkRequestHoldingTime" SG_ 1802 DHL_GST_Byte1 5000;
BA_ "NetworkRequest" SG_ 1802 DHL_GST_Byte1 0;
BA_ "UserSigValidity" SG_ 1802 DHL_GST_Byte1 0;
BA_ "UsrSigPurpose" SG_ 1802 DHL_GST_Byte1 4;
BA_ "Description" SG_ 1802 DHL_GST_Byte1 "TP Index : 182";
BA_ "Version" SG_ 2521142785 L_UWB_BLE_SLV_FD_Crc10Val "24.07.05";
BA_ "RoutingFactor" SG_ 2521142785 L_UWB_BLE_SLV_FD_Crc10Val 0;
BA_ "UserSigValidity" SG_ 2521142785 L_UWB_BLE_SLV_FD_Crc10Val 3;
BA_ "GenSigStartValue" SG_ 2521142785 L_UWB_BLE_SLV_FD_Crc10Val 65535;
BA_ "GenSigSendType" SG_ 2521142785 L_UWB_BLE_SLV_FD_Crc10Val 2;
BA_ "Description" SG_ 2521142785 L_UWB_BLE_SLV_FD_Crc10Val "The data area for CRC calculation is based on the data length (DLC) of the message DB.

The CRC shall be calculated over the entire data block (excluding the CRC bytes) including the user data, alive counter and Data ID



- CRC Polynomial (0x1021) , Ini";
BA_ "Version" SG_ 2521142785 L_UWB_BLE_SLV_FD_AlvCnt10Val "24.07.05";
BA_ "RoutingFactor" SG_ 2521142785 L_UWB_BLE_SLV_FD_AlvCnt10Val 0;
BA_ "UserSigValidity" SG_ 2521142785 L_UWB_BLE_SLV_FD_AlvCnt10Val 3;
BA_ "GenSigSendType" SG_ 2521142785 L_UWB_BLE_SLV_FD_AlvCnt10Val 2;
BA_ "Description" SG_ 2521142785 L_UWB_BLE_SLV_FD_AlvCnt10Val "For the first transmission request for a data element the counter shall be initialized with 0 and shall be incremented by 1 for every subsequent send request. 

When the counter reaches the maximum value(0xFF), then it shall restart with 0 for the next s";
BA_ "Version" SG_ 2521142785 SLV_SWID_2_IVD_2 "24.07.05";
BA_ "RoutingFactor" SG_ 2521142785 SLV_SWID_2_IVD_2 0;
BA_ "UserSigValidity" SG_ 2521142785 SLV_SWID_2_IVD_2 0;
BA_ "GenSigSendType" SG_ 2521142785 SLV_SWID_2_IVD_2 2;
BA_ "Version" SG_ 2533739009 L_UWB_FRNK_FD_Crc6Val "24.07.05";
BA_ "RoutingFactor" SG_ 2533739009 L_UWB_FRNK_FD_Crc6Val 0;
BA_ "UserSigValidity" SG_ 2533739009 L_UWB_FRNK_FD_Crc6Val 3;
BA_ "GenSigStartValue" SG_ 2533739009 L_UWB_FRNK_FD_Crc6Val 65535;
BA_ "GenSigSendType" SG_ 2533739009 L_UWB_FRNK_FD_Crc6Val 2;
BA_ "Description" SG_ 2533739009 L_UWB_FRNK_FD_Crc6Val "The data area for CRC calculation is based on the data length (DLC) of the message DB.

The CRC shall be calculated over the entire data block (excluding the CRC bytes) including the user data, alive counter and Data ID



- CRC Polynomial (0x1021) , Ini";
BA_ "Version" SG_ 2533739009 L_UWB_FRNK_FD_AlvCnt6Val "24.07.05";
BA_ "RoutingFactor" SG_ 2533739009 L_UWB_FRNK_FD_AlvCnt6Val 0;
BA_ "UserSigValidity" SG_ 2533739009 L_UWB_FRNK_FD_AlvCnt6Val 3;
BA_ "GenSigSendType" SG_ 2533739009 L_UWB_FRNK_FD_AlvCnt6Val 2;
BA_ "Description" SG_ 2533739009 L_UWB_FRNK_FD_AlvCnt6Val "For the first transmission request for a data element the counter shall be initialized with 0 and shall be incremented by 1 for every subsequent send request. 

When the counter reaches the maximum value(0xFF), then it shall restart with 0 for the next s";
BA_ "Version" SG_ 2533739009 FRNK_SWID_4_IVD_1 "24.07.05";
BA_ "RoutingFactor" SG_ 2533739009 FRNK_SWID_4_IVD_1 0;
BA_ "UserSigValidity" SG_ 2533739009 FRNK_SWID_4_IVD_1 0;
BA_ "GenSigSendType" SG_ 2533739009 FRNK_SWID_4_IVD_1 2;
BA_ "Version" SG_ 1797 GST_MLM_Byte0 "22.12.00";
BA_ "NetworkRequestHoldingTime" SG_ 1797 GST_MLM_Byte0 5000;
BA_ "NetworkRequest" SG_ 1797 GST_MLM_Byte0 0;
BA_ "UserSigValidity" SG_ 1797 GST_MLM_Byte0 0;
BA_ "UsrSigPurpose" SG_ 1797 GST_MLM_Byte0 3;
BA_ "Description" SG_ 1797 GST_MLM_Byte0 "TP Index : 149";
BA_ "Version" SG_ 1797 GST_MLM_Byte2 "22.12.00";
BA_ "NetworkRequestHoldingTime" SG_ 1797 GST_MLM_Byte2 5000;
BA_ "NetworkRequest" SG_ 1797 GST_MLM_Byte2 0;
BA_ "UserSigValidity" SG_ 1797 GST_MLM_Byte2 0;
BA_ "UsrSigPurpose" SG_ 1797 GST_MLM_Byte2 3;
BA_ "Description" SG_ 1797 GST_MLM_Byte2 "TP Index : 149";
BA_ "Version" SG_ 1797 GST_MLM_Byte3 "22.12.00";
BA_ "NetworkRequestHoldingTime" SG_ 1797 GST_MLM_Byte3 5000;
BA_ "NetworkRequest" SG_ 1797 GST_MLM_Byte3 0;
BA_ "UserSigValidity" SG_ 1797 GST_MLM_Byte3 0;
BA_ "UsrSigPurpose" SG_ 1797 GST_MLM_Byte3 3;
BA_ "Description" SG_ 1797 GST_MLM_Byte3 "TP Index : 149";
BA_ "Version" SG_ 1797 GST_MLM_Byte4 "22.12.00";
BA_ "NetworkRequestHoldingTime" SG_ 1797 GST_MLM_Byte4 5000;
BA_ "NetworkRequest" SG_ 1797 GST_MLM_Byte4 0;
BA_ "UserSigValidity" SG_ 1797 GST_MLM_Byte4 0;
BA_ "UsrSigPurpose" SG_ 1797 GST_MLM_Byte4 3;
BA_ "Description" SG_ 1797 GST_MLM_Byte4 "TP Index : 149";
BA_ "Version" SG_ 1797 GST_MLM_Byte5 "22.12.00";
BA_ "NetworkRequestHoldingTime" SG_ 1797 GST_MLM_Byte5 5000;
BA_ "NetworkRequest" SG_ 1797 GST_MLM_Byte5 0;
BA_ "UserSigValidity" SG_ 1797 GST_MLM_Byte5 0;
BA_ "UsrSigPurpose" SG_ 1797 GST_MLM_Byte5 3;
BA_ "Description" SG_ 1797 GST_MLM_Byte5 "TP Index : 149";
BA_ "Version" SG_ 1797 GST_MLM_Byte6 "22.12.00";
BA_ "NetworkRequestHoldingTime" SG_ 1797 GST_MLM_Byte6 5000;
BA_ "NetworkRequest" SG_ 1797 GST_MLM_Byte6 0;
BA_ "UserSigValidity" SG_ 1797 GST_MLM_Byte6 0;
BA_ "UsrSigPurpose" SG_ 1797 GST_MLM_Byte6 3;
BA_ "Description" SG_ 1797 GST_MLM_Byte6 "TP Index : 149";
BA_ "Version" SG_ 1797 GST_MLM_Byte7 "22.12.00";
BA_ "NetworkRequestHoldingTime" SG_ 1797 GST_MLM_Byte7 5000;
BA_ "NetworkRequest" SG_ 1797 GST_MLM_Byte7 0;
BA_ "UserSigValidity" SG_ 1797 GST_MLM_Byte7 0;
BA_ "UsrSigPurpose" SG_ 1797 GST_MLM_Byte7 3;
BA_ "Description" SG_ 1797 GST_MLM_Byte7 "TP Index : 149";
BA_ "Version" SG_ 1797 GST_MLM_Byte1 "22.12.00";
BA_ "NetworkRequestHoldingTime" SG_ 1797 GST_MLM_Byte1 5000;
BA_ "NetworkRequest" SG_ 1797 GST_MLM_Byte1 0;
BA_ "UserSigValidity" SG_ 1797 GST_MLM_Byte1 0;
BA_ "UsrSigPurpose" SG_ 1797 GST_MLM_Byte1 3;
BA_ "Description" SG_ 1797 GST_MLM_Byte1 "TP Index : 149";
BA_ "Version" SG_ 2529540609 L_UWB_RR_FD_Crc6Val "24.07.05";
BA_ "RoutingFactor" SG_ 2529540609 L_UWB_RR_FD_Crc6Val 0;
BA_ "UserSigValidity" SG_ 2529540609 L_UWB_RR_FD_Crc6Val 3;
BA_ "GenSigStartValue" SG_ 2529540609 L_UWB_RR_FD_Crc6Val 65535;
BA_ "GenSigSendType" SG_ 2529540609 L_UWB_RR_FD_Crc6Val 2;
BA_ "Description" SG_ 2529540609 L_UWB_RR_FD_Crc6Val "The data area for CRC calculation is based on the data length (DLC) of the message DB.

The CRC shall be calculated over the entire data block (excluding the CRC bytes) including the user data, alive counter and Data ID



- CRC Polynomial (0x1021) , Ini";
BA_ "Version" SG_ 2529540609 L_UWB_RR_FD_AlvCnt6Val "24.07.05";
BA_ "RoutingFactor" SG_ 2529540609 L_UWB_RR_FD_AlvCnt6Val 0;
BA_ "UserSigValidity" SG_ 2529540609 L_UWB_RR_FD_AlvCnt6Val 3;
BA_ "GenSigSendType" SG_ 2529540609 L_UWB_RR_FD_AlvCnt6Val 2;
BA_ "Description" SG_ 2529540609 L_UWB_RR_FD_AlvCnt6Val "For the first transmission request for a data element the counter shall be initialized with 0 and shall be incremented by 1 for every subsequent send request. 

When the counter reaches the maximum value(0xFF), then it shall restart with 0 for the next s";
BA_ "Version" SG_ 2529540609 RR_SWID_4_IVD_1 "24.07.05";
BA_ "RoutingFactor" SG_ 2529540609 RR_SWID_4_IVD_1 0;
BA_ "UserSigValidity" SG_ 2529540609 RR_SWID_4_IVD_1 0;
BA_ "GenSigSendType" SG_ 2529540609 RR_SWID_4_IVD_1 2;
BA_ "Version" SG_ 1794 GST_DHL_Byte0 "21.02.04";
BA_ "NetworkRequestHoldingTime" SG_ 1794 GST_DHL_Byte0 5000;
BA_ "NetworkRequest" SG_ 1794 GST_DHL_Byte0 0;
BA_ "UserSigValidity" SG_ 1794 GST_DHL_Byte0 0;
BA_ "UsrSigPurpose" SG_ 1794 GST_DHL_Byte0 3;
BA_ "Description" SG_ 1794 GST_DHL_Byte0 "TP Index : 182";
BA_ "Version" SG_ 1794 GST_DHL_Byte2 "21.02.04";
BA_ "NetworkRequestHoldingTime" SG_ 1794 GST_DHL_Byte2 5000;
BA_ "NetworkRequest" SG_ 1794 GST_DHL_Byte2 0;
BA_ "UserSigValidity" SG_ 1794 GST_DHL_Byte2 0;
BA_ "UsrSigPurpose" SG_ 1794 GST_DHL_Byte2 3;
BA_ "Description" SG_ 1794 GST_DHL_Byte2 "TP Index : 182";
BA_ "Version" SG_ 1794 GST_DHL_Byte3 "21.02.04";
BA_ "NetworkRequestHoldingTime" SG_ 1794 GST_DHL_Byte3 5000;
BA_ "NetworkRequest" SG_ 1794 GST_DHL_Byte3 0;
BA_ "UserSigValidity" SG_ 1794 GST_DHL_Byte3 0;
BA_ "UsrSigPurpose" SG_ 1794 GST_DHL_Byte3 3;
BA_ "Description" SG_ 1794 GST_DHL_Byte3 "TP Index : 182";
BA_ "Version" SG_ 1794 GST_DHL_Byte4 "21.02.04";
BA_ "NetworkRequestHoldingTime" SG_ 1794 GST_DHL_Byte4 5000;
BA_ "NetworkRequest" SG_ 1794 GST_DHL_Byte4 0;
BA_ "UserSigValidity" SG_ 1794 GST_DHL_Byte4 0;
BA_ "UsrSigPurpose" SG_ 1794 GST_DHL_Byte4 3;
BA_ "Description" SG_ 1794 GST_DHL_Byte4 "TP Index : 182";
BA_ "Version" SG_ 1794 GST_DHL_Byte5 "21.02.04";
BA_ "NetworkRequestHoldingTime" SG_ 1794 GST_DHL_Byte5 5000;
BA_ "NetworkRequest" SG_ 1794 GST_DHL_Byte5 0;
BA_ "UserSigValidity" SG_ 1794 GST_DHL_Byte5 0;
BA_ "UsrSigPurpose" SG_ 1794 GST_DHL_Byte5 3;
BA_ "Description" SG_ 1794 GST_DHL_Byte5 "TP Index : 182";
BA_ "Version" SG_ 1794 GST_DHL_Byte6 "21.02.04";
BA_ "NetworkRequestHoldingTime" SG_ 1794 GST_DHL_Byte6 5000;
BA_ "NetworkRequest" SG_ 1794 GST_DHL_Byte6 0;
BA_ "UserSigValidity" SG_ 1794 GST_DHL_Byte6 0;
BA_ "UsrSigPurpose" SG_ 1794 GST_DHL_Byte6 3;
BA_ "Description" SG_ 1794 GST_DHL_Byte6 "TP Index : 182";
BA_ "Version" SG_ 1794 GST_DHL_Byte7 "21.02.04";
BA_ "NetworkRequestHoldingTime" SG_ 1794 GST_DHL_Byte7 5000;
BA_ "NetworkRequest" SG_ 1794 GST_DHL_Byte7 0;
BA_ "UserSigValidity" SG_ 1794 GST_DHL_Byte7 0;
BA_ "UsrSigPurpose" SG_ 1794 GST_DHL_Byte7 3;
BA_ "Description" SG_ 1794 GST_DHL_Byte7 "TP Index : 182";
BA_ "Version" SG_ 1794 GST_DHL_Byte1 "21.02.04";
BA_ "NetworkRequestHoldingTime" SG_ 1794 GST_DHL_Byte1 5000;
BA_ "NetworkRequest" SG_ 1794 GST_DHL_Byte1 0;
BA_ "UserSigValidity" SG_ 1794 GST_DHL_Byte1 0;
BA_ "UsrSigPurpose" SG_ 1794 GST_DHL_Byte1 3;
BA_ "Description" SG_ 1794 GST_DHL_Byte1 "TP Index : 182";
BA_ "Version" SG_ 362 ADAS_PRK_Crc3Val "21.09.03";
BA_ "RoutingFactor" SG_ 362 ADAS_PRK_Crc3Val 5;
BA_ "UserSigValidity" SG_ 362 ADAS_PRK_Crc3Val 3;
BA_ "GenSigStartValue" SG_ 362 ADAS_PRK_Crc3Val 65535;
BA_ "Description" SG_ 362 ADAS_PRK_Crc3Val "The data area for CRC calculation is based on the data length (DLC) of the message DB.

The CRC shall be calculated over the entire data block (excluding the CRC bytes) including the user data, alive counter and Data ID



- CRC Polynomial (0x1021) , Ini";
BA_ "Version" SG_ 362 RSPA_Var "23.02.06";
BA_ "RoutingFactor" SG_ 362 RSPA_Var 5;
BA_ "UserSigValidity" SG_ 362 RSPA_Var 3;
BA_ "Description" SG_ 362 RSPA_Var "RSPA variation";
BA_ "Version" SG_ 362 MRA_FuncEquipSta "24.01.04";
BA_ "RoutingFactor" SG_ 362 MRA_FuncEquipSta 5;
BA_ "UserSigValidity" SG_ 362 MRA_FuncEquipSta 3;
BA_ "Description" SG_ 362 MRA_FuncEquipSta "MRA Option applied information";
BA_ "Version" SG_ 362 RSPA_Sta "19.03.11";
BA_ "RoutingFactor" SG_ 362 RSPA_Sta 5;
BA_ "UserSigValidity" SG_ 362 RSPA_Sta 3;
BA_ "GenSigStartValue" SG_ 362 RSPA_Sta 1;
BA_ "Description" SG_ 362 RSPA_Sta "╟Ў└ч RSPA└╟ ╗є┼┬";
BA_ "Version" SG_ 362 RSPA_Actv "17.11.00";
BA_ "RoutingFactor" SG_ 362 RSPA_Actv 5;
BA_ "UserSigValidity" SG_ 362 RSPA_Actv 3;
BA_ "Description" SG_ 362 RSPA_Actv "RSPA's activation information";
BA_ "Version" SG_ 362 RSPA_EntryFuncBtnDispSta "24.07.03";
BA_ "RoutingFactor" SG_ 362 RSPA_EntryFuncBtnDispSta 5;
BA_ "UserSigValidity" SG_ 362 RSPA_EntryFuncBtnDispSta 3;
BA_ "Description" SG_ 362 RSPA_EntryFuncBtnDispSta "Request display of Remote forward or backward Button.

'Remote forward or backward' means RSPA Entry Function.";
BA_ "Version" SG_ 362 RSPA_TrgtGearSta "17.11.00";
BA_ "RoutingFactor" SG_ 362 RSPA_TrgtGearSta 5;
BA_ "UserSigValidity" SG_ 362 RSPA_TrgtGearSta 3;
BA_ "Description" SG_ 362 RSPA_TrgtGearSta "╕ё╟е ║п╝╙┤▄ 

(╕ё╟е ║п╝╙┤▄ 100ms └п┴Ў╚─ Idle ░к ╝█├т, ╕ё╟е░к rising └╠╚─ 500ms ┤ы▒т)";
BA_ "Version" SG_ 362 RSPA_EpbReq "19.03.11";
BA_ "RoutingFactor" SG_ 362 RSPA_EpbReq 5;
BA_ "UserSigValidity" SG_ 362 RSPA_EpbReq 3;
BA_ "Description" SG_ 362 RSPA_EpbReq "EPB ├╝░с/╟╪┴ж ┐ф├╗ (AHB ┐ь╚╕)";
BA_ "Version" SG_ 362 RSPA_ExtLampReq "17.11.00";
BA_ "RoutingFactor" SG_ 362 RSPA_ExtLampReq 5;
BA_ "UserSigValidity" SG_ 362 RSPA_ExtLampReq 3;
BA_ "Description" SG_ 362 RSPA_ExtLampReq "└№┴╢╡ю, ╣ц╟т┴Ў╜├╡ю ╡┐└█ ┐ф├╗ (RSPA ┐ы)

Type1:║ё╗є╡ю 1╚╕ Normal Blinking

Type2:║ё╗є╡ю 2╚╕ Normal Blinking

Type3:║ё╗є╡ю 3╚╕ Normal Blinking

Type4:║ё╗є╡ю ┴Ў╝╙└√└╕╖╬ Normal Blinking";
BA_ "Version" SG_ 362 RSPA_CrankingReq "17.11.00";
BA_ "RoutingFactor" SG_ 362 RSPA_CrankingReq 5;
BA_ "UserSigValidity" SG_ 362 RSPA_CrankingReq 3;
BA_ "Description" SG_ 362 RSPA_CrankingReq "╜├╡┐╕Ё╡х ├╡└╠ ┐ф├╗ (RSPA ┐ы)";
BA_ "Version" SG_ 362 RSPA_IdOutWarnReq "17.11.00";
BA_ "RoutingFactor" SG_ 362 RSPA_IdOutWarnReq 5;
BA_ "UserSigValidity" SG_ 362 RSPA_IdOutWarnReq 3;
BA_ "Description" SG_ 362 RSPA_IdOutWarnReq "ID out ╞╨┼╧ ║п░ц ┐ф├╗ (RSPA ┐ы)";
BA_ "Version" SG_ 362 RSPA_IndBlnkReq "23.03.01";
BA_ "RoutingFactor" SG_ 362 RSPA_IndBlnkReq 5;
BA_ "UserSigValidity" SG_ 362 RSPA_IndBlnkReq 3;
BA_ "Description" SG_ 362 RSPA_IndBlnkReq "FOB blinking request during RSPA mode";
BA_ "Version" SG_ 362 RSPA_SysOff "18.12.07";
BA_ "RoutingFactor" SG_ 362 RSPA_SysOff 5;
BA_ "UserSigValidity" SG_ 362 RSPA_SysOff 3;
BA_ "Description" SG_ 362 RSPA_SysOff "System off status for Smartphone display before RSPA control";
BA_ "Version" SG_ 362 RSPA_DccCmd "17.11.00";
BA_ "RoutingFactor" SG_ 362 RSPA_DccCmd 5;
BA_ "UserSigValidity" SG_ 362 RSPA_DccCmd 3;
BA_ "Description" SG_ 362 RSPA_DccCmd "╕ё╟е ░и╝╙╡╡, ┬ў╖о ┴д┬ў ╜├┐б╕╕(when RSPA_VS=0) ░и╝╙╡╡ ┴ж╛ю╕ё└√";
BA_ "Version" SG_ 362 RSPA_StopReq "17.11.00";
BA_ "RoutingFactor" SG_ 362 RSPA_StopReq 5;
BA_ "UserSigValidity" SG_ 362 RSPA_StopReq 3;
BA_ "Description" SG_ 362 RSPA_StopReq "A control request flag for vehicle stop. RSPA expects vehicle to be controlled to a complete stop and hold its state.";
BA_ "Version" SG_ 362 RSPA_SelDevInfo "18.12.07";
BA_ "RoutingFactor" SG_ 362 RSPA_SelDevInfo 5;
BA_ "UserSigValidity" SG_ 362 RSPA_SelDevInfo 3;
BA_ "Description" SG_ 362 RSPA_SelDevInfo "Device information for Remote Control in operation of RSPA";
BA_ "Version" SG_ 362 RSPA_SelFuncSta "24.03.06";
BA_ "RoutingFactor" SG_ 362 RSPA_SelFuncSta 5;
BA_ "UserSigValidity" SG_ 362 RSPA_SelFuncSta 3;
BA_ "Description" SG_ 362 RSPA_SelFuncSta "Function information in operation of RSPA for SmartPhone control";
BA_ "Version" SG_ 362 RSPA_TrgtVehSpdVal "18.07.01";
BA_ "RoutingFactor" SG_ 362 RSPA_TrgtVehSpdVal 5;
BA_ "UserSigValidity" SG_ 362 RSPA_TrgtVehSpdVal 3;
BA_ "Description" SG_ 362 RSPA_TrgtVehSpdVal "┬ў╝╙ ┐ф├╗░к, ┬ў╝╙ ╟┴╖╬╞─└╧ └№╝█ (0 бж 10.23)";
BA_ "Version" SG_ 362 ADAS_PRK_AlvCnt3Val "21.09.03";
BA_ "RoutingFactor" SG_ 362 ADAS_PRK_AlvCnt3Val 5;
BA_ "UserSigValidity" SG_ 362 ADAS_PRK_AlvCnt3Val 3;
BA_ "Description" SG_ 362 ADAS_PRK_AlvCnt3Val "For the first transmission request for a data element the counter shall be initialized with 0 and shall be incremented by 1 for every subsequent send request. 

When the counter reaches the maximum value(0xFF), then it shall restart with 0 for the next s";
BA_ "Version" SG_ 362 RSPA_AddtnlAccelActv "17.11.00";
BA_ "RoutingFactor" SG_ 362 RSPA_AddtnlAccelActv 5;
BA_ "UserSigValidity" SG_ 362 RSPA_AddtnlAccelActv 3;
BA_ "Description" SG_ 362 RSPA_AddtnlAccelActv "RSPA additional acceleration control ON";
BA_ "Version" SG_ 362 RSPA_Opt "17.12.03";
BA_ "RoutingFactor" SG_ 362 RSPA_Opt 5;
BA_ "UserSigValidity" SG_ 362 RSPA_Opt 3;
BA_ "Description" SG_ 362 RSPA_Opt "RSPA Option applied information";
BA_ "Version" SG_ 362 RSPA_TrgtTqVal "19.06.00";
BA_ "RoutingFactor" SG_ 362 RSPA_TrgtTqVal 5;
BA_ "UserSigValidity" SG_ 362 RSPA_TrgtTqVal 3;
BA_ "Description" SG_ 362 RSPA_TrgtTqVal "RSPA request EMS/HCU/VCU/FCU torque value (Nm)

Init value : 00h

If MSB is 1, this signal is - value.

else, this signal is +value.

0~10bit is used for absolute value.";
BA_ "Version" SG_ 362 RSPA_UppLtTypDis "23.10.01";
BA_ "RoutingFactor" SG_ 362 RSPA_UppLtTypDis 5;
BA_ "UserSigValidity" SG_ 362 RSPA_UppLtTypDis 3;
BA_ "Description" SG_ 362 RSPA_UppLtTypDis "Parking type displayed on upper-left of AVN (RSPA II)";
BA_ "Version" SG_ 362 RSPA_LwrLtTypDis "23.10.01";
BA_ "RoutingFactor" SG_ 362 RSPA_LwrLtTypDis 5;
BA_ "UserSigValidity" SG_ 362 RSPA_LwrLtTypDis 3;
BA_ "Description" SG_ 362 RSPA_LwrLtTypDis "Parking type displayed on lower-left of AVN (RSPA II)";
BA_ "Version" SG_ 362 RSPA_UppRtTypDis "23.10.01";
BA_ "RoutingFactor" SG_ 362 RSPA_UppRtTypDis 5;
BA_ "UserSigValidity" SG_ 362 RSPA_UppRtTypDis 3;
BA_ "Description" SG_ 362 RSPA_UppRtTypDis "Parking type displayed on upper-right of AVN (RSPA II)";
BA_ "Version" SG_ 362 RSPA_LwrRtTypDis "23.10.01";
BA_ "RoutingFactor" SG_ 362 RSPA_LwrRtTypDis 5;
BA_ "UserSigValidity" SG_ 362 RSPA_LwrRtTypDis 3;
BA_ "Description" SG_ 362 RSPA_LwrRtTypDis "Parking type displayed on lower-right of AVN (RSPA II)";
BA_ "Version" SG_ 362 RSPA_DCTTrgtTqVal "19.06.00";
BA_ "RoutingFactor" SG_ 362 RSPA_DCTTrgtTqVal 5;
BA_ "UserSigValidity" SG_ 362 RSPA_DCTTrgtTqVal 3;
BA_ "Description" SG_ 362 RSPA_DCTTrgtTqVal "RSPA request DCT torque value (Nm)

Init value : 00h

If MSB is 1, this signal is - value.

else, this signal is +value.

0~10bit is used for absolute value.";
BA_ "Version" SG_ 362 MRA_BtnDispSta "24.02.00";
BA_ "RoutingFactor" SG_ 362 MRA_BtnDispSta 5;
BA_ "UserSigValidity" SG_ 362 MRA_BtnDispSta 3;
BA_ "Description" SG_ 362 MRA_BtnDispSta "Request display of MRA Button";
BA_ "Version" SG_ 362 RSPA_AvnDis "17.11.00";
BA_ "RoutingFactor" SG_ 362 RSPA_AvnDis 5;
BA_ "UserSigValidity" SG_ 362 RSPA_AvnDis 3;
BA_ "Description" SG_ 362 RSPA_AvnDis "AVN ╚н╕щ ├т╖┬ ┐ф├╗ (RSPA ┐ы)

'-CGW routing ╟╩┐ф (CCAN to MMCAN)";
BA_ "Version" SG_ 362 RSPA_HdLmpReq "20.10.00";
BA_ "RoutingFactor" SG_ 362 RSPA_HdLmpReq 5;
BA_ "UserSigValidity" SG_ 362 RSPA_HdLmpReq 3;
BA_ "Description" SG_ 362 RSPA_HdLmpReq "Head lamp request of RSPA";
BA_ "Version" SG_ 362 MRA_CamDispSta "24.02.00";
BA_ "RoutingFactor" SG_ 362 MRA_CamDispSta 5;
BA_ "UserSigValidity" SG_ 362 MRA_CamDispSta 3;
BA_ "Description" SG_ 362 MRA_CamDispSta "When MRA Operates, Request display Cam view";
BA_ "Version" SG_ 362 RSPA_BtnDispSta "24.02.00";
BA_ "RoutingFactor" SG_ 362 RSPA_BtnDispSta 5;
BA_ "UserSigValidity" SG_ 362 RSPA_BtnDispSta 3;
BA_ "Description" SG_ 362 RSPA_BtnDispSta "Request display of RSPA Button";
BA_ "Version" SG_ 362 RSPA_OSMirFoldReq "19.08.08";
BA_ "RoutingFactor" SG_ 362 RSPA_OSMirFoldReq 5;
BA_ "UserSigValidity" SG_ 362 RSPA_OSMirFoldReq 3;
BA_ "Description" SG_ 362 RSPA_OSMirFoldReq "OS Mirror folding/unfolding request of RSPA";
BA_ "Version" SG_ 362 RSPA_AvnModDis "17.11.00";
BA_ "RoutingFactor" SG_ 362 RSPA_AvnModDis 5;
BA_ "UserSigValidity" SG_ 362 RSPA_AvnModDis 3;
BA_ "Description" SG_ 362 RSPA_AvnModDis "AVN╗є└╟ ╕Ё╡х╝▒┼├ ╕▐┤║ ╟е├т└╗ └з╟╤ ┴╓┬ў/├т┬ў ▒╕║╨ ┴д║╕

'-CGW routing ╟╩┐ф (CCAN to MMCAN)";
BA_ "Version" SG_ 362 RSPA_AvnSubViewDis "17.11.00";
BA_ "RoutingFactor" SG_ 362 RSPA_AvnSubViewDis 5;
BA_ "UserSigValidity" SG_ 362 RSPA_AvnSubViewDis 3;
BA_ "Description" SG_ 362 RSPA_AvnSubViewDis "AVN┐б╝н ╟е├т╟╪╛▀╟╥ Topview┐╡┐к ┤ы├╝└╠╣╠┴Ў ├т╖┬┐ф├╗

'-CGW routing ╟╩┐ф (CCAN to MMCAN)";
BA_ "Version" SG_ 362 MRA_AVNDispSta "24.01.04";
BA_ "RoutingFactor" SG_ 362 MRA_AVNDispSta 5;
BA_ "UserSigValidity" SG_ 362 MRA_AVNDispSta 3;
BA_ "Description" SG_ 362 MRA_AVNDispSta "Request display of MRA";
BA_ "Version" SG_ 362 RSPA_DgtKeyVer "23.10.11";
BA_ "RoutingFactor" SG_ 362 RSPA_DgtKeyVer 5;
BA_ "UserSigValidity" SG_ 362 RSPA_DgtKeyVer 3;
BA_ "Description" SG_ 362 RSPA_DgtKeyVer "RSPA Digital Key Version";
BA_ "Version" SG_ 362 RSPA_AvnHmiDis "24.05.00";
BA_ "RoutingFactor" SG_ 362 RSPA_AvnHmiDis 5;
BA_ "UserSigValidity" SG_ 362 RSPA_AvnHmiDis 3;
BA_ "Description" SG_ 362 RSPA_AvnHmiDis "RSPA HMI display information displayed by AVN

'-CGW routing required (CCAN to MMCAN)";
BA_ "Version" SG_ 362 MRA_AVNHMIDispSta "24.05.11";
BA_ "RoutingFactor" SG_ 362 MRA_AVNHMIDispSta 5;
BA_ "UserSigValidity" SG_ 362 MRA_AVNHMIDispSta 3;
BA_ "Description" SG_ 362 MRA_AVNHMIDispSta "MRA HMI display information";
BA_ "Version" SG_ 362 RSPA_RWS_AnglReq "23.07.02";
BA_ "RoutingFactor" SG_ 362 RSPA_RWS_AnglReq 5;
BA_ "UserSigValidity" SG_ 362 RSPA_RWS_AnglReq 3;
BA_ "GenSigStartValue" SG_ 362 RSPA_RWS_AnglReq 127;
BA_ "Description" SG_ 362 RSPA_RWS_AnglReq "This value is used to set a Rear Wheel Steering angle target for the RSPA function.

0x00~0xFD:Real Values

0xFE:RESERVED

0xFF:Error Indicator";
BA_ "Version" SG_ 2281701472 L_BDC_FD_ROA_Crc1Val "23.01.02";
BA_ "UserSigValidity" SG_ 2281701472 L_BDC_FD_ROA_Crc1Val 3;
BA_ "GenSigStartValue" SG_ 2281701472 L_BDC_FD_ROA_Crc1Val 65535;
BA_ "GenSigSendType" SG_ 2281701472 L_BDC_FD_ROA_Crc1Val 4;
BA_ "Description" SG_ 2281701472 L_BDC_FD_ROA_Crc1Val "The data area for CRC calculation is based on the data length (DLC) of the message DB.

The CRC shall be calculated over the entire data block (excluding the CRC bytes) including the user data, alive counter and Data ID



- CRC Polynomial (0x1021) , Ini";
BA_ "Version" SG_ 2281701472 L_BDC_FD_ROA_AlvCnt1Val "23.01.02";
BA_ "UserSigValidity" SG_ 2281701472 L_BDC_FD_ROA_AlvCnt1Val 3;
BA_ "GenSigSendType" SG_ 2281701472 L_BDC_FD_ROA_AlvCnt1Val 4;
BA_ "Description" SG_ 2281701472 L_BDC_FD_ROA_AlvCnt1Val "For the first transmission request for a data element the counter shall be initialized with 0 and shall be incremented by 1 for every subsequent send request. 

When the counter reaches the maximum value(0xFF), then it shall restart with 0 for the next s";
BA_ "Version" SG_ 2281701472 ROA_SnsrRunReq "23.01.02";
BA_ "UserSigValidity" SG_ 2281701472 ROA_SnsrRunReq 0;
BA_ "GenSigSendType" SG_ 2281701472 ROA_SnsrRunReq 4;
BA_ "Version" SG_ 2281701472 ROA_DiaReq "23.01.02";
BA_ "UserSigValidity" SG_ 2281701472 ROA_DiaReq 0;
BA_ "GenSigSendType" SG_ 2281701472 ROA_DiaReq 4;
BA_ "Version" SG_ 2281701472 ROA_Region_Opt "23.01.02";
BA_ "UserSigValidity" SG_ 2281701472 ROA_Region_Opt 0;
BA_ "GenSigSendType" SG_ 2281701472 ROA_Region_Opt 4;
BA_ "Version" SG_ 2281701472 ROA_EngSta "23.01.02";
BA_ "UserSigValidity" SG_ 2281701472 ROA_EngSta 0;
BA_ "GenSigSendType" SG_ 2281701472 ROA_EngSta 4;
BA_ "Version" SG_ 2683310288 ROA_FR_Debug_00 "23.07.02";
BA_ "UserSigValidity" SG_ 2683310288 ROA_FR_Debug_00 0;
BA_ "GenSigSendType" SG_ 2683310288 ROA_FR_Debug_00 2;
BA_ "Version" SG_ 2683310288 ROA_FR_Debug_02 "23.07.02";
BA_ "UserSigValidity" SG_ 2683310288 ROA_FR_Debug_02 0;
BA_ "GenSigSendType" SG_ 2683310288 ROA_FR_Debug_02 2;
BA_ "Version" SG_ 2683310288 ROA_FR_Debug_03 "23.07.02";
BA_ "UserSigValidity" SG_ 2683310288 ROA_FR_Debug_03 0;
BA_ "GenSigSendType" SG_ 2683310288 ROA_FR_Debug_03 2;
BA_ "Version" SG_ 2683310288 ROA_FR_Debug_01 "23.07.02";
BA_ "UserSigValidity" SG_ 2683310288 ROA_FR_Debug_01 0;
BA_ "GenSigSendType" SG_ 2683310288 ROA_FR_Debug_01 2;
BA_ "Version" SG_ 1494 GST_ROA_FR_Byte0 "22.08.01";
BA_ "NetworkRequestHoldingTime" SG_ 1494 GST_ROA_FR_Byte0 5000;
BA_ "NetworkRequest" SG_ 1494 GST_ROA_FR_Byte0 0;
BA_ "UserSigValidity" SG_ 1494 GST_ROA_FR_Byte0 0;
BA_ "UsrSigPurpose" SG_ 1494 GST_ROA_FR_Byte0 3;
BA_ "Description" SG_ 1494 GST_ROA_FR_Byte0 "TP Index : 320";
BA_ "Version" SG_ 1494 GST_ROA_FR_Byte2 "22.08.01";
BA_ "NetworkRequestHoldingTime" SG_ 1494 GST_ROA_FR_Byte2 5000;
BA_ "NetworkRequest" SG_ 1494 GST_ROA_FR_Byte2 0;
BA_ "UserSigValidity" SG_ 1494 GST_ROA_FR_Byte2 0;
BA_ "UsrSigPurpose" SG_ 1494 GST_ROA_FR_Byte2 3;
BA_ "Description" SG_ 1494 GST_ROA_FR_Byte2 "TP Index : 320";
BA_ "Version" SG_ 1494 GST_ROA_FR_Byte3 "22.08.01";
BA_ "NetworkRequestHoldingTime" SG_ 1494 GST_ROA_FR_Byte3 5000;
BA_ "NetworkRequest" SG_ 1494 GST_ROA_FR_Byte3 0;
BA_ "UserSigValidity" SG_ 1494 GST_ROA_FR_Byte3 0;
BA_ "UsrSigPurpose" SG_ 1494 GST_ROA_FR_Byte3 3;
BA_ "Description" SG_ 1494 GST_ROA_FR_Byte3 "TP Index : 320";
BA_ "Version" SG_ 1494 GST_ROA_FR_Byte4 "22.08.01";
BA_ "NetworkRequestHoldingTime" SG_ 1494 GST_ROA_FR_Byte4 5000;
BA_ "NetworkRequest" SG_ 1494 GST_ROA_FR_Byte4 0;
BA_ "UserSigValidity" SG_ 1494 GST_ROA_FR_Byte4 0;
BA_ "UsrSigPurpose" SG_ 1494 GST_ROA_FR_Byte4 3;
BA_ "Description" SG_ 1494 GST_ROA_FR_Byte4 "TP Index : 320";
BA_ "Version" SG_ 1494 GST_ROA_FR_Byte5 "22.08.01";
BA_ "NetworkRequestHoldingTime" SG_ 1494 GST_ROA_FR_Byte5 5000;
BA_ "NetworkRequest" SG_ 1494 GST_ROA_FR_Byte5 0;
BA_ "UserSigValidity" SG_ 1494 GST_ROA_FR_Byte5 0;
BA_ "UsrSigPurpose" SG_ 1494 GST_ROA_FR_Byte5 3;
BA_ "Description" SG_ 1494 GST_ROA_FR_Byte5 "TP Index : 320";
BA_ "Version" SG_ 1494 GST_ROA_FR_Byte6 "22.08.01";
BA_ "NetworkRequestHoldingTime" SG_ 1494 GST_ROA_FR_Byte6 5000;
BA_ "NetworkRequest" SG_ 1494 GST_ROA_FR_Byte6 0;
BA_ "UserSigValidity" SG_ 1494 GST_ROA_FR_Byte6 0;
BA_ "UsrSigPurpose" SG_ 1494 GST_ROA_FR_Byte6 3;
BA_ "Description" SG_ 1494 GST_ROA_FR_Byte6 "TP Index : 320";
BA_ "Version" SG_ 1494 GST_ROA_FR_Byte7 "22.08.01";
BA_ "NetworkRequestHoldingTime" SG_ 1494 GST_ROA_FR_Byte7 5000;
BA_ "NetworkRequest" SG_ 1494 GST_ROA_FR_Byte7 0;
BA_ "UserSigValidity" SG_ 1494 GST_ROA_FR_Byte7 0;
BA_ "UsrSigPurpose" SG_ 1494 GST_ROA_FR_Byte7 3;
BA_ "Description" SG_ 1494 GST_ROA_FR_Byte7 "TP Index : 320";
BA_ "Version" SG_ 1494 GST_ROA_FR_Byte1 "22.08.01";
BA_ "NetworkRequestHoldingTime" SG_ 1494 GST_ROA_FR_Byte1 5000;
BA_ "NetworkRequest" SG_ 1494 GST_ROA_FR_Byte1 0;
BA_ "UserSigValidity" SG_ 1494 GST_ROA_FR_Byte1 0;
BA_ "UsrSigPurpose" SG_ 1494 GST_ROA_FR_Byte1 3;
BA_ "Description" SG_ 1494 GST_ROA_FR_Byte1 "TP Index : 320";
BA_ "Version" SG_ 2281701521 L_DHRR_FD_Crc20Val "23.06.01";
BA_ "UserSigValidity" SG_ 2281701521 L_DHRR_FD_Crc20Val 3;
BA_ "GenSigStartValue" SG_ 2281701521 L_DHRR_FD_Crc20Val 65535;
BA_ "GenSigSendType" SG_ 2281701521 L_DHRR_FD_Crc20Val 4;
BA_ "Description" SG_ 2281701521 L_DHRR_FD_Crc20Val "The data area for CRC calculation is based on the data length (DLC) of the message DB.

The CRC shall be calculated over the entire data block (excluding the CRC bytes) including the user data, alive counter and Data ID



- CRC Polynomial (0x1021) , Ini";
BA_ "Version" SG_ 2281701521 L_DHRR_FD_AlvCnt20Val "23.06.01";
BA_ "UserSigValidity" SG_ 2281701521 L_DHRR_FD_AlvCnt20Val 3;
BA_ "GenSigSendType" SG_ 2281701521 L_DHRR_FD_AlvCnt20Val 4;
BA_ "Description" SG_ 2281701521 L_DHRR_FD_AlvCnt20Val "For the first transmission request for a data element the counter shall be initialized with 0 and shall be incremented by 1 for every subsequent send request. 

When the counter reaches the maximum value(0xFF), then it shall restart with 0 for the next s";
BA_ "Version" SG_ 2281701521 DHRR_Status "23.06.01";
BA_ "UserSigValidity" SG_ 2281701521 DHRR_Status 0;
BA_ "GenSigSendType" SG_ 2281701521 DHRR_Status 4;
BA_ "Version" SG_ 2281701521 DHRR_Rain_Sta "23.06.01";
BA_ "UserSigValidity" SG_ 2281701521 DHRR_Rain_Sta 0;
BA_ "GenSigSendType" SG_ 2281701521 DHRR_Rain_Sta 4;
BA_ "Version" SG_ 2281701521 DHRR_PhnDet_Sta "23.06.01";
BA_ "UserSigValidity" SG_ 2281701521 DHRR_PhnDet_Sta 0;
BA_ "GenSigSendType" SG_ 2281701521 DHRR_PhnDet_Sta 4;
BA_ "Version" SG_ 2281701521 DHRR_TglDet_Sta "23.06.01";
BA_ "UserSigValidity" SG_ 2281701521 DHRR_TglDet_Sta 0;
BA_ "GenSigSendType" SG_ 2281701521 DHRR_TglDet_Sta 4;
BA_ "Version" SG_ 2281701521 DHRR_UnlckDet_Sta "23.06.01";
BA_ "UserSigValidity" SG_ 2281701521 DHRR_UnlckDet_Sta 0;
BA_ "GenSigSendType" SG_ 2281701521 DHRR_UnlckDet_Sta 4;
BA_ "Version" SG_ 2281701521 DHRR_LckDet_Sta "23.06.01";
BA_ "UserSigValidity" SG_ 2281701521 DHRR_LckDet_Sta 0;
BA_ "GenSigSendType" SG_ 2281701521 DHRR_LckDet_Sta 4;
BA_ "Version" SG_ 2281701521 DHRR_NFCPollingStatus_Dvp "24.01.00";
BA_ "UserSigValidity" SG_ 2281701521 DHRR_NFCPollingStatus_Dvp 0;
BA_ "GenSigSendType" SG_ 2281701521 DHRR_NFCPollingStatus_Dvp 4;
BA_ "Description" SG_ 2281701521 DHRR_NFCPollingStatus_Dvp "NFC polling status signal from DHRR for develop";
BA_ "Version" SG_ 2281701521 DHRR_ResetOpsta "24.06.01";
BA_ "UserSigValidity" SG_ 2281701521 DHRR_ResetOpsta 0;
BA_ "GenSigSendType" SG_ 2281701521 DHRR_ResetOpsta 4;
BA_ "Description" SG_ 2281701521 DHRR_ResetOpsta "This signal indicates whether the reset operation has been completed or not";
BA_ "Version" SG_ 2281701521 DHRR_Diag_Sta "23.06.01";
BA_ "UserSigValidity" SG_ 2281701521 DHRR_Diag_Sta 0;
BA_ "GenSigSendType" SG_ 2281701521 DHRR_Diag_Sta 4;
BA_ "Version" SG_ 2683310289 ROA_FR_Debug_04 "23.07.02";
BA_ "UserSigValidity" SG_ 2683310289 ROA_FR_Debug_04 0;
BA_ "GenSigSendType" SG_ 2683310289 ROA_FR_Debug_04 2;
BA_ "Version" SG_ 2683310289 ROA_FR_Debug_06 "23.07.02";
BA_ "UserSigValidity" SG_ 2683310289 ROA_FR_Debug_06 0;
BA_ "GenSigSendType" SG_ 2683310289 ROA_FR_Debug_06 2;
BA_ "Version" SG_ 2683310289 ROA_FR_Debug_07 "23.07.02";
BA_ "UserSigValidity" SG_ 2683310289 ROA_FR_Debug_07 0;
BA_ "GenSigSendType" SG_ 2683310289 ROA_FR_Debug_07 2;
BA_ "Version" SG_ 2683310289 ROA_FR_Debug_05 "23.07.02";
BA_ "UserSigValidity" SG_ 2683310289 ROA_FR_Debug_05 0;
BA_ "GenSigSendType" SG_ 2683310289 ROA_FR_Debug_05 2;
BA_ "Version" SG_ 2281701520 L_DHR_FD_Crc20Val "23.01.02";
BA_ "UserSigValidity" SG_ 2281701520 L_DHR_FD_Crc20Val 3;
BA_ "GenSigStartValue" SG_ 2281701520 L_DHR_FD_Crc20Val 65535;
BA_ "GenSigSendType" SG_ 2281701520 L_DHR_FD_Crc20Val 4;
BA_ "Description" SG_ 2281701520 L_DHR_FD_Crc20Val "The data area for CRC calculation is based on the data length (DLC) of the message DB.

The CRC shall be calculated over the entire data block (excluding the CRC bytes) including the user data, alive counter and Data ID



- CRC Polynomial (0x1021) , Ini";
BA_ "Version" SG_ 2281701520 L_DHR_FD_AlvCnt20Val "23.01.02";
BA_ "UserSigValidity" SG_ 2281701520 L_DHR_FD_AlvCnt20Val 3;
BA_ "GenSigSendType" SG_ 2281701520 L_DHR_FD_AlvCnt20Val 4;
BA_ "Description" SG_ 2281701520 L_DHR_FD_AlvCnt20Val "For the first transmission request for a data element the counter shall be initialized with 0 and shall be incremented by 1 for every subsequent send request. 

When the counter reaches the maximum value(0xFF), then it shall restart with 0 for the next s";
BA_ "Version" SG_ 2281701520 DHR_Status "23.01.02";
BA_ "UserSigValidity" SG_ 2281701520 DHR_Status 0;
BA_ "GenSigSendType" SG_ 2281701520 DHR_Status 4;
BA_ "Version" SG_ 2281701520 DHR_Rain_Sta "23.02.11";
BA_ "UserSigValidity" SG_ 2281701520 DHR_Rain_Sta 0;
BA_ "GenSigSendType" SG_ 2281701520 DHR_Rain_Sta 4;
BA_ "Version" SG_ 2281701520 DHR_PhnDet_Sta "23.02.11";
BA_ "UserSigValidity" SG_ 2281701520 DHR_PhnDet_Sta 0;
BA_ "GenSigSendType" SG_ 2281701520 DHR_PhnDet_Sta 4;
BA_ "Version" SG_ 2281701520 DHR_TglDet_Sta "23.01.02";
BA_ "UserSigValidity" SG_ 2281701520 DHR_TglDet_Sta 0;
BA_ "GenSigSendType" SG_ 2281701520 DHR_TglDet_Sta 4;
BA_ "Version" SG_ 2281701520 DHR_UnlckDet_Sta "23.01.02";
BA_ "UserSigValidity" SG_ 2281701520 DHR_UnlckDet_Sta 0;
BA_ "GenSigSendType" SG_ 2281701520 DHR_UnlckDet_Sta 4;
BA_ "Version" SG_ 2281701520 DHR_LckDet_Sta "23.01.02";
BA_ "UserSigValidity" SG_ 2281701520 DHR_LckDet_Sta 0;
BA_ "GenSigSendType" SG_ 2281701520 DHR_LckDet_Sta 4;
BA_ "Version" SG_ 2281701520 DHR_NFCPollingStatus_Dvp "24.01.00";
BA_ "UserSigValidity" SG_ 2281701520 DHR_NFCPollingStatus_Dvp 0;
BA_ "GenSigSendType" SG_ 2281701520 DHR_NFCPollingStatus_Dvp 4;
BA_ "Description" SG_ 2281701520 DHR_NFCPollingStatus_Dvp "NFC polling status signal from DHR for develop";
BA_ "Version" SG_ 2281701520 DHR_ResetOpSta "24.06.01";
BA_ "UserSigValidity" SG_ 2281701520 DHR_ResetOpSta 0;
BA_ "GenSigSendType" SG_ 2281701520 DHR_ResetOpSta 4;
BA_ "Description" SG_ 2281701520 DHR_ResetOpSta "This signal indicates whether the reset operation has been completed or not";
BA_ "Version" SG_ 2281701520 DHR_Diag_Sta "23.02.11";
BA_ "UserSigValidity" SG_ 2281701520 DHR_Diag_Sta 0;
BA_ "GenSigSendType" SG_ 2281701520 DHR_Diag_Sta 4;
BA_ "Version" SG_ 2683310290 ROA_FR_Debug_08 "23.07.02";
BA_ "UserSigValidity" SG_ 2683310290 ROA_FR_Debug_08 0;
BA_ "GenSigSendType" SG_ 2683310290 ROA_FR_Debug_08 2;
BA_ "Version" SG_ 2521143297 L_UWB_BLE_SLV_FD_Crc12Val "24.07.05";
BA_ "RoutingFactor" SG_ 2521143297 L_UWB_BLE_SLV_FD_Crc12Val 0;
BA_ "UserSigValidity" SG_ 2521143297 L_UWB_BLE_SLV_FD_Crc12Val 3;
BA_ "GenSigStartValue" SG_ 2521143297 L_UWB_BLE_SLV_FD_Crc12Val 65535;
BA_ "GenSigSendType" SG_ 2521143297 L_UWB_BLE_SLV_FD_Crc12Val 2;
BA_ "Description" SG_ 2521143297 L_UWB_BLE_SLV_FD_Crc12Val "The data area for CRC calculation is based on the data length (DLC) of the message DB.

The CRC shall be calculated over the entire data block (excluding the CRC bytes) including the user data, alive counter and Data ID



- CRC Polynomial (0x1021) , Ini";
BA_ "Version" SG_ 2521143297 L_UWB_BLE_SLV_FD_AlvCnt12Val "24.07.05";
BA_ "RoutingFactor" SG_ 2521143297 L_UWB_BLE_SLV_FD_AlvCnt12Val 0;
BA_ "UserSigValidity" SG_ 2521143297 L_UWB_BLE_SLV_FD_AlvCnt12Val 3;
BA_ "GenSigSendType" SG_ 2521143297 L_UWB_BLE_SLV_FD_AlvCnt12Val 2;
BA_ "Description" SG_ 2521143297 L_UWB_BLE_SLV_FD_AlvCnt12Val "For the first transmission request for a data element the counter shall be initialized with 0 and shall be incremented by 1 for every subsequent send request. 

When the counter reaches the maximum value(0xFF), then it shall restart with 0 for the next s";
BA_ "Version" SG_ 2521143297 SLV_SWID_3_IVD_2 "24.07.05";
BA_ "RoutingFactor" SG_ 2521143297 SLV_SWID_3_IVD_2 0;
BA_ "UserSigValidity" SG_ 2521143297 SLV_SWID_3_IVD_2 0;
BA_ "GenSigSendType" SG_ 2521143297 SLV_SWID_3_IVD_2 2;
BA_ "Version" SG_ 1502 ROA_FR_GST_Byte0 "22.08.01";
BA_ "UserSigValidity" SG_ 1502 ROA_FR_GST_Byte0 0;
BA_ "UsrSigPurpose" SG_ 1502 ROA_FR_GST_Byte0 4;
BA_ "Description" SG_ 1502 ROA_FR_GST_Byte0 "TP Index : 320";
BA_ "Version" SG_ 1502 ROA_FR_GST_Byte2 "22.08.01";
BA_ "UserSigValidity" SG_ 1502 ROA_FR_GST_Byte2 0;
BA_ "UsrSigPurpose" SG_ 1502 ROA_FR_GST_Byte2 4;
BA_ "Description" SG_ 1502 ROA_FR_GST_Byte2 "TP Index : 320";
BA_ "Version" SG_ 1502 ROA_FR_GST_Byte3 "22.08.01";
BA_ "UserSigValidity" SG_ 1502 ROA_FR_GST_Byte3 0;
BA_ "UsrSigPurpose" SG_ 1502 ROA_FR_GST_Byte3 4;
BA_ "Description" SG_ 1502 ROA_FR_GST_Byte3 "TP Index : 320";
BA_ "Version" SG_ 1502 ROA_FR_GST_Byte4 "22.08.01";
BA_ "UserSigValidity" SG_ 1502 ROA_FR_GST_Byte4 0;
BA_ "UsrSigPurpose" SG_ 1502 ROA_FR_GST_Byte4 4;
BA_ "Description" SG_ 1502 ROA_FR_GST_Byte4 "TP Index : 320";
BA_ "Version" SG_ 1502 ROA_FR_GST_Byte5 "22.08.01";
BA_ "UserSigValidity" SG_ 1502 ROA_FR_GST_Byte5 0;
BA_ "UsrSigPurpose" SG_ 1502 ROA_FR_GST_Byte5 4;
BA_ "Description" SG_ 1502 ROA_FR_GST_Byte5 "TP Index : 320";
BA_ "Version" SG_ 1502 ROA_FR_GST_Byte6 "22.08.01";
BA_ "UserSigValidity" SG_ 1502 ROA_FR_GST_Byte6 0;
BA_ "UsrSigPurpose" SG_ 1502 ROA_FR_GST_Byte6 4;
BA_ "Description" SG_ 1502 ROA_FR_GST_Byte6 "TP Index : 320";
BA_ "Version" SG_ 1502 ROA_FR_GST_Byte7 "22.08.01";
BA_ "UserSigValidity" SG_ 1502 ROA_FR_GST_Byte7 0;
BA_ "UsrSigPurpose" SG_ 1502 ROA_FR_GST_Byte7 4;
BA_ "Description" SG_ 1502 ROA_FR_GST_Byte7 "TP Index : 320";
BA_ "Version" SG_ 1502 ROA_FR_GST_Byte1 "22.08.01";
BA_ "UserSigValidity" SG_ 1502 ROA_FR_GST_Byte1 0;
BA_ "UsrSigPurpose" SG_ 1502 ROA_FR_GST_Byte1 4;
BA_ "Description" SG_ 1502 ROA_FR_GST_Byte1 "TP Index : 320";
BA_ "Version" SG_ 2683310273 ROA_FR_Dev_01 "23.07.02";
BA_ "UserSigValidity" SG_ 2683310273 ROA_FR_Dev_01 0;
BA_ "GenSigSendType" SG_ 2683310273 ROA_FR_Dev_01 2;
BA_ "Version" SG_ 2281701504 L_DHL_FD_Crc20Val "23.01.02";
BA_ "UserSigValidity" SG_ 2281701504 L_DHL_FD_Crc20Val 3;
BA_ "GenSigStartValue" SG_ 2281701504 L_DHL_FD_Crc20Val 65535;
BA_ "GenSigSendType" SG_ 2281701504 L_DHL_FD_Crc20Val 4;
BA_ "Description" SG_ 2281701504 L_DHL_FD_Crc20Val "The data area for CRC calculation is based on the data length (DLC) of the message DB.

The CRC shall be calculated over the entire data block (excluding the CRC bytes) including the user data, alive counter and Data ID



- CRC Polynomial (0x1021) , Ini";
BA_ "Version" SG_ 2281701504 L_DHL_FD_AlvCnt20Val "23.01.02";
BA_ "UserSigValidity" SG_ 2281701504 L_DHL_FD_AlvCnt20Val 3;
BA_ "GenSigSendType" SG_ 2281701504 L_DHL_FD_AlvCnt20Val 4;
BA_ "Description" SG_ 2281701504 L_DHL_FD_AlvCnt20Val "For the first transmission request for a data element the counter shall be initialized with 0 and shall be incremented by 1 for every subsequent send request. 

When the counter reaches the maximum value(0xFF), then it shall restart with 0 for the next s";
BA_ "Version" SG_ 2281701504 DHL_Status "23.01.02";
BA_ "UserSigValidity" SG_ 2281701504 DHL_Status 0;
BA_ "GenSigSendType" SG_ 2281701504 DHL_Status 4;
BA_ "Version" SG_ 2281701504 DHL_Rain_Sta "23.02.11";
BA_ "UserSigValidity" SG_ 2281701504 DHL_Rain_Sta 0;
BA_ "GenSigSendType" SG_ 2281701504 DHL_Rain_Sta 4;
BA_ "Version" SG_ 2281701504 DHL_PhnDet_Sta "23.02.11";
BA_ "UserSigValidity" SG_ 2281701504 DHL_PhnDet_Sta 0;
BA_ "GenSigSendType" SG_ 2281701504 DHL_PhnDet_Sta 4;
BA_ "Version" SG_ 2281701504 DHL_TglDet_Sta "23.01.02";
BA_ "UserSigValidity" SG_ 2281701504 DHL_TglDet_Sta 0;
BA_ "GenSigSendType" SG_ 2281701504 DHL_TglDet_Sta 4;
BA_ "Version" SG_ 2281701504 DHL_UnlckDet_Sta "23.01.02";
BA_ "UserSigValidity" SG_ 2281701504 DHL_UnlckDet_Sta 0;
BA_ "GenSigSendType" SG_ 2281701504 DHL_UnlckDet_Sta 4;
BA_ "Version" SG_ 2281701504 DHL_LckDet_Sta "23.01.02";
BA_ "UserSigValidity" SG_ 2281701504 DHL_LckDet_Sta 0;
BA_ "GenSigSendType" SG_ 2281701504 DHL_LckDet_Sta 4;
BA_ "Version" SG_ 2281701504 DHL_NFCPollingStatus_Dvp "24.01.00";
BA_ "UserSigValidity" SG_ 2281701504 DHL_NFCPollingStatus_Dvp 0;
BA_ "GenSigSendType" SG_ 2281701504 DHL_NFCPollingStatus_Dvp 4;
BA_ "Description" SG_ 2281701504 DHL_NFCPollingStatus_Dvp "NFC polling status signal from DHL for develop";
BA_ "Version" SG_ 2281701504 DHL_ResetOpsta "24.06.01";
BA_ "UserSigValidity" SG_ 2281701504 DHL_ResetOpsta 0;
BA_ "GenSigSendType" SG_ 2281701504 DHL_ResetOpsta 4;
BA_ "Description" SG_ 2281701504 DHL_ResetOpsta "This signal indicates whether the reset operation has been completed or not";
BA_ "Version" SG_ 2281701504 DHL_Diag_Sta "23.02.11";
BA_ "UserSigValidity" SG_ 2281701504 DHL_Diag_Sta 0;
BA_ "GenSigSendType" SG_ 2281701504 DHL_Diag_Sta 4;
BA_ "Version" SG_ 2683310272 ROA_FR_Dev_00 "23.07.02";
BA_ "UserSigValidity" SG_ 2683310272 ROA_FR_Dev_00 0;
BA_ "GenSigSendType" SG_ 2683310272 ROA_FR_Dev_00 2;
BA_ "Version" SG_ 2281701505 L_DHRL_FD_Crc20Val "23.06.01";
BA_ "UserSigValidity" SG_ 2281701505 L_DHRL_FD_Crc20Val 3;
BA_ "GenSigStartValue" SG_ 2281701505 L_DHRL_FD_Crc20Val 65535;
BA_ "GenSigSendType" SG_ 2281701505 L_DHRL_FD_Crc20Val 4;
BA_ "Description" SG_ 2281701505 L_DHRL_FD_Crc20Val "The data area for CRC calculation is based on the data length (DLC) of the message DB.

The CRC shall be calculated over the entire data block (excluding the CRC bytes) including the user data, alive counter and Data ID



- CRC Polynomial (0x1021) , Ini";
BA_ "Version" SG_ 2281701505 L_DHRL_FD_AlvCnt20Val "23.06.01";
BA_ "UserSigValidity" SG_ 2281701505 L_DHRL_FD_AlvCnt20Val 3;
BA_ "GenSigSendType" SG_ 2281701505 L_DHRL_FD_AlvCnt20Val 4;
BA_ "Description" SG_ 2281701505 L_DHRL_FD_AlvCnt20Val "For the first transmission request for a data element the counter shall be initialized with 0 and shall be incremented by 1 for every subsequent send request. 

When the counter reaches the maximum value(0xFF), then it shall restart with 0 for the next s";
BA_ "Version" SG_ 2281701505 DHRL_Status "23.06.01";
BA_ "UserSigValidity" SG_ 2281701505 DHRL_Status 0;
BA_ "GenSigSendType" SG_ 2281701505 DHRL_Status 4;
BA_ "Version" SG_ 2281701505 DHRL_Rain_Sta "23.06.01";
BA_ "UserSigValidity" SG_ 2281701505 DHRL_Rain_Sta 0;
BA_ "GenSigSendType" SG_ 2281701505 DHRL_Rain_Sta 4;
BA_ "Version" SG_ 2281701505 DHRL_PhnDet_Sta "23.06.01";
BA_ "UserSigValidity" SG_ 2281701505 DHRL_PhnDet_Sta 0;
BA_ "GenSigSendType" SG_ 2281701505 DHRL_PhnDet_Sta 4;
BA_ "Version" SG_ 2281701505 DHRL_TglDet_Sta "23.06.01";
BA_ "UserSigValidity" SG_ 2281701505 DHRL_TglDet_Sta 0;
BA_ "GenSigSendType" SG_ 2281701505 DHRL_TglDet_Sta 4;
BA_ "Version" SG_ 2281701505 DHRL_UnlckDet_Sta "23.06.01";
BA_ "UserSigValidity" SG_ 2281701505 DHRL_UnlckDet_Sta 0;
BA_ "GenSigSendType" SG_ 2281701505 DHRL_UnlckDet_Sta 4;
BA_ "Version" SG_ 2281701505 DHRL_LckDet_Sta "23.06.01";
BA_ "UserSigValidity" SG_ 2281701505 DHRL_LckDet_Sta 0;
BA_ "GenSigSendType" SG_ 2281701505 DHRL_LckDet_Sta 4;
BA_ "Version" SG_ 2281701505 DHRL_NFCPollingStatus_Dvp "24.01.00";
BA_ "UserSigValidity" SG_ 2281701505 DHRL_NFCPollingStatus_Dvp 0;
BA_ "GenSigSendType" SG_ 2281701505 DHRL_NFCPollingStatus_Dvp 4;
BA_ "Description" SG_ 2281701505 DHRL_NFCPollingStatus_Dvp "NFC polling status signal from DHRL for develop";
BA_ "Version" SG_ 2281701505 DHRL_ResetOpSta "24.06.01";
BA_ "UserSigValidity" SG_ 2281701505 DHRL_ResetOpSta 0;
BA_ "GenSigSendType" SG_ 2281701505 DHRL_ResetOpSta 4;
BA_ "Description" SG_ 2281701505 DHRL_ResetOpSta "This signal indicates whether the reset operation has been completed or not";
BA_ "Version" SG_ 2281701505 DHRL_Diag_Sta "23.06.01";
BA_ "UserSigValidity" SG_ 2281701505 DHRL_Diag_Sta 0;
BA_ "GenSigSendType" SG_ 2281701505 DHRL_Diag_Sta 4;
BA_ "Version" SG_ 2683310275 ROA_FR_Dev_03 "23.07.02";
BA_ "UserSigValidity" SG_ 2683310275 ROA_FR_Dev_03 0;
BA_ "GenSigSendType" SG_ 2683310275 ROA_FR_Dev_03 2;
BA_ "Version" SG_ 2683310274 ROA_FR_Dev_02 "23.07.02";
BA_ "UserSigValidity" SG_ 2683310274 ROA_FR_Dev_02 0;
BA_ "GenSigSendType" SG_ 2683310274 ROA_FR_Dev_02 2;
BA_ "Version" SG_ 2683310277 ROA_FR_Dev_05 "23.07.02";
BA_ "UserSigValidity" SG_ 2683310277 ROA_FR_Dev_05 0;
BA_ "GenSigSendType" SG_ 2683310277 ROA_FR_Dev_05 2;
BA_ "Version" SG_ 2525340417 L_UWB_FL_FD_Crc7Val "24.07.05";
BA_ "RoutingFactor" SG_ 2525340417 L_UWB_FL_FD_Crc7Val 0;
BA_ "UserSigValidity" SG_ 2525340417 L_UWB_FL_FD_Crc7Val 3;
BA_ "GenSigStartValue" SG_ 2525340417 L_UWB_FL_FD_Crc7Val 65535;
BA_ "GenSigSendType" SG_ 2525340417 L_UWB_FL_FD_Crc7Val 2;
BA_ "Description" SG_ 2525340417 L_UWB_FL_FD_Crc7Val "The data area for CRC calculation is based on the data length (DLC) of the message DB.

The CRC shall be calculated over the entire data block (excluding the CRC bytes) including the user data, alive counter and Data ID



- CRC Polynomial (0x1021) , Ini";
BA_ "Version" SG_ 2525340417 L_UWB_FL_FD_AlvCnt7Val "24.07.05";
BA_ "RoutingFactor" SG_ 2525340417 L_UWB_FL_FD_AlvCnt7Val 0;
BA_ "UserSigValidity" SG_ 2525340417 L_UWB_FL_FD_AlvCnt7Val 3;
BA_ "GenSigSendType" SG_ 2525340417 L_UWB_FL_FD_AlvCnt7Val 2;
BA_ "Description" SG_ 2525340417 L_UWB_FL_FD_AlvCnt7Val "For the first transmission request for a data element the counter shall be initialized with 0 and shall be incremented by 1 for every subsequent send request. 

When the counter reaches the maximum value(0xFF), then it shall restart with 0 for the next s";
BA_ "Version" SG_ 2525340417 FL_SWID_4_IVD_2 "24.07.05";
BA_ "RoutingFactor" SG_ 2525340417 FL_SWID_4_IVD_2 0;
BA_ "UserSigValidity" SG_ 2525340417 FL_SWID_4_IVD_2 0;
BA_ "GenSigSendType" SG_ 2525340417 FL_SWID_4_IVD_2 2;
BA_ "Version" SG_ 2683310276 ROA_FR_Dev_04 "23.07.02";
BA_ "UserSigValidity" SG_ 2683310276 ROA_FR_Dev_04 0;
BA_ "GenSigSendType" SG_ 2683310276 ROA_FR_Dev_04 2;
BA_ "Version" SG_ 2683310279 ROA_FR_Dev_07 "23.07.02";
BA_ "UserSigValidity" SG_ 2683310279 ROA_FR_Dev_07 0;
BA_ "GenSigSendType" SG_ 2683310279 ROA_FR_Dev_07 2;
BA_ "Version" SG_ 2683310278 ROA_FR_Dev_06 "23.07.02";
BA_ "UserSigValidity" SG_ 2683310278 ROA_FR_Dev_06 0;
BA_ "GenSigSendType" SG_ 2683310278 ROA_FR_Dev_06 2;
BA_ "Version" SG_ 2683310281 ROA_FR_Dev_09 "23.07.02";
BA_ "UserSigValidity" SG_ 2683310281 ROA_FR_Dev_09 0;
BA_ "GenSigSendType" SG_ 2683310281 ROA_FR_Dev_09 2;
BA_ "Version" SG_ 2683310280 ROA_FR_Dev_08 "23.07.02";
BA_ "UserSigValidity" SG_ 2683310280 ROA_FR_Dev_08 0;
BA_ "GenSigSendType" SG_ 2683310280 ROA_FR_Dev_08 2;
BA_ "Version" SG_ 2683310282 ROA_FR_Dev_10 "23.07.02";
BA_ "UserSigValidity" SG_ 2683310282 ROA_FR_Dev_10 0;
BA_ "GenSigSendType" SG_ 2683310282 ROA_FR_Dev_10 2;
BA_ "Version" SG_ 2521143809 L_UWB_BLE_SLV_FD_Crc14Val "24.07.05";
BA_ "RoutingFactor" SG_ 2521143809 L_UWB_BLE_SLV_FD_Crc14Val 0;
BA_ "UserSigValidity" SG_ 2521143809 L_UWB_BLE_SLV_FD_Crc14Val 3;
BA_ "GenSigStartValue" SG_ 2521143809 L_UWB_BLE_SLV_FD_Crc14Val 65535;
BA_ "GenSigSendType" SG_ 2521143809 L_UWB_BLE_SLV_FD_Crc14Val 2;
BA_ "Description" SG_ 2521143809 L_UWB_BLE_SLV_FD_Crc14Val "The data area for CRC calculation is based on the data length (DLC) of the message DB.

The CRC shall be calculated over the entire data block (excluding the CRC bytes) including the user data, alive counter and Data ID



- CRC Polynomial (0x1021) , Ini";
BA_ "Version" SG_ 2521143809 L_UWB_BLE_SLV_FD_AlvCnt14Val "24.07.05";
BA_ "RoutingFactor" SG_ 2521143809 L_UWB_BLE_SLV_FD_AlvCnt14Val 0;
BA_ "UserSigValidity" SG_ 2521143809 L_UWB_BLE_SLV_FD_AlvCnt14Val 3;
BA_ "GenSigSendType" SG_ 2521143809 L_UWB_BLE_SLV_FD_AlvCnt14Val 2;
BA_ "Description" SG_ 2521143809 L_UWB_BLE_SLV_FD_AlvCnt14Val "For the first transmission request for a data element the counter shall be initialized with 0 and shall be incremented by 1 for every subsequent send request. 

When the counter reaches the maximum value(0xFF), then it shall restart with 0 for the next s";
BA_ "Version" SG_ 2521143809 SLV_SWID_4_IVD_2 "24.07.05";
BA_ "RoutingFactor" SG_ 2521143809 SLV_SWID_4_IVD_2 0;
BA_ "UserSigValidity" SG_ 2521143809 SLV_SWID_4_IVD_2 0;
BA_ "GenSigSendType" SG_ 2521143809 SLV_SWID_4_IVD_2 2;
BA_ "Version" SG_ 2281701553 L_UWB_BLE_SLV_FD_Crc21Val "23.01.02";
BA_ "UserSigValidity" SG_ 2281701553 L_UWB_BLE_SLV_FD_Crc21Val 3;
BA_ "GenSigStartValue" SG_ 2281701553 L_UWB_BLE_SLV_FD_Crc21Val 65535;
BA_ "GenSigSendType" SG_ 2281701553 L_UWB_BLE_SLV_FD_Crc21Val 4;
BA_ "Description" SG_ 2281701553 L_UWB_BLE_SLV_FD_Crc21Val "The data area for CRC calculation is based on the data length (DLC) of the message DB.

The CRC shall be calculated over the entire data block (excluding the CRC bytes) including the user data, alive counter and Data ID



- CRC Polynomial (0x1021) , Ini";
BA_ "Version" SG_ 2281701553 SLV_SW_MCU_Ver_Major "23.01.02";
BA_ "UserSigValidity" SG_ 2281701553 SLV_SW_MCU_Ver_Major 0;
BA_ "GenSigSendType" SG_ 2281701553 SLV_SW_MCU_Ver_Major 4;
BA_ "Version" SG_ 2281701553 SLV_SW_MCU_Ver_Minor "23.01.02";
BA_ "UserSigValidity" SG_ 2281701553 SLV_SW_MCU_Ver_Minor 0;
BA_ "GenSigSendType" SG_ 2281701553 SLV_SW_MCU_Ver_Minor 4;
BA_ "Version" SG_ 2281701553 SLV_SW_UWB_Ver_Major "23.01.02";
BA_ "UserSigValidity" SG_ 2281701553 SLV_SW_UWB_Ver_Major 0;
BA_ "GenSigSendType" SG_ 2281701553 SLV_SW_UWB_Ver_Major 4;
BA_ "Version" SG_ 2281701553 SLV_SW_UWB_Ver_Minor "23.01.02";
BA_ "UserSigValidity" SG_ 2281701553 SLV_SW_UWB_Ver_Minor 0;
BA_ "GenSigSendType" SG_ 2281701553 SLV_SW_UWB_Ver_Minor 4;
BA_ "Version" SG_ 2281701553 SLV_SW_BLE_Ver_Major "23.01.02";
BA_ "UserSigValidity" SG_ 2281701553 SLV_SW_BLE_Ver_Major 0;
BA_ "GenSigSendType" SG_ 2281701553 SLV_SW_BLE_Ver_Major 4;
BA_ "Version" SG_ 2281701553 SLV_SW_BLE_Ver_Minor "23.01.02";
BA_ "UserSigValidity" SG_ 2281701553 SLV_SW_BLE_Ver_Minor 0;
BA_ "GenSigSendType" SG_ 2281701553 SLV_SW_BLE_Ver_Minor 4;
BA_ "Version" SG_ 2281701553 SLV_DTC "23.01.02";
BA_ "UserSigValidity" SG_ 2281701553 SLV_DTC 0;
BA_ "GenSigSendType" SG_ 2281701553 SLV_DTC 4;
BA_ "Version" SG_ 2281701553 L_UWB_BLE_SLV_FD_AlvCnt21Val "23.01.02";
BA_ "UserSigValidity" SG_ 2281701553 L_UWB_BLE_SLV_FD_AlvCnt21Val 3;
BA_ "GenSigSendType" SG_ 2281701553 L_UWB_BLE_SLV_FD_AlvCnt21Val 4;
BA_ "Description" SG_ 2281701553 L_UWB_BLE_SLV_FD_AlvCnt21Val "For the first transmission request for a data element the counter shall be initialized with 0 and shall be incremented by 1 for every subsequent send request. 

When the counter reaches the maximum value(0xFF), then it shall restart with 0 for the next s";
BA_ "Version" SG_ 2281701553 SLV_DTC_BLE "23.11.10";
BA_ "UserSigValidity" SG_ 2281701553 SLV_DTC_BLE 0;
BA_ "GenSigSendType" SG_ 2281701553 SLV_DTC_BLE 4;
BA_ "Description" SG_ 2281701553 SLV_DTC_BLE "Valid Range : 0x00 ~ 0xFF";
BA_ "Version" SG_ 2281701553 SLV_UWB_Status1 "24.04.04";
BA_ "UserSigValidity" SG_ 2281701553 SLV_UWB_Status1 0;
BA_ "GenSigSendType" SG_ 2281701553 SLV_UWB_Status1 4;
BA_ "Description" SG_ 2281701553 SLV_UWB_Status1 "UWB_SLAVE Processing Status 1";
BA_ "Version" SG_ 2281701553 SLV_UWB_Status2 "24.04.04";
BA_ "UserSigValidity" SG_ 2281701553 SLV_UWB_Status2 0;
BA_ "GenSigSendType" SG_ 2281701553 SLV_UWB_Status2 4;
BA_ "Description" SG_ 2281701553 SLV_UWB_Status2 "UWB_SLAVE Processing Status 2";
BA_ "Version" SG_ 2281701553 SLV_UWB_Status3 "24.04.04";
BA_ "UserSigValidity" SG_ 2281701553 SLV_UWB_Status3 0;
BA_ "GenSigSendType" SG_ 2281701553 SLV_UWB_Status3 4;
BA_ "Description" SG_ 2281701553 SLV_UWB_Status3 "UWB_SLAVE Processing Status 3";
BA_ "Version" SG_ 2281701553 SLV_UWB_Status4 "24.04.04";
BA_ "UserSigValidity" SG_ 2281701553 SLV_UWB_Status4 0;
BA_ "GenSigSendType" SG_ 2281701553 SLV_UWB_Status4 4;
BA_ "Description" SG_ 2281701553 SLV_UWB_Status4 "UWB_SLAVE Processing Status 4";
BA_ "Version" SG_ 2281701553 SLV_UWB_Status5 "24.04.04";
BA_ "UserSigValidity" SG_ 2281701553 SLV_UWB_Status5 0;
BA_ "GenSigSendType" SG_ 2281701553 SLV_UWB_Status5 4;
BA_ "Description" SG_ 2281701553 SLV_UWB_Status5 "UWB_SLAVE Processing Status 5";
BA_ "Version" SG_ 2281701553 SLV_UWB_Status6 "24.04.04";
BA_ "UserSigValidity" SG_ 2281701553 SLV_UWB_Status6 0;
BA_ "GenSigSendType" SG_ 2281701553 SLV_UWB_Status6 4;
BA_ "Description" SG_ 2281701553 SLV_UWB_Status6 "UWB_SLAVE Processing Status 6";
BA_ "Version" SG_ 2281701553 SLV_UWB_Status7 "24.04.04";
BA_ "UserSigValidity" SG_ 2281701553 SLV_UWB_Status7 0;
BA_ "GenSigSendType" SG_ 2281701553 SLV_UWB_Status7 4;
BA_ "Description" SG_ 2281701553 SLV_UWB_Status7 "UWB_SLAVE Processing Status 7";
BA_ "Version" SG_ 2281701553 SLV_UWB_Status8 "24.04.04";
BA_ "UserSigValidity" SG_ 2281701553 SLV_UWB_Status8 0;
BA_ "GenSigSendType" SG_ 2281701553 SLV_UWB_Status8 4;
BA_ "Description" SG_ 2281701553 SLV_UWB_Status8 "UWB_SLAVE Processing Status 8";
BA_ "Version" SG_ 2281701553 SLV_UWB_Status9 "24.04.04";
BA_ "UserSigValidity" SG_ 2281701553 SLV_UWB_Status9 0;
BA_ "GenSigSendType" SG_ 2281701553 SLV_UWB_Status9 4;
BA_ "Description" SG_ 2281701553 SLV_UWB_Status9 "UWB_SLAVE Processing Status 9";
BA_ "Version" SG_ 2281701553 SLV_UWB_Status10 "24.04.04";
BA_ "UserSigValidity" SG_ 2281701553 SLV_UWB_Status10 0;
BA_ "GenSigSendType" SG_ 2281701553 SLV_UWB_Status10 4;
BA_ "Description" SG_ 2281701553 SLV_UWB_Status10 "UWB_SLAVE Processing Status 10";
BA_ "Version" SG_ 2281701553 SLV_UWB_Status11 "24.04.04";
BA_ "UserSigValidity" SG_ 2281701553 SLV_UWB_Status11 0;
BA_ "GenSigSendType" SG_ 2281701553 SLV_UWB_Status11 4;
BA_ "Description" SG_ 2281701553 SLV_UWB_Status11 "UWB_SLAVE Processing Status 11";
BA_ "Version" SG_ 2281701553 SLV_UWB_Status12 "24.04.04";
BA_ "UserSigValidity" SG_ 2281701553 SLV_UWB_Status12 0;
BA_ "GenSigSendType" SG_ 2281701553 SLV_UWB_Status12 4;
BA_ "Description" SG_ 2281701553 SLV_UWB_Status12 "UWB_SLAVE Processing Status 12";
BA_ "Version" SG_ 2281701553 SLV_UWB_Status13 "24.04.04";
BA_ "UserSigValidity" SG_ 2281701553 SLV_UWB_Status13 0;
BA_ "GenSigSendType" SG_ 2281701553 SLV_UWB_Status13 4;
BA_ "Description" SG_ 2281701553 SLV_UWB_Status13 "UWB_SLAVE Processing Status 13";
BA_ "Version" SG_ 2281701553 SLV_UWB_Status14 "24.04.04";
BA_ "UserSigValidity" SG_ 2281701553 SLV_UWB_Status14 0;
BA_ "GenSigSendType" SG_ 2281701553 SLV_UWB_Status14 4;
BA_ "Description" SG_ 2281701553 SLV_UWB_Status14 "UWB_SLAVE Processing Status 14";
BA_ "Version" SG_ 2281701553 SLV_UWB_Status15 "24.04.04";
BA_ "UserSigValidity" SG_ 2281701553 SLV_UWB_Status15 0;
BA_ "GenSigSendType" SG_ 2281701553 SLV_UWB_Status15 4;
BA_ "Description" SG_ 2281701553 SLV_UWB_Status15 "UWB_SLAVE Processing Status 15";
BA_ "Version" SG_ 2281701553 SLV_UWB_Status16 "24.04.04";
BA_ "UserSigValidity" SG_ 2281701553 SLV_UWB_Status16 0;
BA_ "GenSigSendType" SG_ 2281701553 SLV_UWB_Status16 4;
BA_ "Description" SG_ 2281701553 SLV_UWB_Status16 "UWB_SLAVE Processing Status 16";
BA_ "Version" SG_ 2281701553 SLV_HW_Ver_Major "23.01.02";
BA_ "UserSigValidity" SG_ 2281701553 SLV_HW_Ver_Major 0;
BA_ "GenSigSendType" SG_ 2281701553 SLV_HW_Ver_Major 4;
BA_ "Version" SG_ 2281701553 SLV_HW_Ver_Minor "23.01.02";
BA_ "UserSigValidity" SG_ 2281701553 SLV_HW_Ver_Minor 0;
BA_ "GenSigSendType" SG_ 2281701553 SLV_HW_Ver_Minor 4;
BA_REL_ "GenSigTimeoutTime" BU_SG_REL_ L_UWB_BLE_MST_FD SG_ 849 IAU_DKOwnerSwapOption_Copy_0 1500;
BA_REL_ "GenSigTimeoutTime" BU_SG_REL_ L_UWB_BLE_SLV_FD SG_ 849 IAU_DKOwnerSwapOption_Copy_0 1500;
BA_REL_ "GenSigTimeoutTime" BU_SG_REL_ L_UWB_FL_FD SG_ 849 IAU_DKOwnerSwapOption_Copy_0 1500;
BA_REL_ "GenSigTimeoutTime" BU_SG_REL_ L_UWB_FRNK_FD SG_ 849 IAU_DKOwnerSwapOption_Copy_0 1500;
BA_REL_ "GenSigTimeoutTime" BU_SG_REL_ L_UWB_FR_FD SG_ 849 IAU_DKOwnerSwapOption_Copy_0 1500;
BA_REL_ "GenSigTimeoutTime" BU_SG_REL_ L_UWB_RL_FD SG_ 849 IAU_DKOwnerSwapOption_Copy_0 1500;
BA_REL_ "GenSigTimeoutTime" BU_SG_REL_ L_UWB_RR_FD SG_ 849 IAU_DKOwnerSwapOption_Copy_0 1500;
BA_REL_ "GenSigTimeoutTime" BU_SG_REL_ L_UWB_TRNK_FD SG_ 849 IAU_DKOwnerSwapOption_Copy_0 1500;
BA_REL_ "GenSigTimeoutTime" BU_SG_REL_ L_WPC_FD SG_ 849 IAU_DKOwnerSwapOption_Copy_0 1500;
BA_REL_ "GenSigTimeoutTime" BU_SG_REL_ L_DHL_FD SG_ 849 IAU_DigitalKeyEnblRVal_Copy_0 1500;
BA_REL_ "GenSigTimeoutTime" BU_SG_REL_ L_DHRL_FD SG_ 849 IAU_DigitalKeyEnblRVal_Copy_0 1500;
BA_REL_ "GenSigTimeoutTime" BU_SG_REL_ L_DHRR_FD SG_ 849 IAU_DigitalKeyEnblRVal_Copy_0 1500;
BA_REL_ "GenSigTimeoutTime" BU_SG_REL_ L_DHR_FD SG_ 849 IAU_DigitalKeyEnblRVal_Copy_0 1500;
BA_REL_ "GenSigTimeoutTime" BU_SG_REL_ L_UWB_BLE_MST_FD SG_ 849 IAU_DigitalKeyEnblRVal_Copy_0 1500;
BA_REL_ "GenSigTimeoutTime" BU_SG_REL_ L_UWB_BLE_SLV_FD SG_ 849 IAU_DigitalKeyEnblRVal_Copy_0 1500;
BA_REL_ "GenSigTimeoutTime" BU_SG_REL_ L_UWB_FL_FD SG_ 849 IAU_DigitalKeyEnblRVal_Copy_0 1500;
BA_REL_ "GenSigTimeoutTime" BU_SG_REL_ L_UWB_FRNK_FD SG_ 849 IAU_DigitalKeyEnblRVal_Copy_0 1500;
BA_REL_ "GenSigTimeoutTime" BU_SG_REL_ L_UWB_FR_FD SG_ 849 IAU_DigitalKeyEnblRVal_Copy_0 1500;
BA_REL_ "GenSigTimeoutTime" BU_SG_REL_ L_UWB_RL_FD SG_ 849 IAU_DigitalKeyEnblRVal_Copy_0 1500;
BA_REL_ "GenSigTimeoutTime" BU_SG_REL_ L_UWB_RR_FD SG_ 849 IAU_DigitalKeyEnblRVal_Copy_0 1500;
BA_REL_ "GenSigTimeoutTime" BU_SG_REL_ L_UWB_TRNK_FD SG_ 849 IAU_DigitalKeyEnblRVal_Copy_0 1500;
BA_REL_ "GenSigTimeoutTime" BU_SG_REL_ L_DHL_FD SG_ 849 IAU_OwnerPhnRegRVal_Copy_0 1500;
BA_REL_ "GenSigTimeoutTime" BU_SG_REL_ L_DHRL_FD SG_ 849 IAU_OwnerPhnRegRVal_Copy_0 1500;
BA_REL_ "GenSigTimeoutTime" BU_SG_REL_ L_DHRR_FD SG_ 849 IAU_OwnerPhnRegRVal_Copy_0 1500;
BA_REL_ "GenSigTimeoutTime" BU_SG_REL_ L_DHR_FD SG_ 849 IAU_OwnerPhnRegRVal_Copy_0 1500;
BA_REL_ "GenSigTimeoutTime" BU_SG_REL_ L_UWB_BLE_MST_FD SG_ 849 IAU_OwnerPhnRegRVal_Copy_0 1500;
BA_REL_ "GenSigTimeoutTime" BU_SG_REL_ L_UWB_BLE_SLV_FD SG_ 849 IAU_OwnerPhnRegRVal_Copy_0 1500;
BA_REL_ "GenSigTimeoutTime" BU_SG_REL_ L_UWB_FL_FD SG_ 849 IAU_OwnerPhnRegRVal_Copy_0 1500;
BA_REL_ "GenSigTimeoutTime" BU_SG_REL_ L_UWB_FRNK_FD SG_ 849 IAU_OwnerPhnRegRVal_Copy_0 1500;
BA_REL_ "GenSigTimeoutTime" BU_SG_REL_ L_UWB_FR_FD SG_ 849 IAU_OwnerPhnRegRVal_Copy_0 1500;
BA_REL_ "GenSigTimeoutTime" BU_SG_REL_ L_UWB_RL_FD SG_ 849 IAU_OwnerPhnRegRVal_Copy_0 1500;
BA_REL_ "GenSigTimeoutTime" BU_SG_REL_ L_UWB_RR_FD SG_ 849 IAU_OwnerPhnRegRVal_Copy_0 1500;
BA_REL_ "GenSigTimeoutTime" BU_SG_REL_ L_UWB_TRNK_FD SG_ 849 IAU_OwnerPhnRegRVal_Copy_0 1500;
BA_REL_ "GenSigTimeoutTime" BU_SG_REL_ L_WPC_FD SG_ 849 IAU_OwnerPhnRegRVal_Copy_0 1500;
BA_REL_ "GenSigTimeoutTime" BU_SG_REL_ GW_BDC_FD SG_ 1338 UWB_TRNK_ResetOpsta 5000;
BA_REL_ "GenSigTimeoutTime" BU_SG_REL_ GW_BDC_FD SG_ 2214592800 ROABDC_DataByte0 0;
BA_REL_ "GenSigTimeoutTime" BU_SG_REL_ GW_BDC_FD SG_ 2214592800 ROABDC_DataByte1 0;
BA_REL_ "GenSigTimeoutTime" BU_SG_REL_ GW_BDC_FD SG_ 2214592800 ROABDC_DataByte2 0;
BA_REL_ "GenSigTimeoutTime" BU_SG_REL_ GW_BDC_FD SG_ 2214592800 ROABDC_DataByte3 0;
BA_REL_ "GenSigTimeoutTime" BU_SG_REL_ GW_BDC_FD SG_ 2214592800 ROABDC_DataByte4 0;
BA_REL_ "GenSigTimeoutTime" BU_SG_REL_ GW_BDC_FD SG_ 2214592800 ROABDC_DataByte5 0;
BA_REL_ "GenSigTimeoutTime" BU_SG_REL_ GW_BDC_FD SG_ 2214592800 ROABDC_DataByte6 0;
BA_REL_ "GenSigTimeoutTime" BU_SG_REL_ GW_BDC_FD SG_ 2214592800 ROABDC_DataByte7 0;
BA_REL_ "GenSigTimeoutTime" BU_SG_REL_ GW_BDC_FD SG_ 1340 SAL_ResetOpsta 5000;
BA_REL_ "GenSigTimeoutTime" BU_SG_REL_ L_ROA_FD SG_ 2214592802 ROA_FRBDC_DataByte0 0;
BA_REL_ "GenSigTimeoutTime" BU_SG_REL_ L_ROA_FD SG_ 2214592802 ROA_FRBDC_DataByte1 0;
BA_REL_ "GenSigTimeoutTime" BU_SG_REL_ L_ROA_FD SG_ 2214592802 ROA_FRBDC_DataByte2 0;
BA_REL_ "GenSigTimeoutTime" BU_SG_REL_ L_ROA_FD SG_ 2214592802 ROA_FRBDC_DataByte3 0;
BA_REL_ "GenSigTimeoutTime" BU_SG_REL_ L_ROA_FD SG_ 2214592802 ROA_FRBDC_DataByte4 0;
BA_REL_ "GenSigTimeoutTime" BU_SG_REL_ L_ROA_FD SG_ 2214592802 ROA_FRBDC_DataByte5 0;
BA_REL_ "GenSigTimeoutTime" BU_SG_REL_ L_ROA_FD SG_ 2214592802 ROA_FRBDC_DataByte6 0;
BA_REL_ "GenSigTimeoutTime" BU_SG_REL_ L_ROA_FD SG_ 2214592802 ROA_FRBDC_DataByte7 0;
BA_REL_ "GenSigTimeoutTime" BU_SG_REL_ GW_BDC_FD SG_ 1329 ROA_FR_ResetOpSta_Copy_0 5000;
BA_REL_ "GenSigTimeoutTime" BU_SG_REL_ GW_BDC_FD SG_ 1328 ROA_ResetOpSta_Copy_0 5000;
BA_REL_ "GenSigTimeoutTime" BU_SG_REL_ GW_BDC_FD SG_ 1331 UWB_BLE_MST_ResetOpsta 5000;
BA_REL_ "GenSigTimeoutTime" BU_SG_REL_ GW_BDC_FD SG_ 1331 UWB_BLE_MST_DeviceConnectionChec 5000;
BA_REL_ "GenSigTimeoutTime" BU_SG_REL_ L_DHR_FD SG_ 1813 GST_DHR_Byte0 0;
BA_REL_ "GenSigTimeoutTime" BU_SG_REL_ L_DHR_FD SG_ 1813 GST_DHR_Byte2 0;
BA_REL_ "GenSigTimeoutTime" BU_SG_REL_ L_DHR_FD SG_ 1813 GST_DHR_Byte3 0;
BA_REL_ "GenSigTimeoutTime" BU_SG_REL_ L_DHR_FD SG_ 1813 GST_DHR_Byte4 0;
BA_REL_ "GenSigTimeoutTime" BU_SG_REL_ L_DHR_FD SG_ 1813 GST_DHR_Byte5 0;
BA_REL_ "GenSigTimeoutTime" BU_SG_REL_ L_DHR_FD SG_ 1813 GST_DHR_Byte6 0;
BA_REL_ "GenSigTimeoutTime" BU_SG_REL_ L_DHR_FD SG_ 1813 GST_DHR_Byte7 0;
BA_REL_ "GenSigTimeoutTime" BU_SG_REL_ L_DHR_FD SG_ 1813 GST_DHR_Byte1 0;
BA_REL_ "GenSigTimeoutTime" BU_SG_REL_ GW_BDC_FD SG_ 1330 TPMS_ResetOpsta 5000;
BA_REL_ "GenSigTimeoutTime" BU_SG_REL_ GW_BDC_FD SG_ 1333 UWB_FL_ResetOpsta 5000;
BA_REL_ "GenSigTimeoutTime" BU_SG_REL_ GW_BDC_FD SG_ 1332 UWB_BLE_SLV_ResetOpsta 5000;
BA_REL_ "GenSigTimeoutTime" BU_SG_REL_ GW_BDC_FD SG_ 1332 UWB_BLE_SLV_DeviceConnectionChec 5000;
BA_REL_ "GenSigTimeoutTime" BU_SG_REL_ GW_BDC_FD SG_ 1335 UWB_FRNK_ResetOpsta 5000;
BA_REL_ "GenSigTimeoutTime" BU_SG_REL_ GW_BDC_FD SG_ 2281701488 WPC_Status 1500;
BA_REL_ "GenSigTimeoutTime" BU_SG_REL_ GW_BDC_FD SG_ 2281701488 WPC2_Status 1500;
BA_REL_ "GenSigTimeoutTime" BU_SG_REL_ GW_BDC_FD SG_ 2281701488 WPC_NFC_Opt 1500;
BA_REL_ "GenSigTimeoutTime" BU_SG_REL_ GW_BDC_FD SG_ 1334 UWB_FR_ResetOpsta 5000;
BA_REL_ "GenSigTimeoutTime" BU_SG_REL_ GW_BDC_FD SG_ 1805 MLM_GST_Byte0 0;
BA_REL_ "GenSigTimeoutTime" BU_SG_REL_ GW_BDC_FD SG_ 1805 MLM_GST_Byte2 0;
BA_REL_ "GenSigTimeoutTime" BU_SG_REL_ GW_BDC_FD SG_ 1805 MLM_GST_Byte3 0;
BA_REL_ "GenSigTimeoutTime" BU_SG_REL_ GW_BDC_FD SG_ 1805 MLM_GST_Byte4 0;
BA_REL_ "GenSigTimeoutTime" BU_SG_REL_ GW_BDC_FD SG_ 1805 MLM_GST_Byte5 0;
BA_REL_ "GenSigTimeoutTime" BU_SG_REL_ GW_BDC_FD SG_ 1805 MLM_GST_Byte6 0;
BA_REL_ "GenSigTimeoutTime" BU_SG_REL_ GW_BDC_FD SG_ 1805 MLM_GST_Byte7 0;
BA_REL_ "GenSigTimeoutTime" BU_SG_REL_ GW_BDC_FD SG_ 1805 MLM_GST_Byte1 0;
BA_REL_ "GenSigTimeoutTime" BU_SG_REL_ GW_BDC_FD SG_ 1802 DHL_GST_Byte0 0;
BA_REL_ "GenSigTimeoutTime" BU_SG_REL_ GW_BDC_FD SG_ 1802 DHL_GST_Byte2 0;
BA_REL_ "GenSigTimeoutTime" BU_SG_REL_ GW_BDC_FD SG_ 1802 DHL_GST_Byte3 0;
BA_REL_ "GenSigTimeoutTime" BU_SG_REL_ GW_BDC_FD SG_ 1802 DHL_GST_Byte4 0;
BA_REL_ "GenSigTimeoutTime" BU_SG_REL_ GW_BDC_FD SG_ 1802 DHL_GST_Byte5 0;
BA_REL_ "GenSigTimeoutTime" BU_SG_REL_ GW_BDC_FD SG_ 1802 DHL_GST_Byte6 0;
BA_REL_ "GenSigTimeoutTime" BU_SG_REL_ GW_BDC_FD SG_ 1802 DHL_GST_Byte7 0;
BA_REL_ "GenSigTimeoutTime" BU_SG_REL_ GW_BDC_FD SG_ 1802 DHL_GST_Byte1 0;
BA_REL_ "GenSigTimeoutTime" BU_SG_REL_ L_UWB_BLE_MST_FD SG_ 2521142785 SLV_SWID_2_IVD_2 0;
BA_REL_ "GenSigTimeoutTime" BU_SG_REL_ L_UWB_BLE_MST_FD SG_ 2533739009 FRNK_SWID_4_IVD_1 0;
BA_REL_ "GenSigTimeoutTime" BU_SG_REL_ L_SAL_FD SG_ 1797 GST_MLM_Byte0 0;
BA_REL_ "GenSigTimeoutTime" BU_SG_REL_ L_SAL_FD SG_ 1797 GST_MLM_Byte2 0;
BA_REL_ "GenSigTimeoutTime" BU_SG_REL_ L_SAL_FD SG_ 1797 GST_MLM_Byte3 0;
BA_REL_ "GenSigTimeoutTime" BU_SG_REL_ L_SAL_FD SG_ 1797 GST_MLM_Byte4 0;
BA_REL_ "GenSigTimeoutTime" BU_SG_REL_ L_SAL_FD SG_ 1797 GST_MLM_Byte5 0;
BA_REL_ "GenSigTimeoutTime" BU_SG_REL_ L_SAL_FD SG_ 1797 GST_MLM_Byte6 0;
BA_REL_ "GenSigTimeoutTime" BU_SG_REL_ L_SAL_FD SG_ 1797 GST_MLM_Byte7 0;
BA_REL_ "GenSigTimeoutTime" BU_SG_REL_ L_SAL_FD SG_ 1797 GST_MLM_Byte1 0;
BA_REL_ "GenSigTimeoutTime" BU_SG_REL_ L_UWB_BLE_MST_FD SG_ 2529540609 RR_SWID_4_IVD_1 0;
BA_REL_ "GenSigTimeoutTime" BU_SG_REL_ L_DHL_FD SG_ 1794 GST_DHL_Byte0 0;
BA_REL_ "GenSigTimeoutTime" BU_SG_REL_ L_DHL_FD SG_ 1794 GST_DHL_Byte2 0;
BA_REL_ "GenSigTimeoutTime" BU_SG_REL_ L_DHL_FD SG_ 1794 GST_DHL_Byte3 0;
BA_REL_ "GenSigTimeoutTime" BU_SG_REL_ L_DHL_FD SG_ 1794 GST_DHL_Byte4 0;
BA_REL_ "GenSigTimeoutTime" BU_SG_REL_ L_DHL_FD SG_ 1794 GST_DHL_Byte5 0;
BA_REL_ "GenSigTimeoutTime" BU_SG_REL_ L_DHL_FD SG_ 1794 GST_DHL_Byte6 0;
BA_REL_ "GenSigTimeoutTime" BU_SG_REL_ L_DHL_FD SG_ 1794 GST_DHL_Byte7 0;
BA_REL_ "GenSigTimeoutTime" BU_SG_REL_ L_DHL_FD SG_ 1794 GST_DHL_Byte1 0;
BA_REL_ "GenSigTimeoutTime" BU_SG_REL_ L_ROA_FD SG_ 2281701472 ROA_SnsrRunReq 1500;
BA_REL_ "GenSigTimeoutTime" BU_SG_REL_ L_ROA_FR_FD SG_ 2281701472 ROA_SnsrRunReq 1500;
BA_REL_ "GenSigTimeoutTime" BU_SG_REL_ L_ROA_FD SG_ 2281701472 ROA_DiaReq 1500;
BA_REL_ "GenSigTimeoutTime" BU_SG_REL_ L_ROA_FR_FD SG_ 2281701472 ROA_DiaReq 1500;
BA_REL_ "GenSigTimeoutTime" BU_SG_REL_ L_ROA_FD SG_ 2281701472 ROA_Region_Opt 1500;
BA_REL_ "GenSigTimeoutTime" BU_SG_REL_ L_ROA_FR_FD SG_ 2281701472 ROA_Region_Opt 1500;
BA_REL_ "GenSigTimeoutTime" BU_SG_REL_ L_ROA_FD SG_ 2281701472 ROA_EngSta 1500;
BA_REL_ "GenSigTimeoutTime" BU_SG_REL_ L_ROA_FR_FD SG_ 2281701472 ROA_EngSta 1500;
BA_REL_ "GenSigTimeoutTime" BU_SG_REL_ L_UWB_BLE_MST_FD SG_ 2281701472 ROA_EngSta 1500;
BA_REL_ "GenSigTimeoutTime" BU_SG_REL_ L_UWB_BLE_SLV_FD SG_ 2281701472 ROA_EngSta 1500;
BA_REL_ "GenSigTimeoutTime" BU_SG_REL_ L_ROA_FR_FD SG_ 1494 GST_ROA_FR_Byte0 0;
BA_REL_ "GenSigTimeoutTime" BU_SG_REL_ L_ROA_FR_FD SG_ 1494 GST_ROA_FR_Byte2 0;
BA_REL_ "GenSigTimeoutTime" BU_SG_REL_ L_ROA_FR_FD SG_ 1494 GST_ROA_FR_Byte3 0;
BA_REL_ "GenSigTimeoutTime" BU_SG_REL_ L_ROA_FR_FD SG_ 1494 GST_ROA_FR_Byte4 0;
BA_REL_ "GenSigTimeoutTime" BU_SG_REL_ L_ROA_FR_FD SG_ 1494 GST_ROA_FR_Byte5 0;
BA_REL_ "GenSigTimeoutTime" BU_SG_REL_ L_ROA_FR_FD SG_ 1494 GST_ROA_FR_Byte6 0;
BA_REL_ "GenSigTimeoutTime" BU_SG_REL_ L_ROA_FR_FD SG_ 1494 GST_ROA_FR_Byte7 0;
BA_REL_ "GenSigTimeoutTime" BU_SG_REL_ L_ROA_FR_FD SG_ 1494 GST_ROA_FR_Byte1 0;
BA_REL_ "GenSigTimeoutTime" BU_SG_REL_ GW_BDC_FD SG_ 2281701521 DHRR_Status 1500;
BA_REL_ "GenSigTimeoutTime" BU_SG_REL_ GW_BDC_FD SG_ 2281701521 DHRR_Rain_Sta 1500;
BA_REL_ "GenSigTimeoutTime" BU_SG_REL_ GW_BDC_FD SG_ 2281701521 DHRR_PhnDet_Sta 1500;
BA_REL_ "GenSigTimeoutTime" BU_SG_REL_ GW_BDC_FD SG_ 2281701521 DHRR_TglDet_Sta 1500;
BA_REL_ "GenSigTimeoutTime" BU_SG_REL_ L_UWB_BLE_MST_FD SG_ 2281701521 DHRR_TglDet_Sta 1500;
BA_REL_ "GenSigTimeoutTime" BU_SG_REL_ GW_BDC_FD SG_ 2281701521 DHRR_UnlckDet_Sta 1500;
BA_REL_ "GenSigTimeoutTime" BU_SG_REL_ L_UWB_BLE_MST_FD SG_ 2281701521 DHRR_UnlckDet_Sta 1500;
BA_REL_ "GenSigTimeoutTime" BU_SG_REL_ GW_BDC_FD SG_ 2281701521 DHRR_LckDet_Sta 1500;
BA_REL_ "GenSigTimeoutTime" BU_SG_REL_ L_UWB_BLE_MST_FD SG_ 2281701521 DHRR_LckDet_Sta 1500;
BA_REL_ "GenSigTimeoutTime" BU_SG_REL_ GW_BDC_FD SG_ 2281701521 DHRR_NFCPollingStatus_Dvp 1500;
BA_REL_ "GenSigTimeoutTime" BU_SG_REL_ GW_BDC_FD SG_ 2281701521 DHRR_ResetOpsta 1500;
BA_REL_ "GenSigTimeoutTime" BU_SG_REL_ GW_BDC_FD SG_ 2281701521 DHRR_Diag_Sta 1500;
BA_REL_ "GenSigTimeoutTime" BU_SG_REL_ GW_BDC_FD SG_ 2281701520 DHR_Status 1500;
BA_REL_ "GenSigTimeoutTime" BU_SG_REL_ GW_BDC_FD SG_ 2281701520 DHR_Rain_Sta 1500;
BA_REL_ "GenSigTimeoutTime" BU_SG_REL_ GW_BDC_FD SG_ 2281701520 DHR_PhnDet_Sta 1500;
BA_REL_ "GenSigTimeoutTime" BU_SG_REL_ GW_BDC_FD SG_ 2281701520 DHR_TglDet_Sta 1500;
BA_REL_ "GenSigTimeoutTime" BU_SG_REL_ L_UWB_BLE_MST_FD SG_ 2281701520 DHR_TglDet_Sta 1500;
BA_REL_ "GenSigTimeoutTime" BU_SG_REL_ GW_BDC_FD SG_ 2281701520 DHR_UnlckDet_Sta 1500;
BA_REL_ "GenSigTimeoutTime" BU_SG_REL_ L_UWB_BLE_MST_FD SG_ 2281701520 DHR_UnlckDet_Sta 1500;
BA_REL_ "GenSigTimeoutTime" BU_SG_REL_ GW_BDC_FD SG_ 2281701520 DHR_LckDet_Sta 1500;
BA_REL_ "GenSigTimeoutTime" BU_SG_REL_ L_UWB_BLE_MST_FD SG_ 2281701520 DHR_LckDet_Sta 1500;
BA_REL_ "GenSigTimeoutTime" BU_SG_REL_ GW_BDC_FD SG_ 2281701520 DHR_NFCPollingStatus_Dvp 1500;
BA_REL_ "GenSigTimeoutTime" BU_SG_REL_ GW_BDC_FD SG_ 2281701520 DHR_ResetOpSta 1500;
BA_REL_ "GenSigTimeoutTime" BU_SG_REL_ GW_BDC_FD SG_ 2281701520 DHR_Diag_Sta 1500;
BA_REL_ "GenSigTimeoutTime" BU_SG_REL_ L_UWB_BLE_MST_FD SG_ 2521143297 SLV_SWID_3_IVD_2 0;
BA_REL_ "GenSigTimeoutTime" BU_SG_REL_ GW_BDC_FD SG_ 1502 ROA_FR_GST_Byte0 0;
BA_REL_ "GenSigTimeoutTime" BU_SG_REL_ GW_BDC_FD SG_ 1502 ROA_FR_GST_Byte2 0;
BA_REL_ "GenSigTimeoutTime" BU_SG_REL_ GW_BDC_FD SG_ 1502 ROA_FR_GST_Byte3 0;
BA_REL_ "GenSigTimeoutTime" BU_SG_REL_ GW_BDC_FD SG_ 1502 ROA_FR_GST_Byte4 0;
BA_REL_ "GenSigTimeoutTime" BU_SG_REL_ GW_BDC_FD SG_ 1502 ROA_FR_GST_Byte5 0;
BA_REL_ "GenSigTimeoutTime" BU_SG_REL_ GW_BDC_FD SG_ 1502 ROA_FR_GST_Byte6 0;
BA_REL_ "GenSigTimeoutTime" BU_SG_REL_ GW_BDC_FD SG_ 1502 ROA_FR_GST_Byte7 0;
BA_REL_ "GenSigTimeoutTime" BU_SG_REL_ GW_BDC_FD SG_ 1502 ROA_FR_GST_Byte1 0;
BA_REL_ "GenSigTimeoutTime" BU_SG_REL_ GW_BDC_FD SG_ 2281701504 DHL_Status 1500;
BA_REL_ "GenSigTimeoutTime" BU_SG_REL_ GW_BDC_FD SG_ 2281701504 DHL_Rain_Sta 1500;
BA_REL_ "GenSigTimeoutTime" BU_SG_REL_ GW_BDC_FD SG_ 2281701504 DHL_PhnDet_Sta 1500;
BA_REL_ "GenSigTimeoutTime" BU_SG_REL_ GW_BDC_FD SG_ 2281701504 DHL_TglDet_Sta 1500;
BA_REL_ "GenSigTimeoutTime" BU_SG_REL_ L_UWB_BLE_MST_FD SG_ 2281701504 DHL_TglDet_Sta 1500;
BA_REL_ "GenSigTimeoutTime" BU_SG_REL_ GW_BDC_FD SG_ 2281701504 DHL_UnlckDet_Sta 1500;
BA_REL_ "GenSigTimeoutTime" BU_SG_REL_ L_UWB_BLE_MST_FD SG_ 2281701504 DHL_UnlckDet_Sta 1500;
BA_REL_ "GenSigTimeoutTime" BU_SG_REL_ GW_BDC_FD SG_ 2281701504 DHL_LckDet_Sta 1500;
BA_REL_ "GenSigTimeoutTime" BU_SG_REL_ L_UWB_BLE_MST_FD SG_ 2281701504 DHL_LckDet_Sta 1500;
BA_REL_ "GenSigTimeoutTime" BU_SG_REL_ GW_BDC_FD SG_ 2281701504 DHL_NFCPollingStatus_Dvp 1500;
BA_REL_ "GenSigTimeoutTime" BU_SG_REL_ GW_BDC_FD SG_ 2281701504 DHL_ResetOpsta 1500;
BA_REL_ "GenSigTimeoutTime" BU_SG_REL_ GW_BDC_FD SG_ 2281701504 DHL_Diag_Sta 1500;
BA_REL_ "GenSigTimeoutTime" BU_SG_REL_ GW_BDC_FD SG_ 2281701505 DHRL_Status 1500;
BA_REL_ "GenSigTimeoutTime" BU_SG_REL_ GW_BDC_FD SG_ 2281701505 DHRL_Rain_Sta 1500;
BA_REL_ "GenSigTimeoutTime" BU_SG_REL_ GW_BDC_FD SG_ 2281701505 DHRL_PhnDet_Sta 1500;
BA_REL_ "GenSigTimeoutTime" BU_SG_REL_ GW_BDC_FD SG_ 2281701505 DHRL_TglDet_Sta 1500;
BA_REL_ "GenSigTimeoutTime" BU_SG_REL_ L_UWB_BLE_MST_FD SG_ 2281701505 DHRL_TglDet_Sta 1500;
BA_REL_ "GenSigTimeoutTime" BU_SG_REL_ GW_BDC_FD SG_ 2281701505 DHRL_UnlckDet_Sta 1500;
BA_REL_ "GenSigTimeoutTime" BU_SG_REL_ L_UWB_BLE_MST_FD SG_ 2281701505 DHRL_UnlckDet_Sta 1500;
BA_REL_ "GenSigTimeoutTime" BU_SG_REL_ GW_BDC_FD SG_ 2281701505 DHRL_LckDet_Sta 1500;
BA_REL_ "GenSigTimeoutTime" BU_SG_REL_ L_UWB_BLE_MST_FD SG_ 2281701505 DHRL_LckDet_Sta 1500;
BA_REL_ "GenSigTimeoutTime" BU_SG_REL_ GW_BDC_FD SG_ 2281701505 DHRL_NFCPollingStatus_Dvp 1500;
BA_REL_ "GenSigTimeoutTime" BU_SG_REL_ GW_BDC_FD SG_ 2281701505 DHRL_ResetOpSta 1500;
BA_REL_ "GenSigTimeoutTime" BU_SG_REL_ GW_BDC_FD SG_ 2281701505 DHRL_Diag_Sta 1500;
BA_REL_ "GenSigTimeoutTime" BU_SG_REL_ L_UWB_BLE_MST_FD SG_ 2525340417 FL_SWID_4_IVD_2 0;
BA_REL_ "GenSigTimeoutTime" BU_SG_REL_ L_UWB_BLE_MST_FD SG_ 2521143809 SLV_SWID_4_IVD_2 0;
BA_REL_ "GenSigTimeoutTime" BU_SG_REL_ L_UWB_BLE_MST_FD SG_ 2281701553 SLV_SW_MCU_Ver_Major 1500;
BA_REL_ "GenSigTimeoutTime" BU_SG_REL_ L_UWB_BLE_MST_FD SG_ 2281701553 SLV_SW_MCU_Ver_Minor 1500;
BA_REL_ "GenSigTimeoutTime" BU_SG_REL_ L_UWB_BLE_MST_FD SG_ 2281701553 SLV_SW_UWB_Ver_Major 1500;
BA_REL_ "GenSigTimeoutTime" BU_SG_REL_ L_UWB_BLE_MST_FD SG_ 2281701553 SLV_SW_UWB_Ver_Minor 1500;
BA_REL_ "GenSigTimeoutTime" BU_SG_REL_ L_UWB_BLE_MST_FD SG_ 2281701553 SLV_SW_BLE_Ver_Major 1500;
BA_REL_ "GenSigTimeoutTime" BU_SG_REL_ L_UWB_BLE_MST_FD SG_ 2281701553 SLV_SW_BLE_Ver_Minor 1500;
BA_REL_ "GenSigTimeoutTime" BU_SG_REL_ L_UWB_BLE_MST_FD SG_ 2281701553 SLV_DTC 1500;
BA_REL_ "GenSigTimeoutTime" BU_SG_REL_ L_UWB_BLE_MST_FD SG_ 2281701553 SLV_DTC_BLE 1500;
BA_REL_ "GenSigTimeoutTime" BU_SG_REL_ GW_BDC_FD SG_ 2281701553 SLV_UWB_Status1 1500;
BA_REL_ "GenSigTimeoutTime" BU_SG_REL_ L_UWB_BLE_MST_FD SG_ 2281701553 SLV_UWB_Status1 1500;
BA_REL_ "GenSigTimeoutTime" BU_SG_REL_ GW_BDC_FD SG_ 2281701553 SLV_UWB_Status2 1500;
BA_REL_ "GenSigTimeoutTime" BU_SG_REL_ L_UWB_BLE_MST_FD SG_ 2281701553 SLV_UWB_Status2 1500;
BA_REL_ "GenSigTimeoutTime" BU_SG_REL_ GW_BDC_FD SG_ 2281701553 SLV_UWB_Status3 1500;
BA_REL_ "GenSigTimeoutTime" BU_SG_REL_ L_UWB_BLE_MST_FD SG_ 2281701553 SLV_UWB_Status3 1500;
BA_REL_ "GenSigTimeoutTime" BU_SG_REL_ GW_BDC_FD SG_ 2281701553 SLV_UWB_Status4 1500;
BA_REL_ "GenSigTimeoutTime" BU_SG_REL_ L_UWB_BLE_MST_FD SG_ 2281701553 SLV_UWB_Status4 1500;
BA_REL_ "GenSigTimeoutTime" BU_SG_REL_ GW_BDC_FD SG_ 2281701553 SLV_UWB_Status5 1500;
BA_REL_ "GenSigTimeoutTime" BU_SG_REL_ L_UWB_BLE_MST_FD SG_ 2281701553 SLV_UWB_Status5 1500;
BA_REL_ "GenSigTimeoutTime" BU_SG_REL_ GW_BDC_FD SG_ 2281701553 SLV_UWB_Status6 1500;
BA_REL_ "GenSigTimeoutTime" BU_SG_REL_ L_UWB_BLE_MST_FD SG_ 2281701553 SLV_UWB_Status6 1500;
BA_REL_ "GenSigTimeoutTime" BU_SG_REL_ GW_BDC_FD SG_ 2281701553 SLV_UWB_Status7 1500;
BA_REL_ "GenSigTimeoutTime" BU_SG_REL_ L_UWB_BLE_MST_FD SG_ 2281701553 SLV_UWB_Status7 1500;
BA_REL_ "GenSigTimeoutTime" BU_SG_REL_ GW_BDC_FD SG_ 2281701553 SLV_UWB_Status8 1500;
BA_REL_ "GenSigTimeoutTime" BU_SG_REL_ L_UWB_BLE_MST_FD SG_ 2281701553 SLV_UWB_Status8 1500;
BA_REL_ "GenSigTimeoutTime" BU_SG_REL_ GW_BDC_FD SG_ 2281701553 SLV_UWB_Status9 1500;
BA_REL_ "GenSigTimeoutTime" BU_SG_REL_ L_UWB_BLE_MST_FD SG_ 2281701553 SLV_UWB_Status9 1500;
BA_REL_ "GenSigTimeoutTime" BU_SG_REL_ GW_BDC_FD SG_ 2281701553 SLV_UWB_Status10 1500;
BA_REL_ "GenSigTimeoutTime" BU_SG_REL_ L_UWB_BLE_MST_FD SG_ 2281701553 SLV_UWB_Status10 1500;
BA_REL_ "GenSigTimeoutTime" BU_SG_REL_ GW_BDC_FD SG_ 2281701553 SLV_UWB_Status11 1500;
BA_REL_ "GenSigTimeoutTime" BU_SG_REL_ L_UWB_BLE_MST_FD SG_ 2281701553 SLV_UWB_Status11 1500;
BA_REL_ "GenSigTimeoutTime" BU_SG_REL_ GW_BDC_FD SG_ 2281701553 SLV_UWB_Status12 1500;
BA_REL_ "GenSigTimeoutTime" BU_SG_REL_ L_UWB_BLE_MST_FD SG_ 2281701553 SLV_UWB_Status12 1500;
BA_REL_ "GenSigTimeoutTime" BU_SG_REL_ GW_BDC_FD SG_ 2281701553 SLV_UWB_Status13 1500;
BA_REL_ "GenSigTimeoutTime" BU_SG_REL_ L_UWB_BLE_MST_FD SG_ 2281701553 SLV_UWB_Status13 1500;
BA_REL_ "GenSigTimeoutTime" BU_SG_REL_ GW_BDC_FD SG_ 2281701553 SLV_UWB_Status14 1500;
BA_REL_ "GenSigTimeoutTime" BU_SG_REL_ L_UWB_BLE_MST_FD SG_ 2281701553 SLV_UWB_Status14 1500;
BA_REL_ "GenSigTimeoutTime" BU_SG_REL_ GW_BDC_FD SG_ 2281701553 SLV_UWB_Status15 1500;
BA_REL_ "GenSigTimeoutTime" BU_SG_REL_ L_UWB_BLE_MST_FD SG_ 2281701553 SLV_UWB_Status15 1500;
BA_REL_ "GenSigTimeoutTime" BU_SG_REL_ GW_BDC_FD SG_ 2281701553 SLV_UWB_Status16 1500;
BA_REL_ "GenSigTimeoutTime" BU_SG_REL_ L_UWB_BLE_MST_FD SG_ 2281701553 SLV_UWB_Status16 1500;
BA_REL_ "GenSigTimeoutTime" BU_SG_REL_ L_UWB_BLE_MST_FD SG_ 2281701553 SLV_HW_Ver_Major 1500;
BA_REL_ "GenSigTimeoutTime" BU_SG_REL_ L_UWB_BLE_MST_FD SG_ 2281701553 SLV_HW_Ver_Minor 1500;
VAL_ 849 IAU_FD_Crc4Val 0 "0x0x0~0xFFFF:CRCValue" 65535 "0x0x0~0xFFFF:CRCValue" ;
VAL_ 849 IAU_DISPWrng_Copy_0 0 "None" 1 "Auth_Fail2 (DigitalKey)" 2 "ReAuth_Warning" 3 "IAU Error" 4 "DigitalKey Saved" 5 "Auth_Fail2 (FP)" 6 "Auth_Fail2 (DigitalKey or FP)" 7 "BiometricKey Saved" 8 "DigitalKey and BiometricKey Saved" 9 "WPCNFC_PreStartAuth_Success" 10 "Reserved" 11 "Reserved" 12 "Reserved" 13 "Reserved" 14 "ReAuth_forRSPA" 15 "Invalid" ;
VAL_ 849 IAU_DigitalKey2Opt_Copy_0 0 "Default (Not applied)" 1 "Digital Key Light (NFC)" 2 "Digital Key Medium (NFC/BLE)" 3 "Digital Key Full (NFC/BLE/UWB)" 4 "Reserved" 5 "Reserved" 6 "Reserved" 7 "invalid" ;
VAL_ 849 IAUwFRULearnState_Copy_0 0 "Default (Normal)" 1 "Learning" 2 "Neutralizing" 3 "Invalid" ;
VAL_ 849 IAUwFPMLearnState_Copy_0 0 "Default(Normal)" 1 "Learning" 2 "Neutralizing" 3 "Invalid" ;
VAL_ 849 IAU_ValetDigitalkey_Copy_0 0 "Default" 1 "Valet Digitalkey" 2 "Resereved" 3 "invalid" ;
VAL_ 849 IAU_DigitalKeyNumberOpt_Copy_0 0 "Max8" 1 "Max16" 2 "Max16 with Grouping" 3 "RESERVED" 4 "RESERVED" 5 "RESERVED" 6 "RESERVED" 7 "Invalid" ;
VAL_ 849 IAU_eSEReprogramSta_Copy_0 0 "Default" 1 "Updating" 2 "RESERVED" 3 "Invalid" ;
VAL_ 849 IAU_DKOwnerSwapOption_Copy_0 0 "Default" 1 "Not applied" 2 "Applied" 3 "Invalid" ;
VAL_ 849 IAU_DgtKeyGrpPrflRval2_Copy_0 0 "Default" 1 "Group index 0x0" 2 "Group index 0x1" 3 "Group index 0x2" 4 "Group index 0x3" 5 "Group index 0x4" 6 "Group index 0x5" 7 "Group index 0x6" 8 "Group index 0x7" 9 "Group index 0x8" 10 "Group index 0x9" 11 "Group index 0xA" 12 "Group index 0xB" 13 "Group index 0xC" 14 "Group index 0xD" 15 "Group index 0xE" 16 "Group index 0xF" 17 "RESERVED" 18 "RESERVED" 19 "RESERVED" 20 "RESERVED" 21 "RESERVED" 22 "RESERVED" 23 "RESERVED" 24 "RESERVED" 25 "RESERVED" 26 "RESERVED" 27 "RESERVED" 28 "RESERVED" 29 "RESERVED" 30 "RESERVED" 31 "Invalid" ;
VAL_ 849 IAU_StartIdentifiedProfile_Copy_ 0 "Default" 1 "Profile 1" 2 "Profile 2" 3 "Reserved" 4 "Reserved" 5 "Reserved" 6 "Reserved" 7 "Invalid" ;
VAL_ 849 IAU_DigitalKeyProfileRval2_Copy_ 0 "Default" 1 "1st digital key (owner)" 2 "2nd digital key" 3 "3rd digital key" 4 "4th digital key" 5 "5th digital key" 6 "6th digital key" 7 "7th digital key" 8 "8th digital key" 9 "9th digital key" 10 "10th digital key" 11 "11th digital key" 12 "12th digital key" 13 "13th digital key" 14 "14th digital key" 15 "15th digital key" 16 "16th digital key" 17 "reserved" 18 "reserved" 19 "reserved" 20 "reserved" 21 "reserved" 22 "reserved" 23 "reserved" 24 "reserved" 25 "reserved" 26 "reserved" 27 "reserved" 28 "reserved" 29 "reserved" 30 "reserved" 31 "Invalid" ;
VAL_ 849 IAU_NFCCard1SN_Copy_0 0 "0x0x00000000~0xFFFFFFFF:" 2147483647 "0x0x00000000~0xFFFFFFFF:" ;
VAL_ 849 IAU_FD_AlvCnt4Val 0 "0x0x0~0xFF:AlvCntValue" 255 "0x0x0~0xFF:AlvCntValue" ;
VAL_ 849 IAU_StartIdentifiedProfile_Ext 0 "Default" 1 "Profile1" 2 "Profile2" 3 "Profile3" 4 "Profile4" 5 "Profile5" 6 "Profile6" 7 "Profile7" 8 "Profile8" 9 "Profile9" 10 "RESERVED" 11 "RESERVED" 12 "RESERVED" 13 "RESERVED" 14 "RESERVED" 15 "INVALID" ;
VAL_ 849 RSPA_UWBRspaExtRngSta_Copy_0 0 "Initial" 1 "Out of range of RSPA remote control Region" 2 "In the range of RSPA remote control region" 3 "Reserved" ;
VAL_ 849 RSPA_CanFltSta_Copy_0 0 "Default" 1 "RSPA CAN Error" 2 "Not Used" 3 "Error Indicator" ;
VAL_ 849 RSPA_BLESigErrSta_Copy_0 0 "Default" 1 "Signal Invalid" 2 "In Progress" 3 "Error Indicator" ;
VAL_ 849 RSPA_ConStat_Copy_0 0 "Normal Status" 1 "Fail Status" 2 "Reserved" 3 "Reserved" ;
VAL_ 849 IAU_ProfileIDRVal_Copy_0 0 "Default" 1 "Guest" 2 "Profile1" 3 "Profile2" 4 "Profile3" 5 "Profile4" 6 "Profile5" 7 "Profile6" 8 "Profile7" 9 "Profile8" 10 "Profile9" 11 "RESERVED" 12 "RESERVED" 13 "RESERVED" 14 "RESERVED" 15 "INVALID" ;
VAL_ 849 IAU_DigitalKeyProcessingSta_Copy 0 "None" 1 "DeviceOnWPC" 2 "DeviceRegistering" 3 "PhoneRegistered" 4 "All Phone Key Deleted" 5 "NFCCard1Registered" 6 "Server Registering" 7 "NFCCard1Deleted" 8 "BLE Searching" 9 "Owner Phone key Deleted" 10 "Valet Off Searching" 11 "Server Registering Fail" 12 "All Digital Keys in group Deleted" 15 "Invalid" ;
VAL_ 849 IAU_DigitalKeyExit_Copy_0 0 "Normal" 1 "Check System" 2 "NFC Not Detected" 3 "Fob Not Detected" 4 "Canceled by User (Timeout)" 5 "Device not Available" 6 "ProcessFail" 7 "Check Card Save" 8 "Certificate Update" 9 "Valet Off Fail" 10 "CardNotAvailable" 11 "DigitalKeyDisabled" 12 "Retry After Parking" 13 "Check Password" 14 "P position fail (not P)" 15 "Invalid" ;
VAL_ 849 IAU_DigitalKeyEnblRVal_Copy_0 0 "Default" 1 "Disable" 2 "Enable" 3 "Invalid" ;
VAL_ 849 IAU_OwnerPhnRegRVal_Copy_0 0 "Default" 1 "Disable" 2 "Enable" 3 "Invalid" ;
VAL_ 849 IAU_NFCCard1RegRVal_Copy_0 0 "Default" 1 "Disable" 2 "Enable" 3 "Invalid" ;
VAL_ 849 IAU_NFCCard2RegRVal_Copy_0 0 "Default" 1 "Disable" 2 "Enable" 3 "Invalid" ;
VAL_ 1338 UWB_TRNK_FD_Crc30Val 0 "0x0x0~0xFFFF:CRCValue" 65535 "0x0x0~0xFFFF:CRCValue" ;
VAL_ 1338 UWB_TRNK_FD_AlvCnt30Val 0 "0x0x0~0xFF:AlvCntValue" 255 "0x0x0~0xFF:AlvCntValue" ;
VAL_ 1338 UWB_TRNK_ResetOpsta 0 "Normal" 1 "Reset Complete" 2 "Reset Fail" 3 "RESERVED" ;
VAL_ 2214592800 L_ROA_FD_Crc2Val 0 "0x0x0~0xFFFF:CRCValue" 65535 "0x0x0~0xFFFF:CRCValue" ;
VAL_ 2214592800 L_ROA_FD_AlvCnt2Val 0 "0x0x0~0xFF:AlvCntValue" 255 "0x0x0~0xFF:AlvCntValue" ;
VAL_ 1340 SAL_ResetOpsta 0 "Normal" 1 "Reset Complete" 2 "Reset Fail" 3 "RESERVED" ;
VAL_ 2214592802 L_ROA_FR_FD_Crc2Val 0 "0x0x0~0xFFFF:CRCValue" 65535 "0x0x0~0xFFFF:CRCValue" ;
VAL_ 2214592802 L_ROA_FR_FD_AlvCnt2Val 0 "0x0x0~0xFF:AlvCntValue" 255 "0x0x0~0xFF:AlvCntValue" ;
VAL_ 1329 ROA_FR_ResetOpSta_Copy_0 0 "Normal" 1 "Reset Complete" 2 "Reset Fail" 3 "RESERVED" ;
VAL_ 1328 ROA_ResetOpSta_Copy_0 0 "Normal" 1 "Reset Complete" 2 "Reset Fail" 3 "RESERVED" ;
VAL_ 1331 UWB_BLE_MST_FD_Crc30Val 0 "0x0x0~0xFFFF:CRCValue" 65535 "0x0x0~0xFFFF:CRCValue" ;
VAL_ 1331 UWB_BLE_MST_FD_AlvCnt30Val 0 "0x0x0~0xFF:AlvCntValue" 255 "0x0x0~0xFF:AlvCntValue" ;
VAL_ 1331 UWB_BLE_MST_ResetOpsta 0 "Normal" 1 "Reset Complete" 2 "Reset Fail" 3 "RESERVED" ;
VAL_ 1331 UWB_BLE_MST_DeviceConnectionChec 0 "Default" 1 "Connected" 2 "Not Connected" 3 "RESERVED" ;
VAL_ 1330 TPMS_FD_Crc3Val 0 "0x0x0~0xFFFF:CRCValue" 65535 "0x0x0~0xFFFF:CRCValue" ;
VAL_ 1330 TPMS_FD_AlvCnt3Val 0 "0x0x0~0xFF:AlvCntValue" 255 "0x0x0~0xFF:AlvCntValue" ;
VAL_ 1330 TPMS_ResetOpsta 0 "Normal" 1 "Reset Complete" 2 "Reset Fail" 3 "RESERVED" ;
VAL_ 1333 UWB_FL_FD_Crc30Val 0 "0x0x0~0xFFFF:CRCValue" 65535 "0x0x0~0xFFFF:CRCValue" ;
VAL_ 1333 UWB_FL_FD_AlvCnt30Val 0 "0x0x0~0xFF:AlvCntValue" 255 "0x0x0~0xFF:AlvCntValue" ;
VAL_ 1333 UWB_FL_ResetOpsta 0 "Normal" 1 "Reset Complete" 2 "Reset Fail" 3 "RESERVED" ;
VAL_ 1332 UWB_BLE_SLV_FD_Crc30Val 0 "0x0x0~0xFFFF:CRCValue" 65535 "0x0x0~0xFFFF:CRCValue" ;
VAL_ 1332 UWB_BLE_SLV_FD_AlvCnt30Val 0 "0x0x0~0xFF:AlvCntValue" 255 "0x0x0~0xFF:AlvCntValue" ;
VAL_ 1332 UWB_BLE_SLV_ResetOpsta 0 "Normal" 1 "Reset Complete" 2 "Reset Fail" 3 "RESERVED" ;
VAL_ 1332 UWB_BLE_SLV_DeviceConnectionChec 0 "Default" 1 "Connected" 2 "Not Connected" 3 "RESERVED" ;
VAL_ 1335 UWB_FRNK_FD_Crc30Val 0 "0x0x0~0xFFFF:CRCValue" 65535 "0x0x0~0xFFFF:CRCValue" ;
VAL_ 1335 UWB_FRNK_FD_AlvCnt30Val 0 "0x0x0~0xFF:AlvCntValue" 255 "0x0x0~0xFF:AlvCntValue" ;
VAL_ 1335 UWB_FRNK_ResetOpsta 0 "Normal" 1 "Reset Complete" 2 "Reset Fail" 3 "RESERVED" ;
VAL_ 2281701488 L_WPC_FD_Crc20Val 0 "0x0x0~0xFFFF:CRCValue" 65535 "0x0x0~0xFFFF:CRCValue" ;
VAL_ 2281701488 L_WPC_FD_AlvCnt20Val 0 "0x0x0~0xFF:AlvCntValue" 255 "0x0x0~0xFF:AlvCntValue" ;
VAL_ 2281701488 WPC_Status 0 "Off" 1 "WPC Mode" 2 "NFC Scanning" 3 "NFC Communicating" 4 "LPCD Mode" 5 "PICC Detected" 6 "RESERVED" 7 "invalid" ;
VAL_ 2281701488 WPC2_Status 0 "Off" 1 "WPC Mode" 2 "NFC Scanning" 3 "NFC Communicating" 4 "LPCD Mode" 5 "PICC Detected" 6 "RESERVED" 7 "invalid" ;
VAL_ 2281701488 WPC_NFC_Opt 0 "Default(NotApplied)" 1 "Applied" 2 "RESERVED" 3 "invalid" ;
VAL_ 1334 UWB_FR_FD_Crc30Val 0 "0x0x0~0xFFFF:CRCValue" 65535 "0x0x0~0xFFFF:CRCValue" ;
VAL_ 1334 UWB_FR_FD_AlvCnt30Val 0 "0x0x0~0xFF:AlvCntValue" 255 "0x0x0~0xFF:AlvCntValue" ;
VAL_ 1334 UWB_FR_ResetOpsta 0 "Normal" 1 "Reset Complete" 2 "Reset Fail" 3 "RESERVED" ;
VAL_ 2521142785 L_UWB_BLE_SLV_FD_Crc10Val 0 "0x0x0~0xFFFF:CRCValue" 65535 "0x0x0~0xFFFF:CRCValue" ;
VAL_ 2521142785 L_UWB_BLE_SLV_FD_AlvCnt10Val 0 "0x0x0~0xFF:AlvCntValue" 255 "0x0x0~0xFF:AlvCntValue" ;
VAL_ 2533739009 L_UWB_FRNK_FD_Crc6Val 0 "0x0x0~0xFFFF:CRCValue" 65535 "0x0x0~0xFFFF:CRCValue" ;
VAL_ 2533739009 L_UWB_FRNK_FD_AlvCnt6Val 0 "0x0x0~0xFF:AlvCntValue" 255 "0x0x0~0xFF:AlvCntValue" ;
VAL_ 2529540609 L_UWB_RR_FD_Crc6Val 0 "0x0x0~0xFFFF:CRCValue" 65535 "0x0x0~0xFFFF:CRCValue" ;
VAL_ 2529540609 L_UWB_RR_FD_AlvCnt6Val 0 "0x0x0~0xFF:AlvCntValue" 255 "0x0x0~0xFF:AlvCntValue" ;
VAL_ 362 ADAS_PRK_Crc3Val 0 "0x0x0~0xFFFF:CRCValue" 65535 "0x0x0~0xFFFF:CRCValue" ;
VAL_ 362 RSPA_Var 0 "init" 1 "RSPA (ENTRY)" 2 "RSPA" 3 "RSPA 2" 4 "RSPA 3" 5 "RESERVED" 6 "RESERVED" 7 "RESERVED" 8 "RESERVED" 9 "RESERVED" 10 "RESERVED" 11 "RESERVED" 12 "RESERVED" 13 "RESERVED" 14 "RESERVED" 15 "Invalid" ;
VAL_ 362 MRA_FuncEquipSta 0 "Init" 1 "MRA" 2 "RESERVED" 3 "RESERVED" 4 "RESERVED" 5 "RESERVED" 6 "RESERVED" 7 "RESERVED" 8 "RESERVED" 9 "RESERVED" 10 "RESERVED" 11 "RESERVED" 12 "RESERVED" 13 "RESERVED" 14 "RESERVED" 15 "Invalid" ;
VAL_ 362 RSPA_Sta 0 "RSPA not recognized" 1 "Init" 2 "New Start" 3 "Ready OK" 4 "Assist Req" 5 "Assist OK" 6 "Assist Fail" 7 "Abort" 8 "Ready Fail" ;
VAL_ 362 RSPA_Actv 0 "RSPA Off" 1 "RSPA On" 2 "Reserved" 3 "Reserved" ;
VAL_ 362 RSPA_EntryFuncBtnDispSta 0 "Init" 1 "Remote Forward or Backward Disable Button display" 2 "Remote Forward or Backward Enable Button display" 3 "Invalid" ;
VAL_ 362 RSPA_TrgtGearSta 0 "Idle" 1 "P" 2 "R" 3 "N" 4 "D" ;
VAL_ 362 RSPA_EpbReq 0 "No request" 1 "release request" 2 "normal apply" ;
VAL_ 362 RSPA_ExtLampReq 0 "Inactive (No Request)" 1 "Hazard Lamp Active On" 2 "Hazard Lamp Active Off" 3 "Left Turn Signal On" 4 "Right Turn Signal On" 5 "reserved" 6 "reserved" 7 "reserved" ;
VAL_ 362 RSPA_CrankingReq 0 "Init" 1 "to RSPA Remote Cranking" 2 "to Normal Cranking" 3 "to IG OFF" ;
VAL_ 362 RSPA_IdOutWarnReq 0 "No Request" 1 "Change Request" 2 "Not Used" 3 "Error Indicator" ;
VAL_ 362 RSPA_IndBlnkReq 0 "No request" 1 "Green LED Blinking (1Hz)_[Ranging start]" 2 "Red LED Blinking (1Hz)_[Ranging stop]" 3 "Red LED illuminating (4sec)_[Ranging stop]" 4 "Green LED illuminating (4sec)_[Ranging stop]" 5 "RESERVED" 6 "RESERVED" 7 "RESERVED" ;
VAL_ 362 RSPA_SysOff 0 "default" 1 "system off" ;
VAL_ 362 RSPA_DccCmd 0 "No request" 1 "Soft Brake" 2 "Hard 1 Brake" 3 "Hard 2 Brake" ;
VAL_ 362 RSPA_StopReq 0 "No request" 1 "Stop control is required" 2 "Not Used" 3 "Error Indicator" ;
VAL_ 362 RSPA_SelDevInfo 0 "default" 1 "SmartPhone" 2 "Fob" 3 "Reserved" ;
VAL_ 362 RSPA_SelFuncSta 0 "default" 1 "Parking" 2 "Remote Forward or Backward" 3 "RESERVED" ;
VAL_ 362 ADAS_PRK_AlvCnt3Val 0 "0x0x0~0xFF:AlvCntValue" 255 "0x0x0~0xFF:AlvCntValue" ;
VAL_ 362 RSPA_AddtnlAccelActv 0 "Inactive" 1 "Active" 2 "Not Used" 3 "Error Indicator" ;
VAL_ 362 RSPA_Opt 0 "RSPA not applied" 1 "RSPA applied" 2 "Not Used" 3 "Error Indicator" ;
VAL_ 362 RSPA_UppLtTypDis 0 "init" 1 "Not found" 2 "Reverse perpendicular" 3 "Reverse parallel" 4 "Reverse diagonal" 5 "Forward diagonal" 6 "Forward or Reverse perpendicular" 7 "Invalid" ;
VAL_ 362 RSPA_LwrLtTypDis 0 "init" 1 "Not found" 2 "Reverse perpendicular" 3 "Reverse parallel" 4 "Reverse diagonal" 5 "Forward diagonal" 6 "Forward or Reverse perpendicular" 7 "Invalid" ;
VAL_ 362 RSPA_UppRtTypDis 0 "init" 1 "Not found" 2 "Reverse perpendicular" 3 "Reverse parallel" 4 "Reverse diagonal" 5 "Forward diagonal" 6 "Forward or Reverse perpendicular" 7 "Invalid" ;
VAL_ 362 RSPA_LwrRtTypDis 0 "init" 1 "Not found" 2 "Reverse perpendicular" 3 "Reverse parallel" 4 "Reverse diagonal" 5 "Forward diagonal" 6 "Forward or Reverse perpendicular" 7 "Invalid" ;
VAL_ 362 MRA_BtnDispSta 0 "Init" 1 "Check MRA" 2 "Disable Button display" 3 "Enable Button display" 4 "RESERVED" 5 "RESERVED" 6 "RESERVED" 7 "RESERVED" 8 "RESERVED" 9 "RESERVED" 10 "RESERVED" 11 "RESERVED" 12 "RESERVED" 13 "RESERVED" 14 "RESERVED" 5 "Invalid" ;
VAL_ 362 RSPA_AvnDis 0 "init" 1 "No display" 2 "RSPA ╚н╕щ ├т╖┬" 3 "invalid" ;
VAL_ 362 RSPA_HdLmpReq 0 "Initial (Inactive)" 1 "HeadLamp On" 2 "Not Used" 3 "Error Indicator" ;
VAL_ 362 MRA_CamDispSta 0 "No Display" 1 "View OFF" 2 "MRA Assist View ('FW View' and 'Top View + Path')" 3 "MRA Assist View ('RW View + Path' and 'Top View + Path')" 4 "RESERVED" 5 "RESERVED" 6 "RESERVED" 7 "Invalid" ;
VAL_ 362 RSPA_BtnDispSta 0 "Init" 1 "Check RSPA" 2 "Disable Button display" 3 "Enable Button display" 4 "RESERVED" 5 "RESERVED" 6 "RESERVED" 7 "Invalid" ;
VAL_ 362 RSPA_OSMirFoldReq 0 "Off" 1 "OS Mirror Fold" 2 "OS Mirror Unfold" 3 "Invalid" ;
VAL_ 362 RSPA_AvnModDis 0 "init" 1 "┴╓┬ў╕Ё╡х" 2 "├т┬ў╕Ё╡х" 3 "invalid" ;
VAL_ 362 RSPA_AvnSubViewDis 0 "init" 1 "No display" 2 "┤ы├╝└╠╣╠┴Ў ├т╖┬" 3 "invalid" ;
VAL_ 362 MRA_AVNDispSta 0 "Init" 1 "No display" 2 "MRA display" 3 "Invalid" ;
VAL_ 362 RSPA_DgtKeyVer 0 "None" 1 "Digital key type 1" 2 "Digital key type 2" 3 "RESERVED" 4 "RESERVED" 5 "RESERVED" 6 "RESERVED" 7 "RESERVED" ;
VAL_ 362 RSPA_AvnHmiDis 0 "none" 1 "Select operating mode" 2 "SMART Parking" 3 "REMOTE Parking" 4 "Parking completed" 5 "SMART Pull-out" 6 "Pull-out completed" 7 "RSPA cancelled - Read Manual" 8 "RSPA cancelled - Operate vehicle manually" 9 "Not working condition - Exceed Limit Speed" 10 "Searching for Parking space - Reduce speed under 20km" 11 "Check RSPA - Visit Tech Center" 12 "RESERVED" 13 "display Front camera - moving forward" 14 "display Rear camera - moving backward" 15 "RESERVED" 16 "RSPA paused - Check tailgate closed" 17 "RSPA paused - Remote control range exceeded" 18 "RSPA pasued - Hold down dedicated button on key fob" 19 "Parking completed - manually" 20 "Pull-out completed - manually" 21 "RESERVED" 22 "RSPA paused - Check all doors closed" 23 "RSPA paused - Check trunk closed" 24 "RSPA paused - RCCW" 25 "RSPA paused - Fasten seat belt on drivers side" 26 "Operation guide - Release brake" 27 "RSPA paused - Monitor surrounding area" 28 "RSPA cancelled - Trailer mode" 29 "RSPA cancelled - PDW Off" 30 "RSPA cancelled - over 20km" 31 "RSPA cancelled - not stop" 32 "RSPA cancelled - reverse movement" 33 "RSPA cancelled - narrow space" 34 "Not working condition - trailer mode" 35 "RSPA cancelled - Monitor surrounding area" 36 "RSPA cancelled - Check road condition" 37 "RSPA cancelled - Exceed operating distance" 38 "RSPA cancelled - Exceed operation time" 39 "RSPA cancelled - Detect cancel input" 40 "RSPA cancelled - Detect remote start button input" 41 "RSPA cancelled - Detect B" 42 "RSPA cancelled - Detect unfasten S" 43 "RSPA cancelled - Detect T" 44 "RSPA cancelled - Detect EPB operation" 45 "RSPA cancelled - Detect Pedal operation" 46 "RSPA cancelled - Hood open" 47 "RSPA cancelled - Detect S" 48 "RSPA cancelled - USS blockage" 49 "RSPA cancelled - Check SVM Camera" 50 "RESERVED" 51 "RESERVED" 52 "RESERVED" 53 "RESERVED" 54 "RESERVED" 55 "RESERVED" 56 "RESERVED" 57 "RESERVED" 58 "RESERVED" 59 "RESERVED" 60 "RESERVED" 61 "RESERVED" 62 "RESERVED" 63 "RESERVED" 64 "RESERVED" 65 "RESERVED" 66 "RESERVED" 67 "RESERVED" 68 "RESERVED" 69 "RESERVED" 70 "RESERVED" 71 "RESERVED" 72 "RESERVED" 73 "RESERVED" 74 "RESERVED" 75 "RESERVED" 76 "RESERVED" 77 "RESERVED" 78 "RESERVED" 79 "RESERVED" 80 "RESERVED" 81 "RESERVED" 82 "RESERVED" 83 "RESERVED" 84 "RESERVED" 85 "RESERVED" 86 "RESERVED" 87 "RESERVED" 88 "RESERVED" 89 "RESERVED" 90 "RESERVED" 91 "RESERVED" 92 "RESERVED" 93 "RESERVED" 94 "RESERVED" 95 "RESERVED" 96 "RESERVED" 97 "RESERVED" 98 "RESERVED" 99 "RESERVED" 100 "RESERVED" 101 "RESERVED" 102 "RESERVED" 103 "RESERVED" 104 "RESERVED" 105 "RESERVED" 106 "RESERVED" 107 "RESERVED" 108 "RESERVED" 109 "RESERVED" 110 "RESERVED" 111 "RESERVED" 112 "RESERVED" 113 "RESERVED" 114 "RESERVED" 115 "RESERVED" 116 "RESERVED" 117 "RESERVED" 118 "RESERVED" 119 "RESERVED" 120 "RESERVED" 121 "RESERVED" 122 "RESERVED" 123 "RESERVED" 124 "RESERVED" 125 "RESERVED" 126 "RESERVED" 127 "RESERVED" 128 "Searching for Parking space - Drive forwards" 129 "Searching Completed - Stop vehicle to park or Move forward" 130 "Select parking mode" 131 "Checking space - Stop the vehicle to check space" 132 "Checking completed - Select pull-out mode" 133 "Remote Moving F" 134 "under Remote Control" 135 "Remote Moving F" 136 "Operation guide - Reinput Parking Button" 137 "Operation guide - Reinput SMART Key Button" 138 "Not working condition - Read Manual" 139 "Not working condition - Steep road slope up" 140 "Not working condition - Steep road slope down" 141 "RSPA cancelled - Steep road slope up" 142 "RSPA cancelled - Steep road slope down" 143 "Not working condition - USS blockage" 144 "RSPA Guide Pop - up" 145 "RSPA cancelled ? DCT overtemp" 146 "Not working condition ? DCT overtemp" 147 "Checking Completed - Remote exit control" 148 "Select operating mode" 149 "Parking mode guide - SMART Parking" 150 "SMART Pull-out" 151 "Operation guide - Reinput Parking Button" 152 "RESERVED" 153 "RESERVED" 154 "RESERVED" 155 "RESERVED" 156 "RESERVED" 157 "RESERVED" 158 "RESERVED" 159 "RESERVED" 160 "RESERVED" 161 "RESERVED" 162 "RESERVED" 163 "RESERVED" 164 "RESERVED" 165 "RESERVED" 166 "RESERVED" 167 "RESERVED" 168 "park_in_search_slot_menu" 169 "park_in_mode_select_menu" 170 "park_in_process" 171 "remote_park_in_process" 172 "park_out_complete_screen" 173 "park_out_process" 174 "park_in_complete_Screen" 175 "park_out_direction_Select_menu" 176 "continue_park_menu" 177 "park_in_remote_mode_select_menu" 178 "RESERVED" 179 "RESERVED" 180 "RESERVED" 181 "RESERVED" 182 "RESERVED" 183 "RESERVED" 184 "RESERVED" 185 "RESERVED" 186 "RESERVED" 187 "RESERVED" 188 "RESERVED" 189 "RESERVED" 190 "RESERVED" 191 "RESERVED" 192 "RESERVED" 193 "RESERVED" 194 "RESERVED" 195 "RESERVED" 196 "RESERVED" 197 "RESERVED" 198 "RESERVED" 199 "RESERVED" 200 "RESERVED" 201 "RESERVED" 202 "RESERVED" 203 "RESERVED" 204 "RESERVED" 205 "RESERVED" 206 "RESERVED" 207 "RESERVED" 208 "RESERVED" 209 "RESERVED" 210 "RESERVED" 211 "RESERVED" 212 "RESERVED" 213 "RESERVED" 214 "RESERVED" 215 "RESERVED" 216 "RESERVED" 217 "RESERVED" 218 "RESERVED" 219 "RESERVED" 220 "RESERVED" 221 "RESERVED" 222 "RESERVED" 223 "RESERVED" 224 "RESERVED" 225 "RESERVED" 226 "RESERVED" 227 "RESERVED" 228 "RESERVED" 229 "RESERVED" 230 "RESERVED" 231 "RESERVED" 232 "RESERVED" 233 "RESERVED" 234 "RESERVED" 235 "RESERVED" 236 "RESERVED" 237 "RESERVED" 238 "RESERVED" 239 "RESERVED" 240 "RESERVED" 241 "RESERVED" 242 "RESERVED" 243 "RESERVED" 244 "RESERVED" 245 "RESERVED" 246 "RESERVED" 247 "RESERVED" 248 "RESERVED" 249 "RESERVED" 250 "RESERVED" 251 "RESERVED" 252 "RESERVED" 253 "RESERVED" 254 "RESERVED" 255 "Invalid" ;
VAL_ 362 MRA_AVNHMIDispSta 0 "Init" 1 "MRA Operation Guide ? Request shift R" 2 "MRA Operation Guide ? Hands Off" 3 "MRA Operation ? Backward Steering Control" 4 "MRA Operation ? Near Target Destinatoin" 5 "MRA Operation ? Near Limit Speed" 6 "MRA Cancelled ? Cancel Button input" 7 "MRA Cancelled ? Gear Shift" 8 "MRA Cancelled ? Exceed Limit Speed" 9 "MRA Cancelled ? Standstill Timeout" 10 "MRA Cancelled ? Steering wheel Override" 11 "MRA Cancelled ? Interrupt Safety Function" 12 "MRA Cancelled ? Wheel Slip" 13 "MRA Cancelled ? Path Deviation" 14 "MRA Cancelled - Trailor Mode" 15 "MRA Check System - Visit Service Center" 16 "MRA Finish ? Arrive Destination" 17 "MRA Cancelled ? Door Open" 18 "MRA Cancelled ? Trunk Open" 19 "MRA Cancelled ? Tailgate Open" 20 "MRA Cancelled ? Hood Open" 21 "MRA Cancelled ? Outside Mirror Folding" 22 "MRA Cancelled ? Refer to the Ownerбпs Manual" 23 "RESERVED" 24 "RESERVED" 25 "RESERVED" 26 "RESERVED" 27 "RESERVED" 28 "RESERVED" 29 "RESERVED" 30 "RESERVED" 31 "RESERVED" 32 "RESERVED" 33 "Continue_MRA_menu" 34 "MRA_active_distance_arrow_steering" 35 "0x23~0xFE:RESERVED" 254 "0x23~0xFE:RESERVED" 255 "Invalid" ;
VAL_ 2281701472 L_BDC_FD_ROA_Crc1Val 0 "0x0x0~0xFFFF:CRCValue" 65535 "0x0x0~0xFFFF:CRCValue" ;
VAL_ 2281701472 L_BDC_FD_ROA_AlvCnt1Val 0 "0x0x0~0xFF:AlvCntValue" 255 "0x0x0~0xFF:AlvCntValue" ;
VAL_ 2281701472 ROA_SnsrRunReq 0 "Default" 1 "Init" 2 "Start" 3 "Stop" 4 "Start Delay" 5 "RESERVED" 6 "RESERVED" 7 "Error indicator" ;
VAL_ 2281701472 ROA_DiaReq 0 "Default" 1 "Diagnosis (system info)" 2 "Request of update (Refresh parameter)" 3 "Parameter download" 4 "RESERVED" 5 "RESERVED" 6 "RESERVED" 7 "Error indicator" ;
VAL_ 2281701472 ROA_Region_Opt 0 "Non Euro NCAP CPD" 1 "Euro NCAP CPD" 2 "RESERVED" 3 "Error Indicator" ;
VAL_ 2281701472 ROA_EngSta 0 "Off" 1 "Engine Running" 2 "RESERVED" 3 "Error Indicator" ;
VAL_ 2281701521 L_DHRR_FD_Crc20Val 0 "0x0x0~0xFFFF:CRCValue" 65535 "0x0x0~0xFFFF:CRCValue" ;
VAL_ 2281701521 L_DHRR_FD_AlvCnt20Val 0 "0x0x0~0xFF:AlvCntValue" 255 "0x0x0~0xFF:AlvCntValue" ;
VAL_ 2281701521 DHRR_Status 0 "Idle" 1 "NFC_Comm" 2 "NFC_Comm Complete" 3 "RESERVED" 4 "RESERVED" 5 "RESERVED" 6 "RESERVED" 7 "invalid" ;
VAL_ 2281701521 DHRR_Rain_Sta 0 "Off" 1 "Rain" ;
VAL_ 2281701521 DHRR_PhnDet_Sta 0 "Default" 1 "On" 2 "Off" 3 "Invalid" ;
VAL_ 2281701521 DHRR_TglDet_Sta 0 "Off" 1 "Touch" ;
VAL_ 2281701521 DHRR_UnlckDet_Sta 0 "Off" 1 "Unlock" ;
VAL_ 2281701521 DHRR_LckDet_Sta 0 "Off" 1 "Lock" ;
VAL_ 2281701521 DHRR_ResetOpsta 0 "Normal" 1 "Reset Complete" 2 "Reset Fail" 3 "RESERVED" ;
VAL_ 2281701521 DHRR_Diag_Sta 0 "No Error" 1 "DHS Internal Error" 2 "NFC Antenna Error" 4 "Overheating NFC" 8 "Overheating Lighting" 16 "Undervoltage" 32 "Overvoltage" 33 "0x21~0xFF:RESERVED" 255 "0x21~0xFF:RESERVED" ;
VAL_ 2281701520 L_DHR_FD_Crc20Val 0 "0x0x0~0xFFFF:CRCValue" 65535 "0x0x0~0xFFFF:CRCValue" ;
VAL_ 2281701520 L_DHR_FD_AlvCnt20Val 0 "0x0x0~0xFF:AlvCntValue" 255 "0x0x0~0xFF:AlvCntValue" ;
VAL_ 2281701520 DHR_Status 0 "Idle" 1 "NFC_Comm" 2 "NFC_Comm Complete" 3 "RESERVED" 4 "RESERVED" 5 "RESERVED" 6 "RESERVED" 7 "invalid" ;
VAL_ 2281701520 DHR_Rain_Sta 0 "Off" 1 "Rain" ;
VAL_ 2281701520 DHR_PhnDet_Sta 0 "Default" 1 "On" 2 "Off" 3 "Invalid" ;
VAL_ 2281701520 DHR_TglDet_Sta 0 "Off" 1 "Touch" ;
VAL_ 2281701520 DHR_UnlckDet_Sta 0 "Off" 1 "Unlock" ;
VAL_ 2281701520 DHR_LckDet_Sta 0 "Off" 1 "Lock" ;
VAL_ 2281701520 DHR_ResetOpSta 0 "Normal" 1 "Reset Complete" 2 "Reset Fail" 3 "RESERVED" ;
VAL_ 2281701520 DHR_Diag_Sta 0 "No Error" 1 "DHS Internal Error" 2 "NFC Antenna Error" 4 "Overheating NFC" 8 "Overheating Lighting" 16 "Undervoltage" 32 "Overvoltage" 33 "0x21~0xFF:RESERVED" 255 "0x21~0xFF:RESERVED" ;
VAL_ 2521143297 L_UWB_BLE_SLV_FD_Crc12Val 0 "0x0x0~0xFFFF:CRCValue" 65535 "0x0x0~0xFFFF:CRCValue" ;
VAL_ 2521143297 L_UWB_BLE_SLV_FD_AlvCnt12Val 0 "0x0x0~0xFF:AlvCntValue" 255 "0x0x0~0xFF:AlvCntValue" ;
VAL_ 2281701504 L_DHL_FD_Crc20Val 0 "0x0x0~0xFFFF:CRCValue" 65535 "0x0x0~0xFFFF:CRCValue" ;
VAL_ 2281701504 L_DHL_FD_AlvCnt20Val 0 "0x0x0~0xFF:AlvCntValue" 255 "0x0x0~0xFF:AlvCntValue" ;
VAL_ 2281701504 DHL_Status 0 "Idle" 1 "NFC_Comm" 2 "NFC_Comm Complete" 3 "RESERVED" 4 "RESERVED" 5 "RESERVED" 6 "RESERVED" 7 "invalid" ;
VAL_ 2281701504 DHL_Rain_Sta 0 "Off" 1 "Rain" ;
VAL_ 2281701504 DHL_PhnDet_Sta 0 "Default" 1 "On" 2 "Off" 3 "Invalid" ;
VAL_ 2281701504 DHL_TglDet_Sta 0 "Off" 1 "Touch" ;
VAL_ 2281701504 DHL_UnlckDet_Sta 0 "Off" 1 "Unlock" ;
VAL_ 2281701504 DHL_LckDet_Sta 0 "Off" 1 "Lock" ;
VAL_ 2281701504 DHL_ResetOpsta 0 "Normal" 1 "Reset Complete" 2 "Reset Fail" 3 "RESERVED" ;
VAL_ 2281701504 DHL_Diag_Sta 0 "No Error" 1 "DHS Internal Error" 2 "NFC Antenna Error" 4 "Overheating NFC" 8 "Overheating Lighting" 16 "Undervoltage" 32 "Overvoltage" 33 "0x21~0xFF:RESERVED" 255 "0x21~0xFF:RESERVED" ;
VAL_ 2281701505 L_DHRL_FD_Crc20Val 0 "0x0x0~0xFFFF:CRCValue" 65535 "0x0x0~0xFFFF:CRCValue" ;
VAL_ 2281701505 L_DHRL_FD_AlvCnt20Val 0 "0x0x0~0xFF:AlvCntValue" 255 "0x0x0~0xFF:AlvCntValue" ;
VAL_ 2281701505 DHRL_Status 0 "Idle" 1 "NFC_Comm" 2 "NFC_Comm Complete" 3 "RESERVED" 4 "RESERVED" 5 "RESERVED" 6 "RESERVED" 7 "invalid" ;
VAL_ 2281701505 DHRL_Rain_Sta 0 "Off" 1 "Rain" ;
VAL_ 2281701505 DHRL_PhnDet_Sta 0 "Default" 1 "On" 2 "Off" 3 "Invalid" ;
VAL_ 2281701505 DHRL_TglDet_Sta 0 "Off" 1 "Touch" ;
VAL_ 2281701505 DHRL_UnlckDet_Sta 0 "Off" 1 "Unlock" ;
VAL_ 2281701505 DHRL_LckDet_Sta 0 "Off" 1 "Lock" ;
VAL_ 2281701505 DHRL_ResetOpSta 0 "Normal" 1 "Reset Complete" 2 "Reset Fail" 3 "RESERVED" ;
VAL_ 2281701505 DHRL_Diag_Sta 0 "No Error" 1 "DHS Internal Error" 2 "NFC Antenna Error" 4 "Overheating NFC" 8 "Overheating Lighting" 16 "Undervoltage" 32 "Overvoltage" 33 "0x21~0xFF:RESERVED" 255 "0x21~0xFF:RESERVED" ;
VAL_ 2525340417 L_UWB_FL_FD_Crc7Val 0 "0x0x0~0xFFFF:CRCValue" 65535 "0x0x0~0xFFFF:CRCValue" ;
VAL_ 2525340417 L_UWB_FL_FD_AlvCnt7Val 0 "0x0x0~0xFF:AlvCntValue" 255 "0x0x0~0xFF:AlvCntValue" ;
VAL_ 2521143809 L_UWB_BLE_SLV_FD_Crc14Val 0 "0x0x0~0xFFFF:CRCValue" 65535 "0x0x0~0xFFFF:CRCValue" ;
VAL_ 2521143809 L_UWB_BLE_SLV_FD_AlvCnt14Val 0 "0x0x0~0xFF:AlvCntValue" 255 "0x0x0~0xFF:AlvCntValue" ;
VAL_ 2281701553 L_UWB_BLE_SLV_FD_Crc21Val 0 "0x0x0~0xFFFF:CRCValue" 65535 "0x0x0~0xFFFF:CRCValue" ;
VAL_ 2281701553 L_UWB_BLE_SLV_FD_AlvCnt21Val 0 "0x0x0~0xFF:AlvCntValue" 255 "0x0x0~0xFF:AlvCntValue" ;
VAL_ 2281701553 SLV_UWB_Status1 0 "Default" 1 "No_Ranging" 2 "URSK_Stored" 3 "UWB_Session_Setup" 4 "Ranging_Start(Not_In_Sync)" 5 "Ranging_Start(In_Sync)" 6 "Ranging_Stop(Max_Signal_Missed)" 7 "Fob_Ranging" 8 "RESERVED" 9 "RESERVED" 10 "RESERVED" 11 "RESERVED" 12 "RESERVED" 13 "RESERVED" 14 "RESERVED" 15 "Invalid" ;
VAL_ 2281701553 SLV_UWB_Status2 0 "Default" 1 "No_Ranging" 2 "URSK_Stored" 3 "UWB_Session_Setup" 4 "Ranging_Start(Not_In_Sync)" 5 "Ranging_Start(In_Sync)" 6 "Ranging_Stop(Max_Signal_Missed)" 7 "Fob_Ranging" 8 "RESERVED" 9 "RESERVED" 10 "RESERVED" 11 "RESERVED" 12 "RESERVED" 13 "RESERVED" 14 "RESERVED" 15 "Invalid" ;
VAL_ 2281701553 SLV_UWB_Status3 0 "Default" 1 "No_Ranging" 2 "URSK_Stored" 3 "UWB_Session_Setup" 4 "Ranging_Start(Not_In_Sync)" 5 "Ranging_Start(In_Sync)" 6 "Ranging_Stop(Max_Signal_Missed)" 7 "Fob_Ranging" 8 "RESERVED" 9 "RESERVED" 10 "RESERVED" 11 "RESERVED" 12 "RESERVED" 13 "RESERVED" 14 "RESERVED" 15 "Invalid" ;
VAL_ 2281701553 SLV_UWB_Status4 0 "Default" 1 "No_Ranging" 2 "URSK_Stored" 3 "UWB_Session_Setup" 4 "Ranging_Start(Not_In_Sync)" 5 "Ranging_Start(In_Sync)" 6 "Ranging_Stop(Max_Signal_Missed)" 7 "Fob_Ranging" 8 "RESERVED" 9 "RESERVED" 10 "RESERVED" 11 "RESERVED" 12 "RESERVED" 13 "RESERVED" 14 "RESERVED" 15 "Invalid" ;
VAL_ 2281701553 SLV_UWB_Status5 0 "Default" 1 "No_Ranging" 2 "URSK_Stored" 3 "UWB_Session_Setup" 4 "Ranging_Start(Not_In_Sync)" 5 "Ranging_Start(In_Sync)" 6 "Ranging_Stop(Max_Signal_Missed)" 7 "Fob_Ranging" 8 "RESERVED" 9 "RESERVED" 10 "RESERVED" 11 "RESERVED" 12 "RESERVED" 13 "RESERVED" 14 "RESERVED" 15 "Invalid" ;
VAL_ 2281701553 SLV_UWB_Status6 0 "Default" 1 "No_Ranging" 2 "URSK_Stored" 3 "UWB_Session_Setup" 4 "Ranging_Start(Not_In_Sync)" 5 "Ranging_Start(In_Sync)" 6 "Ranging_Stop(Max_Signal_Missed)" 7 "Fob_Ranging" 8 "RESERVED" 9 "RESERVED" 10 "RESERVED" 11 "RESERVED" 12 "RESERVED" 13 "RESERVED" 14 "RESERVED" 15 "Invalid" ;
VAL_ 2281701553 SLV_UWB_Status7 0 "Default" 1 "No_Ranging" 2 "URSK_Stored" 3 "UWB_Session_Setup" 4 "Ranging_Start(Not_In_Sync)" 5 "Ranging_Start(In_Sync)" 6 "Ranging_Stop(Max_Signal_Missed)" 7 "Fob_Ranging" 8 "RESERVED" 9 "RESERVED" 10 "RESERVED" 11 "RESERVED" 12 "RESERVED" 13 "RESERVED" 14 "RESERVED" 15 "Invalid" ;
VAL_ 2281701553 SLV_UWB_Status8 0 "Default" 1 "No_Ranging" 2 "URSK_Stored" 3 "UWB_Session_Setup" 4 "Ranging_Start(Not_In_Sync)" 5 "Ranging_Start(In_Sync)" 6 "Ranging_Stop(Max_Signal_Missed)" 7 "Fob_Ranging" 8 "RESERVED" 9 "RESERVED" 10 "RESERVED" 11 "RESERVED" 12 "RESERVED" 13 "RESERVED" 14 "RESERVED" 15 "Invalid" ;
VAL_ 2281701553 SLV_UWB_Status9 0 "Default" 1 "No_Ranging" 2 "URSK_Stored" 3 "UWB_Session_Setup" 4 "Ranging_Start(Not_In_Sync)" 5 "Ranging_Start(In_Sync)" 6 "Ranging_Stop(Max_Signal_Missed)" 7 "Fob_Ranging" 8 "RESERVED" 9 "RESERVED" 10 "RESERVED" 11 "RESERVED" 12 "RESERVED" 13 "RESERVED" 14 "RESERVED" 15 "Invalid" ;
VAL_ 2281701553 SLV_UWB_Status10 0 "Default" 1 "No_Ranging" 2 "URSK_Stored" 3 "UWB_Session_Setup" 4 "Ranging_Start(Not_In_Sync)" 5 "Ranging_Start(In_Sync)" 6 "Ranging_Stop(Max_Signal_Missed)" 7 "Fob_Ranging" 8 "RESERVED" 9 "RESERVED" 10 "RESERVED" 11 "RESERVED" 12 "RESERVED" 13 "RESERVED" 14 "RESERVED" 15 "Invalid" ;
VAL_ 2281701553 SLV_UWB_Status11 0 "Default" 1 "No_Ranging" 2 "URSK_Stored" 3 "UWB_Session_Setup" 4 "Ranging_Start(Not_In_Sync)" 5 "Ranging_Start(In_Sync)" 6 "Ranging_Stop(Max_Signal_Missed)" 7 "Fob_Ranging" 8 "RESERVED" 9 "RESERVED" 10 "RESERVED" 11 "RESERVED" 12 "RESERVED" 13 "RESERVED" 14 "RESERVED" 15 "Invalid" ;
VAL_ 2281701553 SLV_UWB_Status12 0 "Default" 1 "No_Ranging" 2 "URSK_Stored" 3 "UWB_Session_Setup" 4 "Ranging_Start(Not_In_Sync)" 5 "Ranging_Start(In_Sync)" 6 "Ranging_Stop(Max_Signal_Missed)" 7 "Fob_Ranging" 8 "RESERVED" 9 "RESERVED" 10 "RESERVED" 11 "RESERVED" 12 "RESERVED" 13 "RESERVED" 14 "RESERVED" 15 "Invalid" ;
VAL_ 2281701553 SLV_UWB_Status13 0 "Default" 1 "No_Ranging" 2 "URSK_Stored" 3 "UWB_Session_Setup" 4 "Ranging_Start(Not_In_Sync)" 5 "Ranging_Start(In_Sync)" 6 "Ranging_Stop(Max_Signal_Missed)" 7 "Fob_Ranging" 8 "RESERVED" 9 "RESERVED" 10 "RESERVED" 11 "RESERVED" 12 "RESERVED" 13 "RESERVED" 14 "RESERVED" 15 "Invalid" ;
VAL_ 2281701553 SLV_UWB_Status14 0 "Default" 1 "No_Ranging" 2 "URSK_Stored" 3 "UWB_Session_Setup" 4 "Ranging_Start(Not_In_Sync)" 5 "Ranging_Start(In_Sync)" 6 "Ranging_Stop(Max_Signal_Missed)" 7 "Fob_Ranging" 8 "RESERVED" 9 "RESERVED" 10 "RESERVED" 11 "RESERVED" 12 "RESERVED" 13 "RESERVED" 14 "RESERVED" 15 "Invalid" ;
VAL_ 2281701553 SLV_UWB_Status15 0 "Default" 1 "No_Ranging" 2 "URSK_Stored" 3 "UWB_Session_Setup" 4 "Ranging_Start(Not_In_Sync)" 5 "Ranging_Start(In_Sync)" 6 "Ranging_Stop(Max_Signal_Missed)" 7 "Fob_Ranging" 8 "RESERVED" 9 "RESERVED" 10 "RESERVED" 11 "RESERVED" 12 "RESERVED" 13 "RESERVED" 14 "RESERVED" 15 "Invalid" ;
VAL_ 2281701553 SLV_UWB_Status16 0 "Default" 1 "No_Ranging" 2 "URSK_Stored" 3 "UWB_Session_Setup" 4 "Ranging_Start(Not_In_Sync)" 5 "Ranging_Start(In_Sync)" 6 "Ranging_Stop(Max_Signal_Missed)" 7 "Fob_Ranging" 8 "RESERVED" 9 "RESERVED" 10 "RESERVED" 11 "RESERVED" 12 "RESERVED" 13 "RESERVED" 14 "RESERVED" 15 "Invalid" ;
